VERSION ""

NS_ :

BS_:

BU_: TCM HCM IPMA_ADAS PSCM ABS_ESC TCCM TCM_DSL PCM_HEV PCM ECM_HEVDSL ECM_HEV ECM_Diesel ECM SIMA_DLCS BCMD_IPDB VDM CMR_DSMC SOBDMC_HPCM CHCM GWM _delete AWD_DLCM GENERIC TSTR

BO_ 2610126865 OTAPhysSOBDMCtoGWM_FD1: 64 SOBDMC_HPCM
 SG_ OTAPhysSOBDMCtoGWM_ECG : 7|29@0+ (1,0) [0|536870911] "unitless"  GWM

BO_ 2610971864 PARSEDPhysGWMtoSOBDMC_FD1: 64 GWM
 SG_ PARSEDPhysGWM_ECGtoSOBDMC : 7|29@0+ (1,0) [0|536870911] "unitless"  SOBDMC_HPCM

BO_ 2611175441 PARSEDPhysSOBDMCtoGWM_FD1: 64 SOBDMC_HPCM
 SG_ PARSEDPhysSOBDMCtoGWM_ECG : 7|29@0+ (1,0) [0|536870911] "unitless"  GWM

BO_ 2610126946 OTAPhysSODLtoGWM_ECG: 64 IPMA_ADAS
 SG_ OTAPhysSODLtoGWM_ECG : 7|29@0+ (1,0) [0|536870911] "unitless"  GWM

BO_ 2610006232 OTAPhysGWM_ECGtoSODL: 64 GWM
 SG_ OTAPhysGWM_ECGtoSODL : 7|29@0+ (1,0) [0|536870911] "unitless"  IPMA_ADAS

BO_ 1993 TesterPhysicalResCMR_DSMC: 64 CMR_DSMC
 SG_ TesterPhysicalResCMR_DSMC : 7|64@0+ (1,0) [0|1.84467E+019] "unitless"  TSTR

BO_ 1985 TesterPhysicalReqCMR_DSMC: 64 TSTR
 SG_ TesterPhysicalReqCMR_DSMC : 7|64@0+ (1,0) [0|1.84467E+019] "unitless"  CMR_DSMC

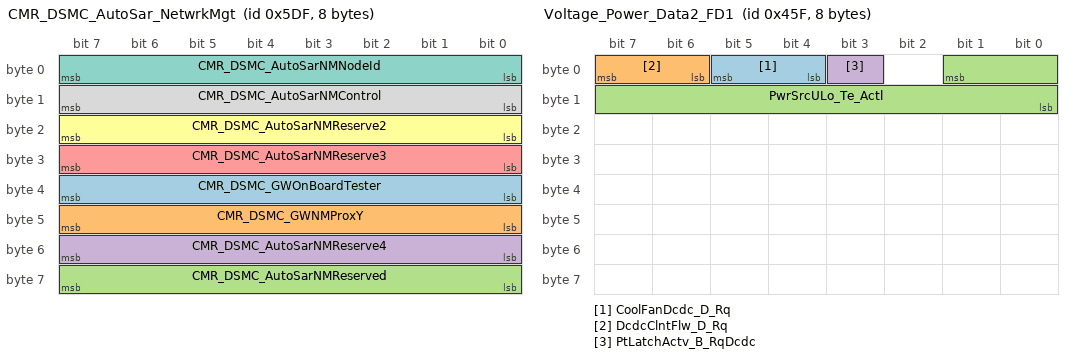
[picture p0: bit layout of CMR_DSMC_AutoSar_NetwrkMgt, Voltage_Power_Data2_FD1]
BO_ 1503 CMR_DSMC_AutoSar_NetwrkMgt: 8 CMR_DSMC
 SG_ CMR_DSMC_GWOnBoardTester : 39|8@0+ (1,0) [0|255] "unitless"  GENERIC
 SG_ CMR_DSMC_GWNMProxY : 47|8@0+ (1,0) [0|255] "unitless"  GENERIC
 SG_ CMR_DSMC_AutoSarNMReserved : 63|8@0+ (1,0) [0|255] "unitless"  GENERIC
 SG_ CMR_DSMC_AutoSarNMReserve4 : 55|8@0+ (1,0) [0|255] "unitless"  GENERIC
 SG_ CMR_DSMC_AutoSarNMReserve3 : 31|8@0+ (1,0) [0|255] "unitless"  GENERIC
 SG_ CMR_DSMC_AutoSarNMReserve2 : 23|8@0+ (1,0) [0|255] "unitless"  GENERIC
 SG_ CMR_DSMC_AutoSarNMNodeId : 7|8@0+ (1,0) [0|255] "unitless"  GENERIC
 SG_ CMR_DSMC_AutoSarNMControl : 15|8@0+ (1,0) [0|255] "unitless"  GENERIC

BO_ 1119 Voltage_Power_Data2_FD1: 8 DCDC_HEV
 SG_ CoolFanDcdc_D_Rq : 5|2@0+ (1,0) [0|3] "SED"  SOBDMC_HPCM
 SG_ DcdcClntFlw_D_Rq : 7|2@0+ (1,0) [0|3] "SED"  SOBDMC_HPCM
 SG_ PwrSrcULo_Te_Actl : 1|10@0+ (0.5,-50) [-50|460.5] "degC"  ECM_Diesel,ECM_HEV,ECM_HEVDSL,PCM_HEV
 SG_ PtLatchActv_B_RqDcdc : 3|1@0+ (1,0) [0|1] "SED"  ECM_Diesel,ECM_HEV,ECM_HEVDSL,PCM_HEV

BO_ 2022 TesterPhysicalReqSOBDMC_FD: 64 TSTR
 SG_ TesterPhysicalReqSOBDMC : 7|64@0+ (1,0) [0|1.84467E+019] "unitless"  ECM,ECM_Diesel,ECM_HEVDSL,SOBDMC_HPCM

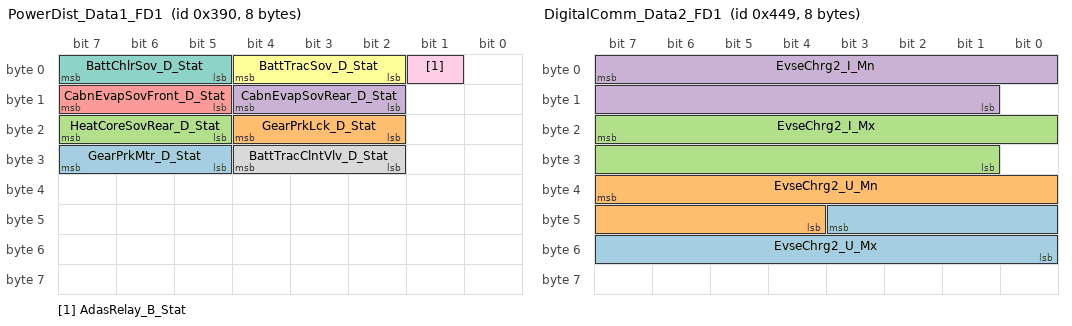
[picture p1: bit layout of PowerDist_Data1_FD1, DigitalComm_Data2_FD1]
BO_ 912 PowerDist_Data1_FD1: 8 GWM
 SG_ GearPrkMtr_D_Stat : 31|3@0+ (1,0) [0|7] "SED"  SOBDMC_HPCM,BCMD_IPDB
 SG_ GearPrkLck_D_Stat : 20|3@0+ (1,0) [0|7] "SED"  SOBDMC_HPCM,BCMD_IPDB
 SG_ HeatCoreSovRear_D_Stat : 23|3@0+ (1,0) [0|7] "SED"  SOBDMC_HPCM
 SG_ CabnEvapSovRear_D_Stat : 12|3@0+ (1,0) [0|7] "SED"  SOBDMC_HPCM
 SG_ CabnEvapSovFront_D_Stat : 15|3@0+ (1,0) [0|7] "SED"  SOBDMC_HPCM,BCMD_IPDB
 SG_ BattTracSov_D_Stat : 4|3@0+ (1,0) [0|7] "SED"  SOBDMC_HPCM
 SG_ BattChlrSov_D_Stat : 7|3@0+ (1,0) [0|7] "SED"  SOBDMC_HPCM,BCMD_IPDB
 SG_ BattTracClntVlv_D_Stat : 28|3@0+ (1,0) [0|7] "SED"  SOBDMC_HPCM,BCMD_IPDB
 SG_ AdasRelay_B_Stat : 1|1@0+ (1,0) [0|1] "SED"  GENERIC

BO_ 66 Global_PATS_Ctrl_Info2_FD1: 8 GWM
 SG_ immoControlData_T2 : 15|40@0+ (1,0) [0|1099511627775] "Encrypted"  GWM,SOBDMC_HPCM
 SG_ immoControlCmd_T2 : 7|3@0+ (1,0) [0|7] "SED"  GWM,SOBDMC_HPCM

BO_ 651 TCU_Send_Signals_FD1: 8 TCU_FB5
 SG_ TelematicsSrvc_D_St : 47|3@0+ (1,0) [0|7] "SED"  SOBDMC_HPCM
 SG_ EmgcyCallMute_D_Stat : 39|3@0+ (1,0) [0|7] "SED"  GENERIC

BO_ 1097 DigitalComm_Data2_FD1: 8 OBCC
 SG_ EvseChrg2_U_Mx : 43|12@0+ (0.5,0) [0|2046.5] "volt"  SOBDMC_HPCM
 SG_ EvseChrg2_U_Mn : 39|12@0+ (0.5,0) [0|2046.5] "volt"  GENERIC
 SG_ EvseChrg2_I_Mx : 23|15@0+ (0.05,0) [0|1638.25] "ampere"  SOBDMC_HPCM
 SG_ EvseChrg2_I_Mn : 7|15@0+ (0.05,0) [0|1638.25] "ampere"  GENERIC

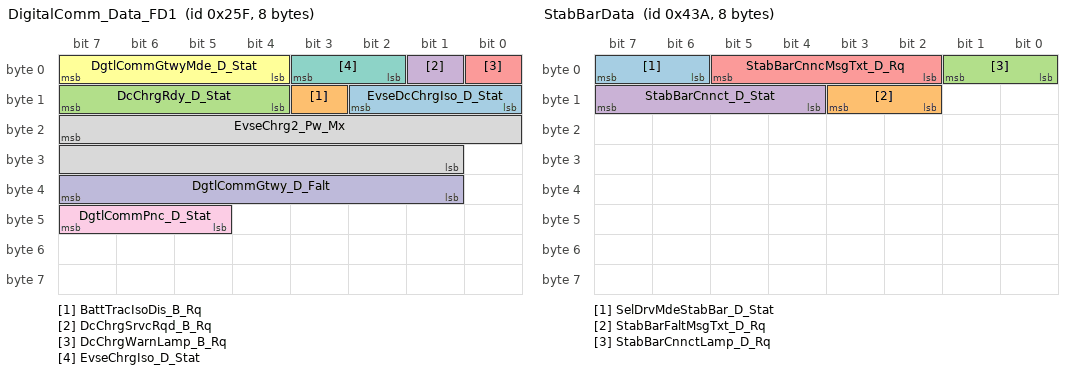
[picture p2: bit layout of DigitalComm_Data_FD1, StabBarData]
BO_ 607 DigitalComm_Data_FD1: 8 OBCC
 SG_ EvseDcChrgIso_D_Stat : 10|3@0+ (1,0) [0|7] "SED"  GENERIC
 SG_ BattTracIsoDis_B_Rq : 11|1@0+ (1,0) [0|1] "SED"  GENERIC
 SG_ DcChrgRdy_D_Stat : 15|4@0+ (1,0) [0|15] "SED"  SOBDMC_HPCM
 SG_ DcChrgSrvcRqd_B_Rq : 1|1@0+ (1,0) [0|1] "SED"  GENERIC
 SG_ DcChrgWarnLamp_B_Rq : 0|1@0+ (1,0) [0|1] "SED"  GENERIC
 SG_ DgtlCommGtwyMde_D_Stat : 7|4@0+ (1,0) [0|15] "SED"  GENERIC
 SG_ EvseChrgIso_D_Stat : 3|2@0+ (1,0) [0|3] "SED"  GENERIC
 SG_ EvseChrg2_Pw_Mx : 23|15@0+ (50,0) [0|1638250] "watts"  SOBDMC_HPCM
 SG_ DgtlCommPnc_D_Stat : 47|3@0+ (1,0) [0|7] "SED"  GENERIC
 SG_ DgtlCommGtwy_D_Falt : 39|7@0+ (1,0) [0|63] "SED"  GENERIC

BO_ 2609955032 OTAPhysGWM_ECGtoPSCM: 64 GWM
 SG_ OTAPhysGWM_ECGtoPSCM : 7|29@0+ (1,0) [0|536870911] "unitless"  PSCM

BO_ 2610126896 OTAPhysPSCMtoGWM_ECG: 64 PSCM
 SG_ OTAPhysPSCMtoGWM_ECG : 7|29@0+ (1,0) [0|536870911] "unitless"  GWM

BO_ 2611003608 PARSEDPhysGWM_ECGtoPSCM: 64 GWM
 SG_ PARSEDPhysGWM_ECGtoPSCM : 7|29@0+ (1,0) [0|536870911] "unitless"  PSCM

BO_ 2612224048 PARSEDPushPSCMtoGWM_ECG: 8 PSCM
 SG_ PARSEDPushPSCMtoGWM_ECG : 7|29@0+ (1,0) [0|536870911] "unitless"  GWM

BO_ 2611175472 PARSEDPhysPSCMtoGWM_ECG: 64 PSCM
 SG_ PARSEDPhysPSCMtoGWM_ECG : 7|29@0+ (1,0) [0|536870911] "unitless"  GWM

BO_ 1150 LocationServices_Data1_FD1: 8 APIM
 SG_ LocationServices_1 : 7|64@0+ (1,0) [0|1.84467440737096E+019] "unitless"  SOBDMC_HPCM,HCM,IPMA_ADAS,ABS_ESC

BO_ 2612224033 PARSEDPushIPMAtoGWM_ECG: 8 IPMA_ADAS
 SG_ PARSEDPushIPMAtoGWM_ECG : 7|29@0+ (1,0) [0|536870911] "unitless"  GWM

BO_ 2609939672 OTAPhysGWM_ECGtoIPMA: 64 GWM
 SG_ OTAPhysGWM_ECGtoIPMA : 7|29@0+ (1,0) [0|536870911] "unitless"  IPMA_ADAS

BO_ 2610126881 OTAPhysIPMAtoGWM_ECG: 64 IPMA_ADAS
 SG_ OTAPhysIPMAtoGWM_ECG : 7|29@0+ (1,0) [0|536870911] "unitless"  GWM

BO_ 2612043992 PARSEDPushFcGWM_ECGtoABS: 8 GWM
 SG_ PARSEDPushFcGWM_ECGtoABS : 7|29@0+ (1,0) [0|536870911] "unitless"  ABS_ESC

BO_ 2610995416 PARSEDPhysGWM_ECGtoABS: 64 GWM
 SG_ PARSEDPhysGWM_ECGtoABS : 7|29@0+ (1,0) [0|536870911] "unitless"  ABS_ESC

BO_ 2612224040 PARSEDPushABStoGWM_ECG: 8 ABS_ESC
 SG_ PARSEDPushABStoGWM_ECG : 7|29@0+ (1,0) [0|536870911] "unitless"  GWM

BO_ 2611175464 PARSEDPhysABStoGWM_ECG: 64 ABS_ESC
 SG_ PARSEDPhysABStoGWM_ECG : 7|29@0+ (1,0) [0|536870911] "Unitless"  GWM

BO_ 1082 StabBarData: 8 CHCM
 SG_ SelDrvMdeStabBar_D_Stat : 7|2@0+ (1,0) [0|3] "SED"  ABS_ESC
 SG_ StabBarFaltMsgTxt_D_Rq : 11|2@0+ (1,0) [0|3] "SED"  GWM
 SG_ StabBarCnnctLamp_D_Rq : 1|2@0+ (1,0) [0|3] "SED"  SIMA_DLCS,GWM
 SG_ StabBarCnnct_D_Stat : 15|4@0+ (1,0) [0|15] "SED"  VDM,GWM,ABS_ESC
 SG_ StabBarCnncMsgTxt_D_Rq : 5|4@0+ (1,0) [0|15] "SED"  GWM

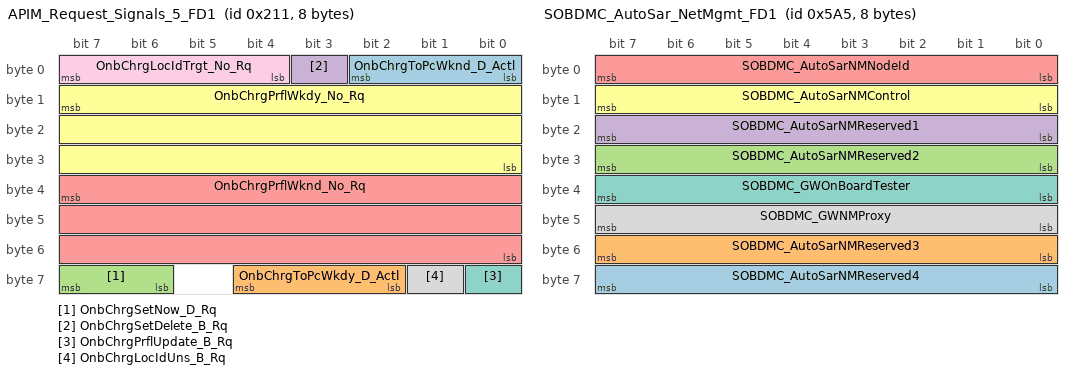
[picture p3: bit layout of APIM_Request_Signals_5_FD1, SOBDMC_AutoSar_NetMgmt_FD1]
BO_ 529 APIM_Request_Signals_5_FD1: 8 APIM
 SG_ OnbChrgToPcWknd_D_Actl : 2|3@0+ (1,0) [0|7] "percent"  SOBDMC_HPCM
 SG_ OnbChrgToPcWkdy_D_Actl : 60|3@0+ (1,0) [0|7] "percent"  SOBDMC_HPCM
 SG_ OnbChrgSetNow_D_Rq : 63|2@0+ (1,0) [0|3] "SED"  SOBDMC_HPCM
 SG_ OnbChrgSetDelete_B_Rq : 3|1@0+ (1,0) [0|1] "SED"  SOBDMC_HPCM
 SG_ OnbChrgPrflWknd_No_Rq : 39|24@0+ (1,0) [0|16777215] "unitless"  SOBDMC_HPCM
 SG_ OnbChrgPrflWkdy_No_Rq : 15|24@0+ (1,0) [0|16777215] "unitless"  SOBDMC_HPCM
 SG_ OnbChrgPrflUpdate_B_Rq : 56|1@0+ (1,0) [0|1] "SED"  SOBDMC_HPCM
 SG_ OnbChrgLocIdUns_B_Rq : 57|1@0+ (1,0) [0|1] "SED"  SOBDMC_HPCM
 SG_ OnbChrgLocIdTrgt_No_Rq : 7|4@0+ (1,0) [0|15] "Unitless"  SOBDMC_HPCM

BO_ 1679 SOBDMC_RapidData_Resp4_FD1: 8 SOBDMC_HPCM
 SG_ UUDTSOBDMCResponse4 : 7|64@0+ (1,0) [0|1.84467440737096E+019] "unitless"  TSTR

BO_ 1678 SOBDMC_RapidData_Resp3_FD1: 8 SOBDMC_HPCM
 SG_ UUDTSOBDMCResponse3 : 7|64@0+ (1,0) [0|1.84467440737096E+019] "unitless"  TSTR

BO_ 1677 SOBDMC_RapidData_Resp2_FD1: 8 SOBDMC_HPCM
 SG_ UUDTSOBDMCResponse2 : 7|64@0+ (1,0) [0|1.84467440737096E+019] "unitless"  TSTR

BO_ 1676 SOBDMC_RapidData_Resp1_FD1: 8 SOBDMC_HPCM
 SG_ UUDTSOBDMCResponse1 : 7|64@0+ (1,0) [0|1.84467440737096E+019] "unitless"  TSTR

BO_ 1445 SOBDMC_AutoSar_NetMgmt_FD1: 8 SOBDMC_HPCM
 SG_ SOBDMC_AutoSarNMReserved4 : 63|8@0+ (1,0) [0|255] "unitless"  ECM_HEV
 SG_ SOBDMC_AutoSarNMReserved3 : 55|8@0+ (1,0) [0|255] "unitless"  ECM_HEV
 SG_ SOBDMC_AutoSarNMReserved2 : 31|8@0+ (1,0) [0|255] "unitless"  ECM_HEV
 SG_ SOBDMC_AutoSarNMReserved1 : 23|8@0+ (1,0) [0|255] "unitless"  ECM_HEV
 SG_ SOBDMC_AutoSarNMNodeId : 7|8@0+ (1,0) [0|255] "unitless"  ECM_HEV
 SG_ SOBDMC_AutoSarNMControl : 15|8@0+ (1,0) [0|255] "unitless"  ECM_HEV
 SG_ SOBDMC_GWOnBoardTester : 39|8@0+ (1,0) [0|255] "unitless"  ECM_HEV
 SG_ SOBDMC_GWNMProxy : 47|8@0+ (1,0) [0|255] "unitless"  ECM_HEV

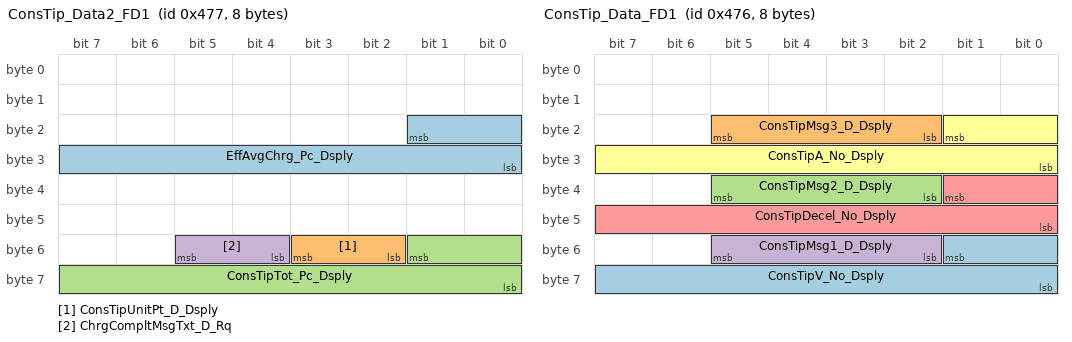
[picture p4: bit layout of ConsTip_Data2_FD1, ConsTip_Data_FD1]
BO_ 1143 ConsTip_Data2_FD1: 8 SOBDMC_HPCM
 SG_ EffAvgChrg_Pc_Dsply : 17|10@0+ (0.1,0) [0|102.3] "percent"  GWM
 SG_ ConsTipUnitPt_D_Dsply : 51|2@0+ (1,0) [0|3] "SED"  GWM
 SG_ ConsTipTot_Pc_Dsply : 49|10@0+ (0.1,0) [0|102.1] "percent"  GWM
 SG_ ChrgCompltMsgTxt_D_Rq : 53|2@0+ (1,0) [0|3] "SED"  GWM

BO_ 1142 ConsTip_Data_FD1: 8 SOBDMC_HPCM
 SG_ ConsTipV_No_Dsply : 49|10@0+ (0.1,0) [0|102.1] "percent"  GWM
 SG_ ConsTipMsg3_D_Dsply : 21|4@0+ (1,0) [0|15] "SED"  GWM
 SG_ ConsTipMsg2_D_Dsply : 37|4@0+ (1,0) [0|15] "SED"  GWM
 SG_ ConsTipMsg1_D_Dsply : 53|4@0+ (1,0) [0|15] "SED"  GWM
 SG_ ConsTipDecel_No_Dsply : 33|10@0+ (0.1,0) [0|102.1] "percent"  GWM
 SG_ ConsTipA_No_Dsply : 17|10@0+ (0.1,0) [0|102.1] "percent"  GWM

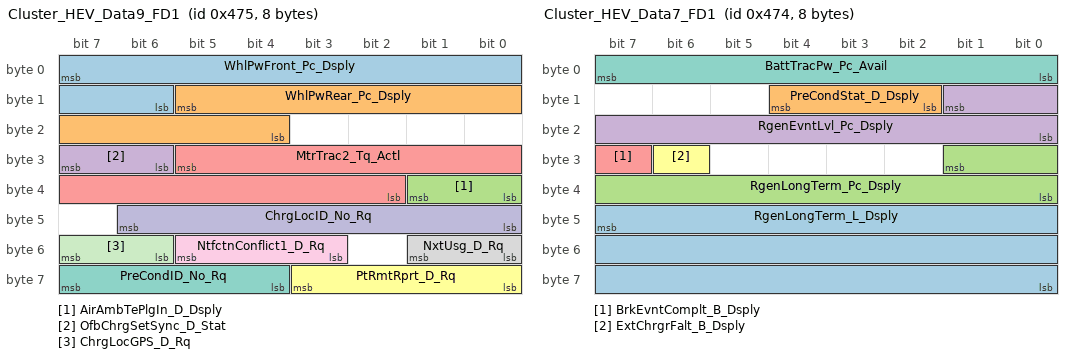
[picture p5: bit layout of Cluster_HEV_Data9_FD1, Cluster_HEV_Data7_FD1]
BO_ 1141 Cluster_HEV_Data9_FD1: 8 SOBDMC_HPCM
 SG_ WhlPwFront_Pc_Dsply : 7|10@0+ (0.2,-102.2) [-102.2|102.4] "percent"  GWM
 SG_ WhlPwRear_Pc_Dsply : 13|10@0+ (0.2,-102.2) [-102.2|102.4] "percent"  GWM
 SG_ AirAmbTePlgIn_D_Dsply : 33|2@0+ (1,0) [0|3] "SED"  GWM
 SG_ OfbChrgSetSync_D_Stat : 31|2@0+ (1,0) [0|3] "SED"  GWM
 SG_ MtrTrac2_Tq_Actl : 29|12@0+ (1,-2047) [-2047|2048] "Nm"  GWM
 SG_ PtRmtRprt_D_Rq : 59|4@0+ (1,0) [0|15] "SED"  GWM
 SG_ PreCondID_No_Rq : 63|4@0+ (1,0) [0|15] "unitless"  GWM
 SG_ NxtUsg_D_Rq : 49|2@0+ (1,0) [0|3] "SED"  GWM
 SG_ NtfctnConflict1_D_Rq : 53|3@0+ (1,0) [0|7] "SED"  GWM
 SG_ ChrgLocID_No_Rq : 46|7@0+ (1,0) [0|127] "unitless"  GWM
 SG_ ChrgLocGPS_D_Rq : 55|2@0+ (1,0) [0|3] "SED"  GWM

BO_ 1140 Cluster_HEV_Data7_FD1: 8 SOBDMC_HPCM
 SG_ RgenLongTerm_L_Dsply : 47|24@0+ (0.1,0) [0|1677721.3] "km"  GWM
 SG_ PreCondStat_D_Dsply : 12|3@0+ (1,0) [0|7] "SED"  GWM
 SG_ RgenLongTerm_Pc_Dsply : 25|10@0+ (0.1,0) [0|102.3] "percent"  GWM
 SG_ RgenEvntLvl_Pc_Dsply : 9|10@0+ (0.1,0) [0|102.1] "percent"  GWM
 SG_ BrkEvntComplt_B_Dsply : 31|1@0+ (1,0) [0|1] "SED"  GWM
 SG_ ExtChrgrFalt_B_Dsply : 30|1@0+ (1,0) [0|1] "SED"  GWM
 SG_ BattTracPw_Pc_Avail : 7|8@0+ (0.5,0) [0|126.5] "percent"  GWM

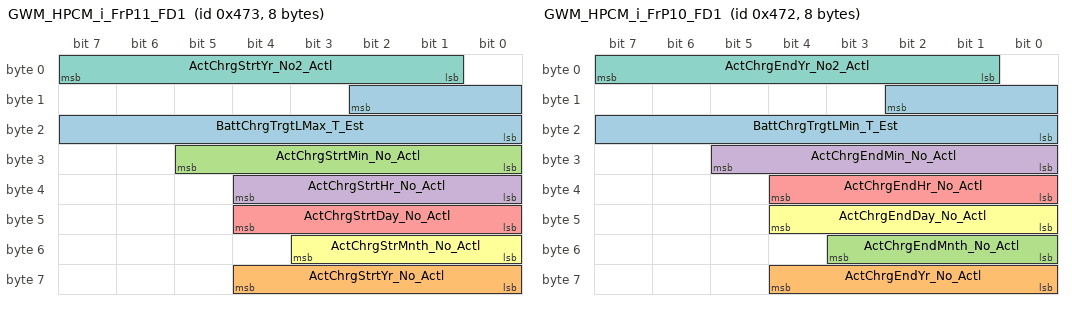
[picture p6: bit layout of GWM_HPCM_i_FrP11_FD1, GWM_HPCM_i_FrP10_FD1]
BO_ 1139 GWM_HPCM_i_FrP11_FD1: 8 SOBDMC_HPCM
 SG_ BattChrgTrgtLMax_T_Est : 10|11@0+ (1,0) [0|2045] "minute"  GWM
 SG_ ActChrgStrtYr_No_Actl : 60|5@0+ (1,2010) [2010|2040] "year"  GWM
 SG_ ActChrgStrtMin_No_Actl : 29|6@0+ (1,0) [0|61] "minute"  GWM
 SG_ ActChrgStrtHr_No_Actl : 36|5@0+ (1,0) [0|29] "hour"  GWM
 SG_ ActChrgStrtDay_No_Actl : 44|5@0+ (1,1) [1|31] "days"  GWM
 SG_ ActChrgStrMnth_No_Actl : 51|4@0+ (1,1) [1|15] "month"  GWM
 SG_ ActChrgStrtYr_No2_Actl : 7|7@0+ (1,2017) [2017|2144] "year"  GWM

BO_ 1138 GWM_HPCM_i_FrP10_FD1: 8 SOBDMC_HPCM
 SG_ BattChrgTrgtLMin_T_Est : 10|11@0+ (1,0) [0|2045] "minute"  GWM
 SG_ ActChrgEndYr_No_Actl : 60|5@0+ (1,2010) [2010|2040] "year"  GWM
 SG_ ActChrgEndMnth_No_Actl : 51|4@0+ (1,1) [1|15] "month"  GWM
 SG_ ActChrgEndMin_No_Actl : 29|6@0+ (1,0) [0|61] "minute"  GWM
 SG_ ActChrgEndHr_No_Actl : 36|5@0+ (1,0) [0|29] "hour"  GWM
 SG_ ActChrgEndDay_No_Actl : 44|5@0+ (1,1) [1|31] "days"  GWM
 SG_ ActChrgEndYr_No2_Actl : 7|7@0+ (1,2017) [2017|2144] "year"  GWM

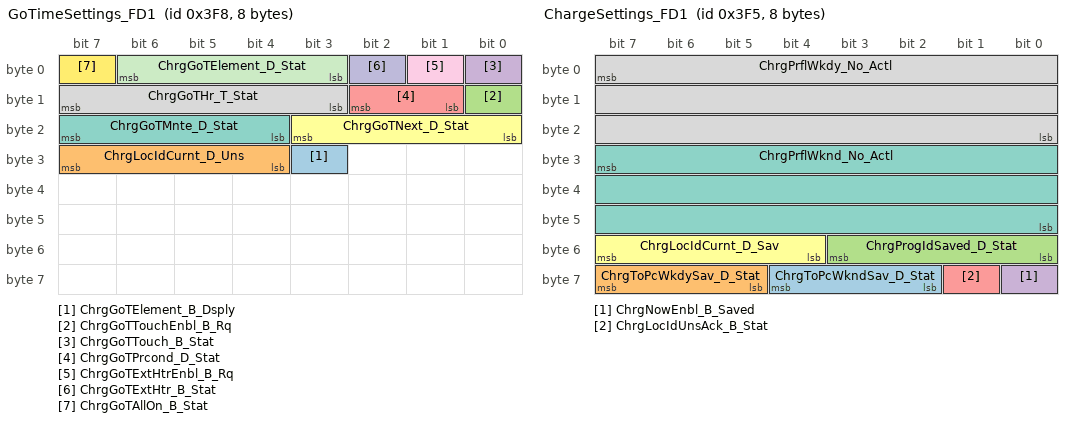
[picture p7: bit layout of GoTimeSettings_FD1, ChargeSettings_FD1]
BO_ 1016 GoTimeSettings_FD1: 8 SOBDMC_HPCM
 SG_ ChrgGoTElement_B_Dsply : 27|1@0+ (1,0) [0|1] "SED"  GWM
 SG_ ChrgLocIdCurnt_D_Uns : 31|4@0+ (1,0) [0|15] "unitless"  GWM
 SG_ ChrgGoTTouchEnbl_B_Rq : 8|1@0+ (1,0) [0|1] "SED"  GWM
 SG_ ChrgGoTTouch_B_Stat : 0|1@0+ (1,0) [0|1] "SED"  GWM
 SG_ ChrgGoTPrcond_D_Stat : 10|2@0+ (1,0) [0|3] "SED"  GWM
 SG_ ChrgGoTNext_D_Stat : 19|4@0+ (1,0) [0|15] "Unitless"  GWM
 SG_ ChrgGoTMnte_D_Stat : 23|4@0+ (1,0) [0|15] "SED"  GWM
 SG_ ChrgGoTHr_T_Stat : 15|5@0+ (1,0) [0|29] "hour"  GWM
 SG_ ChrgGoTExtHtrEnbl_B_Rq : 1|1@0+ (1,0) [0|1] "SED"  GWM
 SG_ ChrgGoTExtHtr_B_Stat : 2|1@0+ (1,0) [0|1] "SED"  GWM
 SG_ ChrgGoTElement_D_Stat : 6|4@0+ (1,0) [0|15] "Unitless"  GWM
 SG_ ChrgGoTAllOn_B_Stat : 7|1@0+ (1,0) [0|1] "SED"  GWM

BO_ 1013 ChargeSettings_FD1: 8 SOBDMC_HPCM
 SG_ ChrgToPcWkndSav_D_Stat : 60|3@0+ (1,0) [0|7] "SED"  GWM
 SG_ ChrgToPcWkdySav_D_Stat : 63|3@0+ (1,0) [0|7] "SED"  GWM
 SG_ ChrgProgIdSaved_D_Stat : 51|4@0+ (1,0) [0|15] "Unitless"  GWM
 SG_ ChrgNowEnbl_B_Saved : 56|1@0+ (1,0) [0|1] "SED"  GWM
 SG_ ChrgLocIdUnsAck_B_Stat : 57|1@0+ (1,0) [0|1] "SED"  GWM
 SG_ ChrgLocIdCurnt_D_Sav : 55|4@0+ (1,0) [0|15] "unitless"  GWM
 SG_ ChrgPrflWknd_No_Actl : 31|24@0+ (1,0) [0|16777215] "unitless"  GWM
 SG_ ChrgPrflWkdy_No_Actl : 7|24@0+ (1,0) [0|16777215] "unitless"  GWM

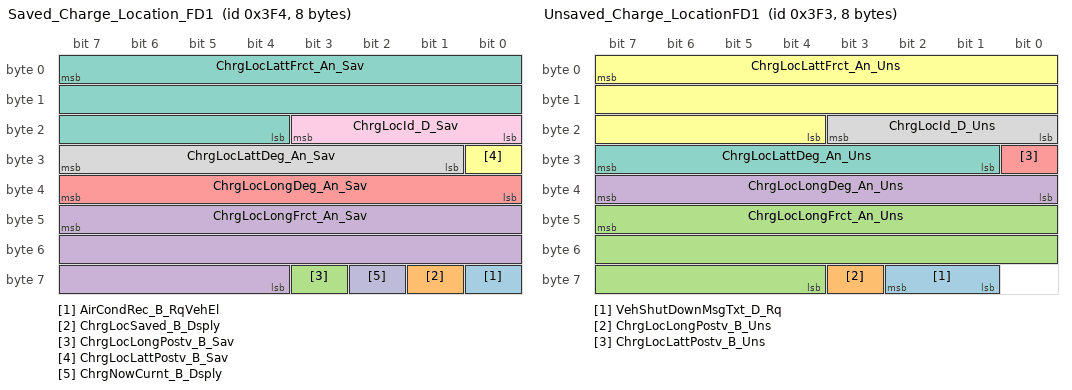
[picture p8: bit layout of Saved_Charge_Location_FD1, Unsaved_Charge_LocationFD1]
BO_ 1012 Saved_Charge_Location_FD1: 8 SOBDMC_HPCM
 SG_ AirCondRec_B_RqVehEl : 56|1@0+ (1,0) [0|1] "SED"  GWM
 SG_ ChrgLocSaved_B_Dsply : 57|1@0+ (1,0) [0|1] "SED"  GWM
 SG_ ChrgLocLongPostv_B_Sav : 59|1@0+ (1,0) [0|1] "SED"  GWM
 SG_ ChrgLocLongFrct_An_Sav : 47|20@0+ (1E-006,0) [0|1.048575] "degrees"  GWM
 SG_ ChrgLocLongDeg_An_Sav : 39|8@0+ (1,0) [0|255] "degrees"  GWM
 SG_ ChrgLocLattPostv_B_Sav : 24|1@0+ (1,0) [0|1] "SED"  GWM
 SG_ ChrgLocLattFrct_An_Sav : 7|20@0+ (1E-006,0) [0|1.048575] "degrees"  GWM
 SG_ ChrgLocLattDeg_An_Sav : 31|7@0+ (1,0) [0|127] "unitless"  GWM
 SG_ ChrgLocId_D_Sav : 19|4@0+ (1,0) [0|15] "unitless"  GWM
 SG_ ChrgNowCurnt_B_Dsply : 58|1@0+ (1,0) [0|1] "SED"  GWM

BO_ 1011 Unsaved_Charge_LocationFD1: 8 SOBDMC_HPCM
 SG_ VehShutDownMsgTxt_D_Rq : 58|2@0+ (1,0) [0|3] "SED"  GWM
 SG_ ChrgLocLongPostv_B_Uns : 59|1@0+ (1,0) [0|1] "SED"  GWM
 SG_ ChrgLocLongFrct_An_Uns : 47|20@0+ (1E-006,0) [0|1.048575] "degrees"  GWM
 SG_ ChrgLocLongDeg_An_Uns : 39|8@0+ (1,0) [0|255] "degrees"  GWM
 SG_ ChrgLocLattPostv_B_Uns : 24|1@0+ (1,0) [0|1] "SED"  GWM
 SG_ ChrgLocLattFrct_An_Uns : 7|20@0+ (1E-006,0) [0|1.048575] "degrees"  GWM
 SG_ ChrgLocLattDeg_An_Uns : 31|7@0+ (1,0) [0|127] "unitless"  GWM
 SG_ ChrgLocId_D_Uns : 19|4@0+ (1,0) [0|15] "unitless"  GWM

BO_ 1049 APIMSDMsignals_FD1: 8 APIM
 SG_ TrlrId_No_ActlMnu : 31|4@0+ (1,0) [0|15] "unitless"  SOBDMC_HPCM
 SG_ TrlrRngId_No_RqReset : 27|4@0+ (1,0) [0|15] "unitless"  SOBDMC_HPCM
 SG_ DcacZone3PwBttn_B_Stat : 34|1@0+ (1,0) [0|1] "SED"  ECM_HEV
 SG_ DcacZone2PwBttn_B_Stat : 35|1@0+ (1,0) [0|1] "SED"  ECM_HEV
 SG_ DcacPwResetBtn2_B_Stat : 36|1@0+ (1,0) [0|1] "SED"  ECM_HEV
 SG_ DcacPwOffButtn2_B_Stat : 37|1@0+ (1,0) [0|1] "SED"  ECM_HEV
 SG_ DcacPwHiButtn2_B_Stat : 38|1@0+ (1,0) [0|1] "SED"  ECM_HEV
 SG_ DcacGfciTestBtn2_B_Stat : 39|1@0+ (1,0) [0|1] "SED"  ECM_HEV
 SG_ DcacAllZoneBttn_B_Stat : 16|1@0+ (1,0) [0|1] "SED"  ECM_HEV
 SG_ DcacChime_D_Rq : 18|2@0+ (1,0) [0|3] "SED"  GENERIC
 SG_ Fba_D_Rq : 57|2@0+ (1,0) [0|3] "SED"  IPMA_ADAS
 SG_ ExtLghtAnmtn_D_Rq : 61|4@0+ (1,0) [0|15] "SED"  HCM
 SG_ Chrgr_Pw_EstMx : 55|9@0+ (2,0) [0|1018] "kilowatt"  SOBDMC_HPCM
 SG_ LnchCtl_N_Rq2 : 47|8@0+ (50,0) [0|12750] "rpm"  ABS_ESC,PCM
 SG_ LnchCtl_D_Rq2 : 33|2@0+ (1,0) [0|3] "SED"  ABS_ESC,PCM
 SG_ PersTurnSglView_D_RqMnu : 20|2@0+ (1,0) [0|3] "SED"  IPMA_ADAS
 SG_ FrontDiffLck_D_RqDrv3 : 11|2@0+ (1,0) [0|3] "SED"  GENERIC
 SG_ RearDiffLck_D_RqDrv3 : 9|2@0+ (1,0) [0|3] "SED"  SOBDMC_HPCM
 SG_ TrailCtlSwtch_B_Stat4 : 21|1@0+ (1,0) [0|1] "SED"  ABS_ESC
 SG_ CamraFrnt_B_RqMnu : 12|1@0+ (1,0) [0|1] "SED"  IPMA_ADAS
 SG_ StabBarCnncButtn_D_Sta3 : 23|2@0+ (1,0) [0|3] "SED"  GENERIC
 SG_ TurnAsstSwtch_D_Stat : 14|2@0+ (1,0) [0|3] "SED"  ABS_ESC
 SG_ SelDrvMdeTxtRst_B_Rq2 : 15|1@0+ (1,0) [0|1] "SED"  ABS_ESC
 SG_ SelDrvMdePage_B_Stat : 0|1@0+ (1,0) [0|1] "SED"  ABS_ESC
 SG_ SelDrvMdeCnfm_D_Stat2 : 2|2@0+ (1,0) [0|3] "SED"  ABS_ESC
 SG_ SelDrvMde_D_RqDrv : 7|5@0+ (1,0) [0|31] "SED"  ABS_ESC

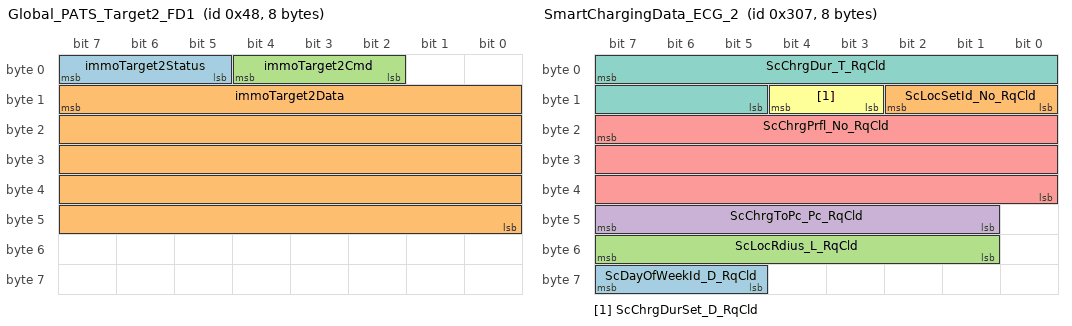
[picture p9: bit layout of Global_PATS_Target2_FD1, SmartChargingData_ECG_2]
BO_ 72 Global_PATS_Target2_FD1: 8 SOBDMC_HPCM
 SG_ immoTarget2Status : 7|3@0+ (1,0) [0|7] "SED"  GWM
 SG_ immoTarget2Data : 15|40@0+ (1,0) [0|1099511627775] "Encrypted"  GWM
 SG_ immoTarget2Cmd : 4|3@0+ (1,0) [0|7] "SED"  GWM

BO_ 2611175457 PARSEDPhysIPMAtoGWM_ECG: 64 IPMA_ADAS
 SG_ PARSEDPhysIPMAtoGWM_ECG : 7|29@0+ (1,0) [0|536870911] "unitless"  GWM

BO_ 2609946840 OTAPhysGWM_ECGtoABS: 64 GWM
 SG_ OTAPhysGWM_ECGtoABS : 7|29@0+ (1,0) [0|536870911] "unitless"  ABS_ESC

BO_ 2610126888 OTAPhysABStoGWM_ECG: 64 ABS_ESC
 SG_ OTAPhysABStoGWM_ECG : 7|29@0+ (1,0) [0|536870911] "unitless"  GWM

BO_ 2611175440 PARSEDPhysPCMtoGWM_ECG: 64 PCM_HEV
 SG_ PARSEDPhysPCMtoGWM_ECG : 7|29@0+ (1,0) [0|536870911] "unitless"  GWM

BO_ 2609922264 OTAPhysGWM_ECGtoPCM: 64 GWM
 SG_ OTAPhysGWM_ECGtoPCM : 7|29@0+ (1,0) [0|536870911] "unitless"  ECM,ECM_Diesel,ECM_HEV,ECM_HEVDSL,PCM,PCM_HEV,SOBDMC_HPCM

BO_ 2610953432 OTAFuncGWM_ECG_FD1: 64 GWM
 SG_ OTAFuncGWM_ECG : 7|29@0+ (1,0) [0|536870911] "unitless"  VDM,ABS_ESC,AWD_DLCM,CHCM,HCM,IPMA_ADAS,PSCM,SOBDMC_HPCM,TCCM,TCM_DSL,ECM,ECM_Diesel,ECM_HEV,ECM_HEVDSL,PCM,PCM_HEV,CMR_DSMC

BO_ 2610126864 OTAPhysPCMtoGWM_ECG: 64 PCM_HEV
 SG_ OTAPhysPCMtoGWM_ECG : 7|29@0+ (1,0) [0|536870911] "unitless"  GWM

BO_ 2612002008 PARSEDFuncGWM_ECG_FD1: 64 GWM
 SG_ PARSEDFuncGWM_ECG : 7|29@0+ (1,0) [0|536870911] "unitless"  VDM,SOBDMC_HPCM,ABS_ESC,AWD_DLCM,CHCM,HCM,IPMA_ADAS,PSCM,TCCM,TCM_DSL,ECM,ECM_Diesel,ECM_HEV,ECM_HEVDSL,PCM,PCM_HEV,CMR_DSMC

BO_ 2610970840 PARSEDPhysGWM_ECGtoPCM: 64 GWM
 SG_ PARSEDPhysGWM_ECGtoPCM : 7|29@0+ (1,0) [0|536870911] "unitless"  ECM,ECM_Diesel,ECM_HEV,ECM_HEVDSL,PCM,PCM_HEV,SOBDMC_HPCM

BO_ 2612224016 PARSEDPushPCMtoGWM_ECG: 8 PCM_HEV
 SG_ PARSEDPushPCMtoGWM_ECG : 7|29@0+ (1,0) [0|536870911] "unitless"  GWM

BO_ 775 SmartChargingData_ECG_2: 8 GWM
 SG_ ScDayOfWeekId_D_RqCld : 63|3@0+ (1,0) [0|7] "SED"  SOBDMC_HPCM
 SG_ ScLocSetId_No_RqCld : 10|3@0+ (1,0) [0|7] "unitless"  SOBDMC_HPCM
 SG_ ScLocRdius_L_RqCld : 55|7@0+ (100,0) [0|12700] "meter"  SOBDMC_HPCM
 SG_ ScChrgToPc_Pc_RqCld : 47|7@0+ (1,0) [0|127] "percent"  SOBDMC_HPCM
 SG_ ScChrgPrfl_No_RqCld : 23|24@0+ (1,0) [0|16777215] "unitless"  SOBDMC_HPCM
 SG_ ScChrgDurSet_D_RqCld : 12|2@0+ (1,0) [0|3] "SED"  SOBDMC_HPCM
 SG_ ScChrgDur_T_RqCld : 7|11@0+ (1,0) [0|2045] "minute"  SOBDMC_HPCM

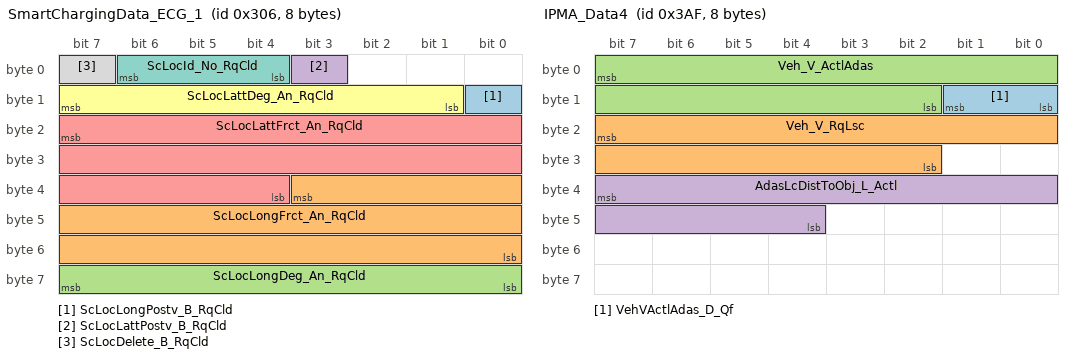
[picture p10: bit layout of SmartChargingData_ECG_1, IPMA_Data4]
BO_ 774 SmartChargingData_ECG_1: 8 GWM
 SG_ ScLocLongPostv_B_RqCld : 8|1@0+ (1,0) [0|1] "SED"  SOBDMC_HPCM
 SG_ ScLocLongFrct_An_RqCld : 35|20@0+ (1E-006,0) [0|1.048575] "degrees"  SOBDMC_HPCM
 SG_ ScLocLongDeg_An_RqCld : 63|8@0+ (1,0) [0|255] "degrees"  SOBDMC_HPCM
 SG_ ScLocLattPostv_B_RqCld : 3|1@0+ (1,0) [0|1] "SED"  SOBDMC_HPCM
 SG_ ScLocLattFrct_An_RqCld : 23|20@0+ (1E-006,0) [0|1.048575] "degrees"  SOBDMC_HPCM
 SG_ ScLocLattDeg_An_RqCld : 15|7@0+ (1,0) [0|127] "percent"  SOBDMC_HPCM
 SG_ ScLocId_No_RqCld : 6|3@0+ (1,0) [0|7] "unitless"  SOBDMC_HPCM
 SG_ ScLocDelete_B_RqCld : 7|1@0+ (1,0) [0|1] "SED"  SOBDMC_HPCM

BO_ 943 IPMA_Data4: 8 IPMA_ADAS
 SG_ VehVActlAdas_D_Qf : 9|2@0+ (1,0) [0|3] "SED"  ECM_HEV,ECM_Diesel,PCM,PCM_HEV
 SG_ Veh_V_RqLsc : 23|14@0+ (0.01,0) [0|163.83] "kph"  ECM_HEV,ECM_Diesel,PCM,PCM_HEV
 SG_ Veh_V_ActlAdas : 7|14@0+ (0.01,0) [0|163.83] "kph"  ECM_HEV,ECM_Diesel,PCM,PCM_HEV
 SG_ AdasLcDistToObj_L_Actl : 39|12@0+ (0.002,0) [0|8.186] "meter"  ECM_HEV,ECM_Diesel,PCM,PCM_HEV

BO_ 1816 TesterPhysicalResCHCM: 64 CHCM
 SG_ TesterPhysicalResCHCM : 7|64@0+ (1,0) [0|1.84467E+019] "unitless"  TSTR

BO_ 1808 TesterPhysicalReqCHCM: 64 TSTR
 SG_ TesterPhysicalReqCHCM : 7|64@0+ (1,0) [0|1.84467E+019] "unitless"  CHCM

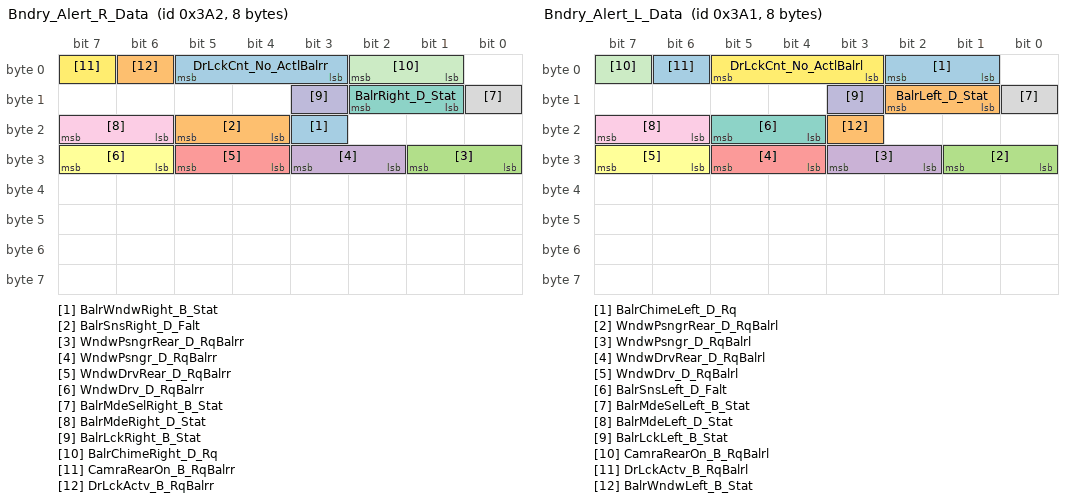
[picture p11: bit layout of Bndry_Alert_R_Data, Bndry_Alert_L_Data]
BO_ 930 Bndry_Alert_R_Data: 8 IPMA_ADAS
 SG_ BalrWndwRight_B_Stat : 19|1@0+ (1,0) [0|1] "SED"  GWM
 SG_ BalrSnsRight_D_Falt : 21|2@0+ (1,0) [0|3] "SED"  GWM
 SG_ WndwPsngrRear_D_RqBalrr : 25|2@0+ (1,0) [0|3] "SED"  GWM
 SG_ WndwPsngr_D_RqBalrr : 27|2@0+ (1,0) [0|3] "SED"  GWM
 SG_ WndwDrvRear_D_RqBalrr : 29|2@0+ (1,0) [0|3] "SED"  GWM
 SG_ WndwDrv_D_RqBalrr : 31|2@0+ (1,0) [0|3] "SED"  GWM
 SG_ BalrRight_D_Stat : 10|2@0+ (1,0) [0|3] "SED"  GWM
 SG_ BalrMdeSelRight_B_Stat : 8|1@0+ (1,0) [0|1] "SED"  GWM
 SG_ BalrMdeRight_D_Stat : 23|2@0+ (1,0) [0|3] "SED"  GWM
 SG_ BalrLckRight_B_Stat : 11|1@0+ (1,0) [0|1] "SED"  GWM
 SG_ BalrChimeRight_D_Rq : 2|2@0+ (1,0) [0|3] "SED"  GWM
 SG_ CamraRearOn_B_RqBalrr : 7|1@0+ (1,0) [0|1] "SED"  GWM
 SG_ DrLckCnt_No_ActlBalrr : 5|3@0+ (1,0) [0|7] "unitless"  GWM
 SG_ DrLckActv_B_RqBalrr : 6|1@0+ (1,0) [0|1] "SED"  GWM

BO_ 929 Bndry_Alert_L_Data: 8 IPMA_ADAS
 SG_ BalrChimeLeft_D_Rq : 2|2@0+ (1,0) [0|3] "SED"  GWM
 SG_ BalrLeft_D_Stat : 10|2@0+ (1,0) [0|3] "SED"  GWM
 SG_ WndwPsngrRear_D_RqBalrl : 25|2@0+ (1,0) [0|3] "SED"  GWM
 SG_ WndwPsngr_D_RqBalrl : 27|2@0+ (1,0) [0|3] "SED"  GWM
 SG_ WndwDrvRear_D_RqBalrl : 29|2@0+ (1,0) [0|3] "SED"  GWM
 SG_ WndwDrv_D_RqBalrl : 31|2@0+ (1,0) [0|3] "SED"  GWM
 SG_ BalrSnsLeft_D_Falt : 21|2@0+ (1,0) [0|3] "SED"  GWM
 SG_ BalrMdeSelLeft_B_Stat : 8|1@0+ (1,0) [0|1] "SED"  GWM
 SG_ BalrMdeLeft_D_Stat : 23|2@0+ (1,0) [0|3] "SED"  GWM
 SG_ BalrLckLeft_B_Stat : 11|1@0+ (1,0) [0|1] "SED"  GWM
 SG_ CamraRearOn_B_RqBalrl : 7|1@0+ (1,0) [0|1] "SED"  GWM
 SG_ DrLckCnt_No_ActlBalrl : 5|3@0+ (1,0) [0|7] "unitless"  GWM
 SG_ DrLckActv_B_RqBalrl : 6|1@0+ (1,0) [0|1] "SED"  GWM
 SG_ BalrWndwLeft_B_Stat : 19|1@0+ (1,0) [0|1] "SED"  GWM

BO_ 1783 TesterPhysicalReqLDCMB: 64 TSTR
 SG_ TesterPhysicalReqLDCMB : 7|64@0+ (1,0) [0|1.84467E+019] "unitless"  HCM

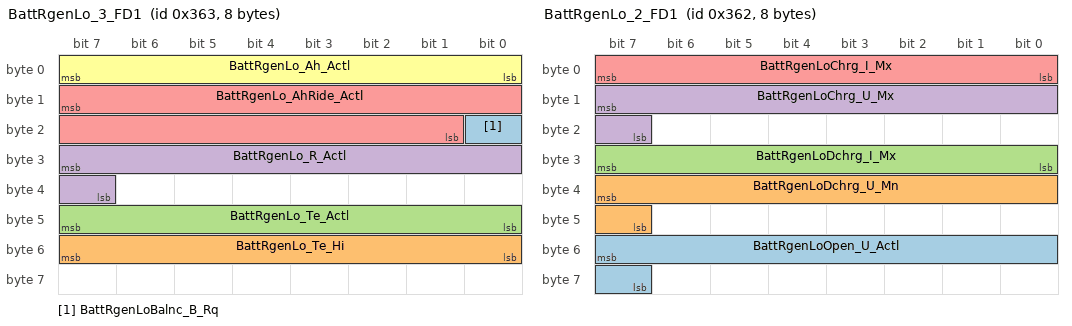
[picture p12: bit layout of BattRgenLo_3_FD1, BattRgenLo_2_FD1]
BO_ 867 BattRgenLo_3_FD1: 8 DCDC_LISB
 SG_ BattRgenLoBalnc_B_Rq : 16|1@0+ (1,0) [0|1] "SED"  PCM_HEV,PCM
 SG_ BattRgenLo_Te_Hi : 55|8@0+ (1,-20) [-20|235] "degC"  PCM_HEV,PCM
 SG_ BattRgenLo_Te_Actl : 47|8@0+ (1,-60) [-60|194] "degC"  PCM_HEV,PCM
 SG_ BattRgenLo_R_Actl : 31|9@0+ (0.0625,0) [0|31.9375] "milliohm"  PCM_HEV,PCM
 SG_ BattRgenLo_AhRide_Actl : 15|15@0+ (0.0078125,-100) [-100|155.9921875] "amperehour"  PCM_HEV,PCM
 SG_ BattRgenLo_Ah_Actl : 7|8@0+ (0.1,0) [0|25.5] "amperehour"  PCM_HEV,PCM

BO_ 866 BattRgenLo_2_FD1: 8 DCDC_LISB
 SG_ BattRgenLoOpen_U_Actl : 55|9@0+ (0.025,8.5) [8.5|21.275] "volt"  PCM_HEV,PCM
 SG_ BattRgenLoDchrg_U_Mn : 39|9@0+ (0.025,4) [4|16.775] "volt"  PCM_HEV,PCM
 SG_ BattRgenLoDchrg_I_Mx : 31|8@0+ (2,0) [0|510] "ampere"  PCM_HEV,PCM
 SG_ BattRgenLoChrg_U_Mx : 15|9@0+ (0.025,10.6) [10.6|23.375] "volt"  PCM_HEV,PCM
 SG_ BattRgenLoChrg_I_Mx : 7|8@0+ (2,0) [0|510] "ampere"  PCM_HEV,PCM

BO_ 865 BattRgenLo_1_FD1: 8 DCDC_LISB
 SG_ BattRgenLo_U_Actl : 23|11@0+ (0.015625,0) [0|31.96875] "volt"  PCM_HEV,PCM
 SG_ BattRgenLo_I_Actl : 7|16@0+ (0.015625,-512) [-512|511.96875] "ampere"  PCM_HEV,PCM

BO_ 2612194520 PARSEDPushFcGWM_ECGtoCMR: 8 GWM
 SG_ PARSEDPushFcGWM_ECGtoCMR : 7|29@0+ (1,0) [0|536870911] "unitless"  CMR_DSMC

BO_ 2610127035 OTAPhysCMRtoGWM_ECG: 64 CMR_DSMC
 SG_ OTAPhysCMRtoGWM_ECG : 7|29@0+ (1,0) [0|536870911] "unitless"  GWM

BO_ 2610097368 OTAPhysGWM_ECGtoCMR: 64 GWM
 SG_ OTAPhysGWM_ECGtoCMR : 7|29@0+ (1,0) [0|536870911] "unitless"  CMR_DSMC

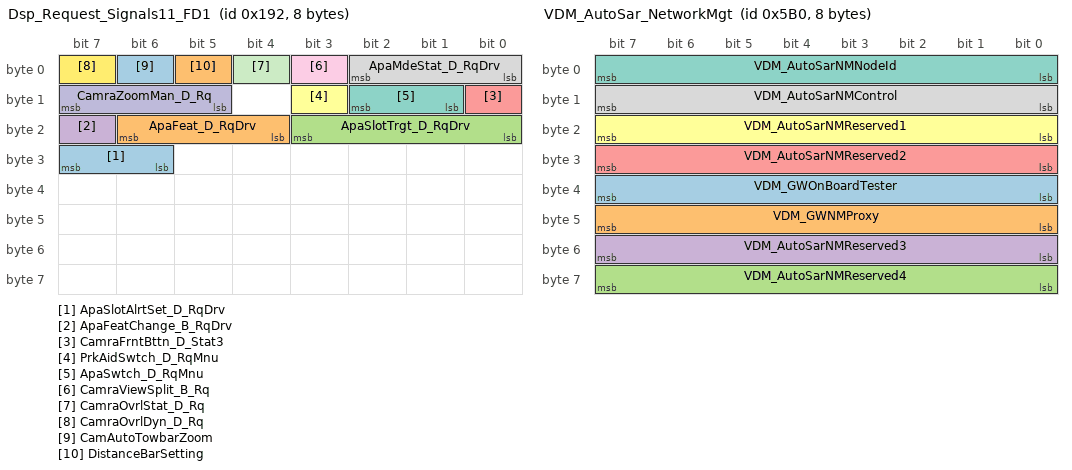
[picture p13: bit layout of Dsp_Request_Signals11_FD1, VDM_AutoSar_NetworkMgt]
BO_ 402 Dsp_Request_Signals11_FD1: 8 APIM_CISM
 SG_ ApaSlotAlrtSet_D_RqDrv : 31|2@0+ (1,0) [0|3] "SED"  IPMA_ADAS
 SG_ ApaFeat_D_RqDrv : 22|3@0+ (1,0) [0|7] "SED"  IPMA_ADAS
 SG_ ApaSlotTrgt_D_RqDrv : 19|4@0+ (1,0) [0|15] "SED"  IPMA_ADAS
 SG_ ApaFeatChange_B_RqDrv : 23|1@0+ (1,0) [0|1] "SED"  IPMA_ADAS
 SG_ CamraFrntBttn_D_Stat3 : 8|1@0+ (1,0) [0|1] "SED"  IPMA_ADAS
 SG_ PrkAidSwtch_D_RqMnu : 11|1@0+ (1,0) [0|1] "SED"  IPMA_ADAS
 SG_ ApaSwtch_D_RqMnu : 10|2@0+ (1,0) [0|3] "SED"  IPMA_ADAS
 SG_ ApaMdeStat_D_RqDrv : 2|3@0+ (1,0) [0|7] "SED"  IPMA_ADAS
 SG_ CamraViewSplit_B_Rq : 3|1@0+ (1,0) [0|1] "SED"  GENERIC
 SG_ CamraZoomMan_D_Rq : 15|3@0+ (1,0) [0|7] "SED"  GENERIC
 SG_ CamraOvrlStat_D_Rq : 4|1@0+ (1,0) [0|1] "SED"  GENERIC
 SG_ CamraOvrlDyn_D_Rq : 7|1@0+ (1,0) [0|1] "SED"  GENERIC
 SG_ CamAutoTowbarZoom : 6|1@0+ (1,0) [0|1] "SED"  GENERIC
 SG_ DistanceBarSetting : 5|1@0+ (1,0) [0|1] "SED"  GENERIC

BO_ 2611145944 PARSEDPhyGWM_ECGtoCMR: 64 GWM
 SG_ PARSEDPhysGWM_ECGtoCMR : 7|29@0+ (1,0) [0|536870911] "unitless"  CMR_DSMC

BO_ 2611175611 PARSEDPhysCMRtoGWM_ECG: 64 CMR_DSMC
 SG_ PARSEDPhysCMRtoGWM_ECG : 7|29@0+ (1,0) [0|536870911] "unitless"  GWM

BO_ 1456 VDM_AutoSar_NetworkMgt: 8 VDM
 SG_ VDM_GWOnBoardTester : 39|8@0+ (1,0) [0|255] "unitless"  HCM,GWM,GENERIC
 SG_ VDM_GWNMProxy : 47|8@0+ (1,0) [0|255] "unitless"  HCM,GWM,GENERIC
 SG_ VDM_AutoSarNMReserved4 : 63|8@0+ (1,0) [0|255] "unitless"  HCM,GWM,GENERIC
 SG_ VDM_AutoSarNMReserved3 : 55|8@0+ (1,0) [0|255] "unitless"  HCM,GWM,GENERIC
 SG_ VDM_AutoSarNMReserved2 : 31|8@0+ (1,0) [0|255] "unitless"  HCM,GWM,GENERIC
 SG_ VDM_AutoSarNMReserved1 : 23|8@0+ (1,0) [0|255] "unitless"  HCM,GWM,GENERIC
 SG_ VDM_AutoSarNMNodeId : 7|8@0+ (1,0) [0|255] "unitless"  HCM,GWM,GENERIC
 SG_ VDM_AutoSarNMControl : 15|8@0+ (1,0) [0|255] "unitless"  HCM,GWM,GENERIC

BO_ 1782 TesterPhysicalReqLDCMA: 64 TSTR
 SG_ TesterPhysicalReqLDCMA : 7|64@0+ (1,0) [0|1.84467E+019] "unitless"  HCM

BO_ 1791 TesterPhysicalResLDCMB: 64 HCM
 SG_ TesterPhysicalResLDCMB : 7|64@0+ (1,0) [0|1.84467E+019] "unitless"  TSTR

BO_ 1790 TesterPhysicalResLDCMA: 64 HCM
 SG_ TesterPhysicalResLDCMA : 7|64@0+ (1,0) [0|1.84467E+019] "unitless"  TSTR

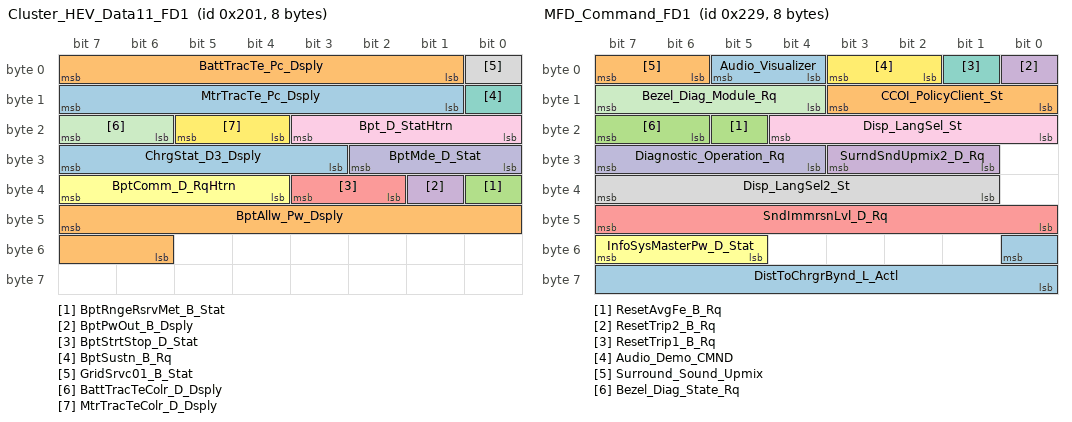
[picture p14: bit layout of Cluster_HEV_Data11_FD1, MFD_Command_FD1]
BO_ 513 Cluster_HEV_Data11_FD1: 8 SOBDMC_HPCM
 SG_ ChrgStat_D3_Dsply : 31|5@0+ (1,0) [0|31] "SED"  GWM
 SG_ BptAllw_Pw_Dsply : 47|10@0+ (0.1,0) [0|102.1] "kilowatt"  GWM
 SG_ BptRngeRsrvMet_B_Stat : 32|1@0+ (1,0) [0|1] "SED"  GWM
 SG_ BptPwOut_B_Dsply : 33|1@0+ (1,0) [0|1] "SED"  GWM
 SG_ BptStrtStop_D_Stat : 35|2@0+ (1,0) [0|3] "SED"  GWM
 SG_ BptComm_D_RqHtrn : 39|4@0+ (1,0) [0|15] "SED"  GWM
 SG_ BptSustn_B_Rq : 8|1@0+ (1,0) [0|1] "SED"  GWM
 SG_ GridSrvc01_B_Stat : 0|1@0+ (1,0) [0|1] "SED"  GWM
 SG_ Bpt_D_StatHtrn : 19|4@0+ (1,0) [0|15] "SED"  ECM_HEV,GWM
 SG_ BptMde_D_Stat : 26|3@0+ (1,0) [0|7] "SED"  GWM
 SG_ BattTracTeColr_D_Dsply : 23|2@0+ (1,0) [0|3] "SED"  GWM
 SG_ MtrTracTeColr_D_Dsply : 21|2@0+ (1,0) [0|3] "SED"  GWM
 SG_ MtrTracTe_Pc_Dsply : 15|7@0+ (1,0) [0|127] "percent"  GWM
 SG_ BattTracTe_Pc_Dsply : 7|7@0+ (1,0) [0|127] "percent"  GWM

BO_ 553 MFD_Command_FD1: 8 APIM
 SG_ DistToChrgrBynd_L_Actl : 48|9@0+ (1,0) [0|509] "kilometer"  SOBDMC_HPCM
 SG_ CCOI_PolicyClient_St : 11|4@0+ (1,0) [0|15] "SED"  GENERIC
 SG_ ResetAvgFe_B_Rq : 21|1@0+ (1,0) [0|1] "SED"  GENERIC
 SG_ ResetTrip2_B_Rq : 0|1@0+ (1,0) [0|1] "SED"  ECM_HEV,PCM,SOBDMC_HPCM,PCM_HEV
 SG_ SndImmrsnLvl_D_Rq : 47|8@0+ (1,0) [0|255] "SED"  GENERIC
 SG_ InfoSysMasterPw_D_Stat : 55|3@0+ (1,0) [0|7] "SED"  GENERIC
 SG_ ResetTrip1_B_Rq : 1|1@0+ (1,0) [0|1] "SED"  ECM_HEV,SOBDMC_HPCM,PCM,PCM_HEV
 SG_ Disp_LangSel2_St : 39|7@0+ (1,0) [0|127] "SED"  GENERIC
 SG_ Disp_LangSel_St : 20|5@0+ (1,0) [0|31] "SED"  GENERIC
 SG_ Diagnostic_Operation_Rq : 31|4@0+ (1,0) [0|15] "SED"  GENERIC
 SG_ Bezel_Diag_Module_Rq : 15|4@0+ (1,0) [0|15] "SED"  GENERIC
 SG_ Audio_Demo_CMND : 3|2@0+ (1,0) [0|3] "SED"  GENERIC
 SG_ Audio_Visualizer : 5|2@0+ (1,0) [0|3] "SED"  GENERIC
 SG_ Surround_Sound_Upmix : 7|2@0+ (1,0) [0|3] "SED"  GENERIC
 SG_ Bezel_Diag_State_Rq : 23|2@0+ (1,0) [0|3] "SED"  GENERIC
 SG_ SurndSndUpmix2_D_Rq : 27|3@0+ (1,0) [0|7] "SED"  GENERIC

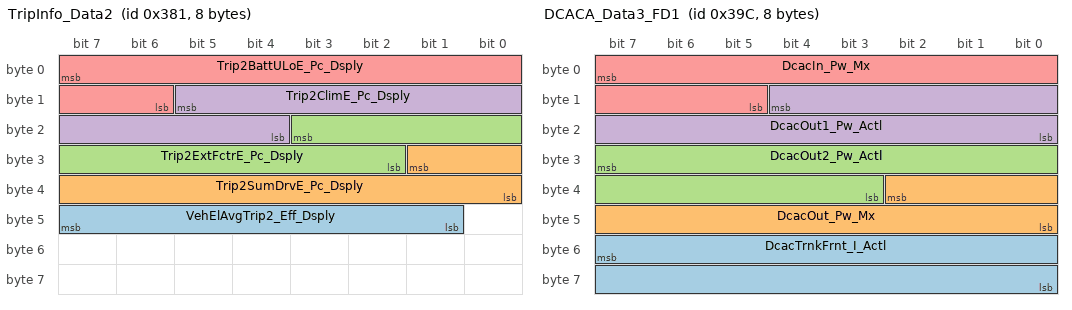
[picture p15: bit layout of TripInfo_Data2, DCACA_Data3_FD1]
BO_ 897 TripInfo_Data2: 8 SOBDMC_HPCM
 SG_ VehElAvgTrip2_Eff_Dsply : 47|7@0+ (10,-100) [-100|1150] "wattHr/km"  GWM
 SG_ Trip2SumDrvE_Pc_Dsply : 25|10@0+ (0.1,0) [0|102.1] "percent"  GWM
 SG_ Trip2ExtFctrE_Pc_Dsply : 19|10@0+ (0.1,0) [0|102.1] "percent"  GWM
 SG_ Trip2ClimE_Pc_Dsply : 13|10@0+ (0.1,0) [0|102.1] "percent"  GWM
 SG_ Trip2BattULoE_Pc_Dsply : 7|10@0+ (0.1,0) [0|102.1] "percent"  GWM

BO_ 1688 AWD_Rapid_Data_Response_1: 8 AWD_DLCM
 SG_ UUDTAWDResponse1 : 7|64@0+ (1,0) [0|1.84467440737096E+019] "unitless"  TSTR

BO_ 878 DCACA_Data4: 8 PCM_HEV
 SG_ LowFuelDsplyType_B_Rq : 56|1@0+ (1,0) [0|1] "SED"  GWM
 SG_ PwBedPnlEnblScnd_B_Rq : 48|1@0+ (1,0) [0|1] "SED"  GWM
 SG_ DcacSysScnd_B_Falt : 40|1@0+ (1,0) [0|1] "SED"  GWM
 SG_ DcacOnScnd_B_Rq : 32|1@0+ (1,0) [0|1] "SED"  GWM
 SG_ DcacGfciTestScnd_B_Rq : 24|1@0+ (1,0) [0|1] "SED"  GWM
 SG_ EngExhMdeHrStrt_D_Stat : 53|5@0+ (1,0) [0|31] "SED"  GWM
 SG_ EngExhMdeHrEnd_D_Stat : 63|5@0+ (1,0) [0|31] "SED"  GWM
 SG_ EngExhMdeHrEnbl_D_Stat : 58|2@0+ (1,0) [0|3] "SED"  GWM
 SG_ DcacGfciTest_B_Rq : 0|1@0+ (1,0) [0|1] "SED"  GWM
 SG_ DcacOut_Pw_DsplyMx : 23|10@0+ (10,0) [0|10220] "watts"  GWM
 SG_ DcacOut1_Pw_Dsply : 39|7@0+ (100,0) [0|12600] "watts"  GWM
 SG_ DcacOut2_Pw_Dsply : 47|7@0+ (100,0) [0|12600] "watts"  GWM
 SG_ DcacHw_D_Confg : 11|4@0+ (1,0) [0|15] "SED"  GWM
 SG_ DcacFaltMsgTxt_D_Rq : 15|4@0+ (1,0) [0|15] "SED"  GWM
 SG_ DcacLoFuelMsgTxt_D_Rq : 29|5@0+ (1,0) [0|31] "SED"  GWM
 SG_ DcacEngOnMsgTxt_D_Rq : 55|2@0+ (1,0) [0|3] "SED"  GWM
 SG_ DcacElPw_D_Stat : 2|2@0+ (1,0) [0|3] "SED"  GWM
 SG_ PwBedPnlEnbl_B_Rq : 3|1@0+ (1,0) [0|1] "SED"  GWM
 SG_ DcacOn_B_Rq : 4|1@0+ (1,0) [0|1] "SED"  SOBDMC_HPCM,GWM
 SG_ DcacSys_B_Falt : 5|1@0+ (1,0) [0|1] "SED"  GWM
 SG_ DcacLedCtl_D_Rq : 7|2@0+ (1,0) [0|3] "SED"  GWM

BO_ 924 DCACA_Data3_FD1: 8 DCACA_HEV
 SG_ DcacTrnkFrnt_I_Actl : 55|16@0+ (0.001,0) [0|65.533] "ampere"  ECM_HEV,PCM
 SG_ DcacOut_Pw_Mx : 34|11@0+ (5,0) [0|10225] "watts"  ECM_HEV,ECM_Diesel,ECM_HEVDSL,PCM,PCM_HEV
 SG_ DcacOut2_Pw_Actl : 31|13@0+ (1,0) [0|8189] "watts"  ECM_HEV,ECM_Diesel,ECM_HEVDSL,PCM,PCM_HEV
 SG_ DcacOut1_Pw_Actl : 12|13@0+ (1,0) [0|8189] "watts"  ECM_HEV,ECM_Diesel,ECM_HEVDSL,PCM,PCM_HEV
 SG_ DcacIn_Pw_Mx : 7|11@0+ (5,0) [0|10225] "watts"  ECM_HEV,ECM_Diesel,ECM_HEVDSL,PCM,PCM_HEV

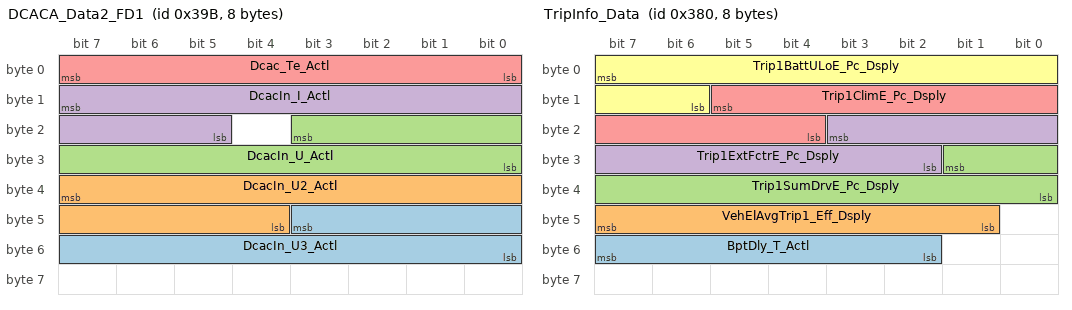
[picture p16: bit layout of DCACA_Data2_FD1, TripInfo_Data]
BO_ 923 DCACA_Data2_FD1: 8 DCACA_HEV
 SG_ DcacIn_U3_Actl : 43|12@0+ (0.5,0) [0|2046.5] "volt"  SOBDMC_HPCM,PCM_HEV,ECM_HEV
 SG_ DcacIn_U2_Actl : 39|12@0+ (0.01,0) [0|40.93] "volt"  PCM,ECM_Diesel,ECM_HEVDSL
 SG_ DcacIn_U_Actl : 19|12@0+ (0.1,0) [0|409.3] "volt"  SOBDMC_HPCM,ECM_HEV,ECM_Diesel,ECM_HEVDSL,PCM,PCM_HEV
 SG_ DcacIn_I_Actl : 15|11@0+ (0.1,0) [0|204.5] "Amps"  SOBDMC_HPCM,ECM_HEV,ECM_Diesel,ECM_HEVDSL,PCM,PCM_HEV
 SG_ Dcac_Te_Actl : 7|8@0+ (1,-60) [-60|193] "degC"  ECM_HEV,ECM_Diesel,ECM_HEVDSL,PCM,PCM_HEV

BO_ 1998 TesterPhysicalResSODR: 64 IPMA_ADAS
 SG_ TesterPhysicalResSODR : 7|64@0+ (1,0) [0|1.84467E+019] "unitless"  TSTR

BO_ 1990 TesterPhysicalReqSODR: 64 TSTR
 SG_ TesterPhysicalReqSODR : 7|64@0+ (1,0) [0|1.84467E+019] "unitless"  IPMA_ADAS

BO_ 1996 TesterPhysicalResSODL: 64 IPMA_ADAS
 SG_ TesterPhysicalResSODL : 7|64@0+ (1,0) [0|1.84467E+019] "unitless"  TSTR

BO_ 1988 TesterPhysicalReqSODL: 64 TSTR
 SG_ TesterPhysicalReqSODL : 7|64@0+ (1,0) [0|1.84467E+019] "unitless"  IPMA_ADAS

BO_ 896 TripInfo_Data: 8 SOBDMC_HPCM
 SG_ BptDly_T_Actl : 55|6@0+ (0.5,0) [0|30.5] "minute"  GWM
 SG_ VehElAvgTrip1_Eff_Dsply : 47|7@0+ (10,-100) [-100|1150] "wattHr/km"  GWM
 SG_ Trip1SumDrvE_Pc_Dsply : 25|10@0+ (0.1,0) [0|102.1] "percent"  GWM
 SG_ Trip1ExtFctrE_Pc_Dsply : 19|10@0+ (0.1,0) [0|102.1] "percent"  GWM
 SG_ Trip1ClimE_Pc_Dsply : 13|10@0+ (0.1,0) [0|102.1] "percent"  GWM
 SG_ Trip1BattULoE_Pc_Dsply : 7|10@0+ (0.1,0) [0|102.1] "percent"  GWM

BO_ 922 DCACA_Data1_FD1: 8 DCACA_HEV
 SG_ PlgOutlet8Prsnt_B_Stat : 17|1@0+ (1,0) [0|1] "SED"  ECM_HEV
 SG_ PlgOutlet7Prsnt_B_Stat : 18|1@0+ (1,0) [0|1] "SED"  ECM_HEV
 SG_ PlgOutlet6Prsnt_B_Stat : 19|1@0+ (1,0) [0|1] "SED"  ECM_HEV
 SG_ TrnkPlgFrontPrsnt_B_St : 20|1@0+ (1,0) [0|1] "SED"  ECM_HEV
 SG_ CabnPlgPrsnt_B_Stat : 21|1@0+ (1,0) [0|1] "SED"  ECM_HEV
 SG_ DcacOverTe_B_Falt : 9|1@0+ (1,0) [0|1] "SED"  ECM_HEV,PCM_HEV,PCM,ECM_HEVDSL,ECM_Diesel
 SG_ DcacRdy_D2_Stat : 23|2@0+ (1,0) [0|3] "SED"  ECM_HEV,PCM_HEV,PCM,ECM_HEVDSL,ECM_Diesel
 SG_ DcacOvrld_B_Falt : 8|1@0+ (1,0) [0|1] "SED"  ECM_HEV,PCM_HEV,PCM,ECM_HEVDSL,ECM_Diesel
 SG_ DcacIpRcBrkrOpn_B_Falt : 10|1@0+ (1,0) [0|1] "SED"  ECM_HEV,PCM_HEV,PCM,ECM_HEVDSL,ECM_Diesel
 SG_ DcacGfci_B_Falt : 11|1@0+ (1,0) [0|1] "SED"  ECM_HEV,PCM_HEV,PCM,ECM_HEVDSL,ECM_Diesel
 SG_ DcacErr_B_Stat : 12|1@0+ (1,0) [0|1] "SED"  ECM_HEV,PCM_HEV,PCM,ECM_HEVDSL,ECM_Diesel
 SG_ DcacBp2BrkrOpn_B_Falt : 13|1@0+ (1,0) [0|1] "SED"  ECM_HEV,PCM_HEV,PCM,ECM_HEVDSL,ECM_Diesel
 SG_ DcacBp1BrkrOpn_B_Falt : 14|1@0+ (1,0) [0|1] "SED"  ECM_HEV,PCM_HEV,PCM,ECM_HEVDSL,ECM_Diesel
 SG_ DcacAcUDetct_B_Falt : 15|1@0+ (1,0) [0|1] "SED"  ECM_HEV,PCM_HEV,PCM,ECM_HEVDSL,ECM_Diesel
 SG_ DcacRdy_D_Stat : 2|3@0+ (1,0) [0|7] "SED"  ECM_HEV,PCM,PCM_HEV
 SG_ DcacPlugPrsnt_B_Stat : 3|1@0+ (1,0) [0|1] "SED"  ECM_HEV,ECM_HEVDSL,ECM_Diesel,PCM,PCM_HEV
 SG_ DcacClntFlw_D_Rq : 5|2@0+ (1,0) [0|3] "SED"  SOBDMC_HPCM,GENERIC
 SG_ CoolFanDcac_D_Rq : 7|2@0+ (1,0) [0|3] "SED"  ECM_HEVDSL,ECM_Diesel,GENERIC

BO_ 1573 IPMA_ADAS_ULS_REC_1: 64 IPMA_ADAS
 SG_ Rec_Buffer_1_ULS_1 : 0|64@1+ (1,0) [0|1.84467440737096E+019] "SED" Vector__XXX
 SG_ Rec_Buffer_2_ULS_1 : 64|64@1+ (1,0) [0|1.84467440737096E+019] "SED" Vector__XXX
 SG_ Rec_Buffer_3_ULS_1 : 128|64@1+ (1,0) [0|1.84467440737096E+019] "SED" Vector__XXX
 SG_ Rec_Buffer_4_ULS_1 : 192|64@1+ (1,0) [0|1.84467440737096E+019] "SED" Vector__XXX
 SG_ Rec_Buffer_5_ULS_1 : 256|64@1+ (1,0) [0|1.84467440737096E+019] "SED" Vector__XXX
 SG_ Rec_Buffer_6_ULS_1 : 320|64@1+ (1,0) [0|1.84467440737096E+019] "SED" Vector__XXX
 SG_ Rec_Buffer_7_ULS_1 : 384|64@1+ (1,0) [0|1.84467440737096E+019] "SED" Vector__XXX
 SG_ Rec_Buffer_8_ULS_1 : 448|64@1+ (1,0) [0|1.84467440737096E+019] "SED" Vector__XXX

BO_ 1574 IPMA_ADAS_ULS_REC_2: 64 IPMA_ADAS
 SG_ Rec_Buffer_1_ULS_2 : 0|64@1+ (1,0) [0|1.84467440737096E+019] "SED" Vector__XXX
 SG_ Rec_Buffer_2_ULS_2 : 64|64@1+ (1,0) [0|1.84467440737096E+019] "SED" Vector__XXX
 SG_ Rec_Buffer_3_ULS_2 : 128|64@1+ (1,0) [0|1.84467440737096E+019] "SED" Vector__XXX
 SG_ Rec_Buffer_4_ULS_2 : 192|64@1+ (1,0) [0|1.84467440737096E+019] "SED" Vector__XXX
 SG_ Rec_Buffer_5_ULS_2 : 256|64@1+ (1,0) [0|1.84467440737096E+019] "SED" Vector__XXX
 SG_ Rec_Buffer_6_ULS_2 : 320|64@1+ (1,0) [0|1.84467440737096E+019] "SED" Vector__XXX
 SG_ Rec_Buffer_7_ULS_2 : 384|64@1+ (1,0) [0|1.84467440737096E+019] "SED" Vector__XXX
 SG_ Rec_Buffer_8_ULS_2 : 448|64@1+ (1,0) [0|1.84467440737096E+019] "SED" Vector__XXX

BO_ 1575 IPMA_ADAS_ULS_REC_3: 64 IPMA_ADAS
 SG_ Rec_Buffer_1_ULS_3 : 0|64@1+ (1,0) [0|1.84467440737096E+019] "SED" Vector__XXX
 SG_ Rec_Buffer_2_ULS_3 : 64|64@1+ (1,0) [0|1.84467440737096E+019] "SED" Vector__XXX
 SG_ Rec_Buffer_3_ULS_3 : 128|64@1+ (1,0) [0|1.84467440737096E+019] "SED" Vector__XXX
 SG_ Rec_Buffer_4_ULS_3 : 192|64@1+ (1,0) [0|1.84467440737096E+019] "SED" Vector__XXX
 SG_ Rec_Buffer_5_ULS_3 : 256|64@1+ (1,0) [0|1.84467440737096E+019] "SED" Vector__XXX
 SG_ Rec_Buffer_6_ULS_3 : 320|64@1+ (1,0) [0|1.84467440737096E+019] "SED" Vector__XXX
 SG_ Rec_Buffer_7_ULS_3 : 384|64@1+ (1,0) [0|1.84467440737096E+019] "SED" Vector__XXX
 SG_ Rec_Buffer_8_ULS_3 : 448|64@1+ (1,0) [0|1.84467440737096E+019] "SED" Vector__XXX

BO_ 1578 IPMA_ADAS_ULS_REPLAY_1: 64 TSTR
 SG_ Replay_Buffer_1_ULS_1 : 0|64@1+ (1,0) [0|1.84467440737096E+019] "SED"  IPMA_ADAS
 SG_ Replay_Buffer_2_ULS_1 : 64|64@1+ (1,0) [0|1.84467440737096E+019] "SED"  IPMA_ADAS
 SG_ Replay_Buffer_3_ULS_1 : 128|64@1+ (1,0) [0|1.84467440737096E+019] "SED"  IPMA_ADAS
 SG_ Replay_Buffer_4_ULS_1 : 192|64@1+ (1,0) [0|1.84467440737096E+019] "SED"  IPMA_ADAS
 SG_ Replay_Buffer_5_ULS_1 : 256|64@1+ (1,0) [0|1.84467440737096E+019] "SED"  IPMA_ADAS
 SG_ Replay_Buffer_6_ULS_1 : 320|64@1+ (1,0) [0|1.84467440737096E+019] "SED"  IPMA_ADAS
 SG_ Replay_Buffer_7_ULS_1 : 384|64@1+ (1,0) [0|1.84467440737096E+019] "SED"  IPMA_ADAS
 SG_ Replay_Buffer_8_ULS_1 : 448|64@1+ (1,0) [0|1.84467440737096E+019] "SED"  IPMA_ADAS

BO_ 1579 IPMA_ADAS_ULS_REPLAY_2: 64 TSTR
 SG_ Replay_Buffer_1_ULS_2 : 0|64@1+ (1,0) [0|1.84467440737096E+019] "SED"  IPMA_ADAS
 SG_ Replay_Buffer_2_ULS_2 : 64|64@1+ (1,0) [0|1.84467440737096E+019] "SED"  IPMA_ADAS
 SG_ Replay_Buffer_3_ULS_2 : 128|64@1+ (1,0) [0|1.84467440737096E+019] "SED"  IPMA_ADAS
 SG_ Replay_Buffer_4_ULS_2 : 192|64@1+ (1,0) [0|1.84467440737096E+019] "SED"  IPMA_ADAS
 SG_ Replay_Buffer_5_ULS_2 : 256|64@1+ (1,0) [0|1.84467440737096E+019] "SED"  IPMA_ADAS
 SG_ Replay_Buffer_6_ULS_2 : 320|64@1+ (1,0) [0|1.84467440737096E+019] "SED"  IPMA_ADAS
 SG_ Replay_Buffer_7_ULS_2 : 384|64@1+ (1,0) [0|1.84467440737096E+019] "SED"  IPMA_ADAS
 SG_ Replay_Buffer_8_ULS_2 : 448|64@1+ (1,0) [0|1.84467440737096E+019] "SED"  IPMA_ADAS

BO_ 1580 IPMA_ADAS_ULS_REPLAY_3: 64 TSTR
 SG_ Replay_Buffer_1_ULS_3 : 0|64@1+ (1,0) [0|1.84467440737096E+019] "SED"  IPMA_ADAS
 SG_ Replay_Buffer_2_ULS_3 : 64|64@1+ (1,0) [0|1.84467440737096E+019] "SED"  IPMA_ADAS
 SG_ Replay_Buffer_3_ULS_3 : 128|64@1+ (1,0) [0|1.84467440737096E+019] "SED"  IPMA_ADAS
 SG_ Replay_Buffer_4_ULS_3 : 192|64@1+ (1,0) [0|1.84467440737096E+019] "SED"  IPMA_ADAS
 SG_ Replay_Buffer_5_ULS_3 : 256|64@1+ (1,0) [0|1.84467440737096E+019] "SED"  IPMA_ADAS
 SG_ Replay_Buffer_6_ULS_3 : 320|64@1+ (1,0) [0|1.84467440737096E+019] "SED"  IPMA_ADAS
 SG_ Replay_Buffer_7_ULS_3 : 384|64@1+ (1,0) [0|1.84467440737096E+019] "SED"  IPMA_ADAS
 SG_ Replay_Buffer_8_ULS_3 : 448|64@1+ (1,0) [0|1.84467440737096E+019] "SED"  IPMA_ADAS

BO_TX_BU_ 1140 : PCM_HEV,SOBDMC_HPCM;
BO_TX_BU_ 2611175440 : ECM,ECM_Diesel,ECM_HEV,ECM_HEVDSL,PCM,SOBDMC_HPCM,PCM_HEV;
BO_TX_BU_ 2610126864 : ECM,ECM_Diesel,ECM_HEV,ECM_HEVDSL,PCM,SOBDMC_HPCM,PCM_HEV;
BO_TX_BU_ 2612224016 : ECM,ECM_Diesel,ECM_HEV,ECM_HEVDSL,PCM,SOBDMC_HPCM,PCM_HEV;
BO_TX_BU_ 878 : PCM,ECM_HEVDSL,ECM_HEV,ECM_Diesel,ECM,PCM_HEV;
CM_ BO_ 66 "Provide control function information to the target function of the Passive Anti-Theft Subsystem";
CM_ SG_ 66 immoControlData_T2 "Not transmitted on all vehicle variants";
CM_ SG_ 66 immoControlCmd_T2 "Not transmitted on all vehicle variants";
CM_ BO_ 651 "TCU CPPM Tx";
CM_ SG_ 1150 LocationServices_1 "Tx by HS3 APIM";
CM_ SG_ 1445 SOBDMC_AutoSarNMReserved4 "Signal not transmitted on gas and diesel variants.";
CM_ SG_ 1445 SOBDMC_AutoSarNMReserved3 "Signal not transmitted on gas and diesel variants.";
CM_ SG_ 1445 SOBDMC_AutoSarNMReserved2 "Signal not transmitted on gas and diesel variants.";
CM_ SG_ 1445 SOBDMC_AutoSarNMReserved1 "Signal not transmitted on gas and diesel variants.";
CM_ SG_ 1445 SOBDMC_AutoSarNMNodeId "Signal not transmitted on gas and diesel variants.";
CM_ SG_ 1445 SOBDMC_AutoSarNMControl "Signal not transmitted on gas and diesel variants.";
CM_ BO_ 402 "FCDIM,APIM Tx";
CM_ BO_ 553 "FCDIM, APIM Tx";
CM_ SG_ 553 SndImmrsnLvl_D_Rq "ImmersionLevel_D_Rq";
CM_ SG_ 553 Disp_LangSel2_St "Reference GSDB for encoding: 009522/B;2-ZZ_LangSel";
CM_ SG_ 553 Disp_LangSel_St "Object.VehicleSettings.Disp_LangSel.St.Language";
CM_ SG_ 553 Diagnostic_Operation_Rq "Object:BezelDiagnostics.MFD_Bezel_Diagnostic.St";
CM_ SG_ 553 Bezel_Diag_Module_Rq "Object:BezelDiagnostics.MFD_Bezel_Diagnostic.St";
CM_ SG_ 553 Audio_Demo_CMND "Object. AudioSettings.Audio Demo_CMND";
CM_ SG_ 553 Audio_Visualizer "Object.AudioSettings.Audio_Visualizer
";
CM_ SG_ 553 Surround_Sound_Upmix "Object.AudioSettings.Surround_Sound_Upmix

";
CM_ SG_ 553 Bezel_Diag_State_Rq "Object:BezelDiagnostics.MFD_Bezel_Diagnostic.Rq";
CM_ SG_ 553 SurndSndUpmix2_D_Rq "Object:Surround_Sound_Upmix2_Rq";
BA_DEF_ BO_  "VFrameFormat" ENUM  "StandardCAN","ExtendedCAN","reserved","reserved","reserved","reserved","reserved","reserved","reserved","reserved","reserved","reserved","reserved","reserved","StandardCAN_FD","ExtendedCAN_FD";
BA_DEF_ SG_  "GenSigSendType" ENUM  "Cyclic","OnWrite","vector_leerstring","OnChange","vector_leerstring","IfActive","vector_leerstring","NoSigSendType";
BA_DEF_ SG_  "GenSigInactiveValue" INT 0 100000;
BA_DEF_ SG_  "WakeupSignal" ENUM  "No","Yes";
BA_DEF_ SG_  "UsedOnPgmDBC" ENUM  "No","Yes";
BA_DEF_ SG_  "GenSigStartValueInteger" INT 0 1000000000;
BA_DEF_ SG_  "ContentDependant" ENUM  "No","Yes";
BA_DEF_ SG_  "MetaData" ENUM  "No","Yes";
BA_DEF_ SG_  "GenSigStartValue" HEX 0 268435455;
BA_DEF_ SG_  "U_CX727_MY2021_Rx" ENUM  "No","Yes";
BA_DEF_ SG_  "U_P702_MY2021_Rx" ENUM  "No","Yes";
BA_DEF_ SG_  "U_T6_MCA_MY2020_Rx" ENUM  "No","Yes";
BA_DEF_ SG_  "ECGUsedRxSignal" ENUM  "No","Yes";
BA_DEF_ SG_  "U_CD542_MY2021_Rx" ENUM  "No","Yes";
BA_DEF_ SG_  "U_U55X_MY2022_Rx" ENUM  "No","Yes";
BA_DEF_ SG_  "U_CD764_MY2022_Rx" ENUM  "No","Yes";
BA_DEF_ SG_  "U_CDX706_MY2023_Rx" ENUM  "No","Yes";
BA_DEF_ SG_  "U_CX727_MY2021_Tx" ENUM  "No","Yes";
BA_DEF_ SG_  "U_P702_MY2021_Tx" ENUM  "No","Yes";
BA_DEF_ SG_  "U_T6_MCA_MY2020_Tx" ENUM  "No","Yes";
BA_DEF_ SG_  "ECGUsedTxSignal" ENUM  "No","Yes";
BA_DEF_ SG_  "U_CD542_MY2021_Tx" ENUM  "No","Yes";
BA_DEF_ SG_  "U_U55X_MY2022_Tx" ENUM  "No","Yes";
BA_DEF_ SG_  "U_CD764_MY2022_Tx" ENUM  "No","Yes";
BA_DEF_ SG_  "U_CDX706_MY2023_Tx" ENUM  "No","Yes";
BA_DEF_ BO_  "GenMsgILSupport" ENUM  "No","Yes";
BA_DEF_ BO_  "DiagResponse" ENUM  "No","Yes";
BA_DEF_ BO_  "DiagRequest" ENUM  "No","Yes";
BA_DEF_ BO_  "TpTxIndex" INT 0 536870911;
BA_DEF_ BO_  "DiagState" ENUM  "No","Yes";
BA_DEF_ BO_  "TpApplType" STRING ;
BA_DEF_ BO_  "NmAsrMessage" ENUM  "No","Yes";
BA_DEF_ BO_  "ProgBWConditional" STRING ;
BA_DEF_ BO_  "SCP_AuthInfoTxLength" INT 0 512;
BA_DEF_ BO_  "SCP_FreshnessValueTxLength" INT 0 512;
BA_DEF_ BO_  "SCP_FreshnessValueLength" INT 0 512;
BA_DEF_ BO_  "OvtpPushApplication" ENUM  "FALSE","TRUE";
BA_DEF_ BO_  "GenMsgSendType" ENUM  "FixedPeriodic","Event","EnabledPeriodic","NotUsed","NotUsed","EventPeriodic","NotUsed","NotUsed","NoMsgSendType";
BA_DEF_ BO_  "GenMsgCycleTime" INT 0 100000;
BA_DEF_ BO_  "GenMsgDelayTime" INT 0 1000;
BA_DEF_ BO_  "GenMsgNrOfRepetition" INT 0 100;
BA_DEF_ BO_  "GenMsgStartDelayTime" INT 0 10000;
BA_DEF_ BO_  "EventRateOfChange" INT 10 10000;
BA_DEF_ BO_  "FrameGatewayId" HEX 0 1407;
BA_DEF_ BO_  "NetworkInitialization" ENUM  "No","Yes";
BA_DEF_ BO_  "FrameGatewayNetwork" STRING ;
BA_DEF_ BO_  "FrameRouting" STRING ;
BA_DEF_DEF_  "VFrameFormat" "ExtendedCAN_FD";
BA_DEF_DEF_  "GenSigSendType" "NoSigSendType";
BA_DEF_DEF_  "GenSigInactiveValue" 0;
BA_DEF_DEF_  "WakeupSignal" "No";
BA_DEF_DEF_  "UsedOnPgmDBC" "Yes";
BA_DEF_DEF_  "GenSigStartValueInteger" 0;
BA_DEF_DEF_  "ContentDependant" "No";
BA_DEF_DEF_  "MetaData" "No";
BA_DEF_DEF_  "GenSigStartValue" 0;
BA_DEF_DEF_  "U_CX727_MY2021_Rx" "No";
BA_DEF_DEF_  "U_P702_MY2021_Rx" "No";
BA_DEF_DEF_  "U_T6_MCA_MY2020_Rx" "No";
BA_DEF_DEF_  "ECGUsedRxSignal" "No";
BA_DEF_DEF_  "U_CD542_MY2021_Rx" "No";
BA_DEF_DEF_  "U_U55X_MY2022_Rx" "No";
BA_DEF_DEF_  "U_CD764_MY2022_Rx" "No";
BA_DEF_DEF_  "U_CDX706_MY2023_Rx" "No";
BA_DEF_DEF_  "U_CX727_MY2021_Tx" "No";
BA_DEF_DEF_  "U_P702_MY2021_Tx" "No";
BA_DEF_DEF_  "U_T6_MCA_MY2020_Tx" "No";
BA_DEF_DEF_  "ECGUsedTxSignal" "No";
BA_DEF_DEF_  "U_CD542_MY2021_Tx" "No";
BA_DEF_DEF_  "U_U55X_MY2022_Tx" "No";
BA_DEF_DEF_  "U_CD764_MY2022_Tx" "No";
BA_DEF_DEF_  "U_CDX706_MY2023_Tx" "No";
BA_DEF_DEF_  "GenMsgILSupport" "Yes";
BA_DEF_DEF_  "DiagResponse" "No";
BA_DEF_DEF_  "DiagRequest" "No";
BA_DEF_DEF_  "TpTxIndex" 0;
BA_DEF_DEF_  "DiagState" "No";
BA_DEF_DEF_  "TpApplType" "";
BA_DEF_DEF_  "NmAsrMessage" "No";
BA_DEF_DEF_  "ProgBWConditional" "NONE";
BA_DEF_DEF_  "SCP_AuthInfoTxLength" 53;
BA_DEF_DEF_  "SCP_FreshnessValueTxLength" 11;
BA_DEF_DEF_  "SCP_FreshnessValueLength" 64;
BA_DEF_DEF_  "OvtpPushApplication" "FALSE";
BA_DEF_DEF_  "GenMsgSendType" "NoMsgSendType";
BA_DEF_DEF_  "GenMsgCycleTime" 0;
BA_DEF_DEF_  "GenMsgDelayTime" 20;
BA_DEF_DEF_  "GenMsgNrOfRepetition" 1;
BA_DEF_DEF_  "GenMsgStartDelayTime" 0;
BA_DEF_DEF_  "EventRateOfChange" 10000;
BA_DEF_DEF_  "FrameGatewayId" 0;
BA_DEF_DEF_  "NetworkInitialization" "Yes";
BA_DEF_DEF_  "FrameGatewayNetwork" "NONE";
BA_DEF_DEF_  "FrameRouting" "";
BA_ "GenMsgSendType" BO_ 1119 5;
BA_ "GenMsgCycleTime" BO_ 1119 1000;
BA_ "GenMsgSendType" BO_ 651 5;
BA_ "GenMsgCycleTime" BO_ 651 1000;
BA_ "GenMsgSendType" BO_ 1097 0;
BA_ "GenMsgCycleTime" BO_ 1097 1000;
BA_ "GenMsgSendType" BO_ 607 5;
BA_ "GenMsgCycleTime" BO_ 607 1000;
BA_ "GenMsgSendType" BO_ 1150 1;
BA_ "GenMsgSendType" BO_ 529 5;
BA_ "GenMsgCycleTime" BO_ 529 1000;
BA_ "GenMsgSendType" BO_ 1049 5;
BA_ "GenMsgCycleTime" BO_ 1049 1000;
BA_ "GenMsgSendType" BO_ 867 0;
BA_ "GenMsgCycleTime" BO_ 867 1000;
BA_ "GenMsgSendType" BO_ 866 0;
BA_ "GenMsgCycleTime" BO_ 866 100;
BA_ "GenMsgSendType" BO_ 865 0;
BA_ "GenMsgCycleTime" BO_ 865 40;
BA_ "GenMsgSendType" BO_ 402 5;
BA_ "GenMsgCycleTime" BO_ 402 1000;
BA_ "GenMsgSendType" BO_ 553 5;
BA_ "GenMsgCycleTime" BO_ 553 1000;
BA_ "GenMsgSendType" BO_ 924 0;
BA_ "GenMsgCycleTime" BO_ 924 1000;
BA_ "GenMsgSendType" BO_ 923 0;
BA_ "GenMsgCycleTime" BO_ 923 100;
BA_ "GenMsgSendType" BO_ 922 5;
BA_ "GenMsgCycleTime" BO_ 922 1000;
BA_ "TpTxIndex" BO_ 2610126865 462439640;
BA_ "GenMsgSendType" BO_ 2610126865 1;
BA_ "GenMsgDelayTime" BO_ 2610126865 0;
BA_ "NetworkInitialization" BO_ 2610126865 0;
BA_ "TpTxIndex" BO_ 2610971864 463488216;
BA_ "GenMsgSendType" BO_ 2610971864 1;
BA_ "GenMsgDelayTime" BO_ 2610971864 0;
BA_ "NetworkInitialization" BO_ 2610971864 0;
BA_ "TpTxIndex" BO_ 2611175441 463488216;
BA_ "GenMsgSendType" BO_ 2611175441 1;
BA_ "GenMsgDelayTime" BO_ 2611175441 0;
BA_ "NetworkInitialization" BO_ 2611175441 0;
BA_ "TpTxIndex" BO_ 2610126946 462522584;
BA_ "GenMsgSendType" BO_ 2610126946 1;
BA_ "GenMsgDelayTime" BO_ 2610126946 0;
BA_ "NetworkInitialization" BO_ 2610126946 0;
BA_ "TpTxIndex" BO_ 2610006232 462522584;
BA_ "GenMsgSendType" BO_ 2610006232 1;
BA_ "GenMsgDelayTime" BO_ 2610006232 0;
BA_ "NetworkInitialization" BO_ 2610006232 0;
BA_ "GenMsgILSupport" BO_ 1993 0;
BA_ "DiagResponse" BO_ 1993 1;
BA_ "GenMsgSendType" BO_ 1993 1;
BA_ "GenMsgDelayTime" BO_ 1993 0;
BA_ "NetworkInitialization" BO_ 1993 0;
BA_ "VFrameFormat" BO_ 1993 14;
BA_ "GenMsgILSupport" BO_ 1985 0;
BA_ "DiagRequest" BO_ 1985 1;
BA_ "GenMsgSendType" BO_ 1985 1;
BA_ "GenMsgDelayTime" BO_ 1985 0;
BA_ "NetworkInitialization" BO_ 1985 0;
BA_ "VFrameFormat" BO_ 1985 14;
BA_ "GenMsgILSupport" BO_ 1503 0;
BA_ "NmAsrMessage" BO_ 1503 1;
BA_ "GenMsgSendType" BO_ 1503 0;
BA_ "GenMsgCycleTime" BO_ 1503 1000;
BA_ "NetworkInitialization" BO_ 1503 0;
BA_ "VFrameFormat" BO_ 1503 14;
BA_ "FrameGatewayId" BO_ 1119 1119;
BA_ "FrameGatewayNetwork" BO_ 1119 "HS1_CAN";
BA_ "FrameRouting" BO_ 1119 "HS1_CAN,0x45F;";
BA_ "VFrameFormat" BO_ 1119 14;
BA_ "GenMsgILSupport" BO_ 2022 0;
BA_ "DiagRequest" BO_ 2022 1;
BA_ "GenMsgSendType" BO_ 2022 1;
BA_ "GenMsgDelayTime" BO_ 2022 0;
BA_ "NetworkInitialization" BO_ 2022 0;
BA_ "VFrameFormat" BO_ 2022 14;
BA_ "FrameGatewayId" BO_ 912 912;
BA_ "FrameGatewayNetwork" BO_ 912 "HS1_CAN";
BA_ "FrameRouting" BO_ 912 "HS1_CAN,0x390;";
BA_ "VFrameFormat" BO_ 912 14;
BA_ "FrameGatewayId" BO_ 66 66;
BA_ "FrameGatewayNetwork" BO_ 66 "HS1_CAN";
BA_ "FrameRouting" BO_ 66 "HS1_CAN,0x42;";
BA_ "VFrameFormat" BO_ 66 14;
BA_ "FrameGatewayId" BO_ 651 651;
BA_ "FrameGatewayNetwork" BO_ 651 "HS4_CAN";
BA_ "FrameRouting" BO_ 651 "HS4_CAN,0x28B;";
BA_ "VFrameFormat" BO_ 651 14;
BA_ "FrameGatewayId" BO_ 1097 1097;
BA_ "FrameGatewayNetwork" BO_ 1097 "HS1_CAN";
BA_ "FrameRouting" BO_ 1097 "HS1_CAN,0x449;";
BA_ "VFrameFormat" BO_ 1097 14;
BA_ "FrameGatewayId" BO_ 607 607;
BA_ "FrameGatewayNetwork" BO_ 607 "HS1_CAN";
BA_ "FrameRouting" BO_ 607 "HS1_CAN,0x25F;";
BA_ "VFrameFormat" BO_ 607 14;
BA_ "TpTxIndex" BO_ 2609955032 462471384;
BA_ "GenMsgSendType" BO_ 2609955032 1;
BA_ "GenMsgDelayTime" BO_ 2609955032 0;
BA_ "NetworkInitialization" BO_ 2609955032 0;
BA_ "TpTxIndex" BO_ 2610126896 462471384;
BA_ "GenMsgSendType" BO_ 2610126896 1;
BA_ "GenMsgDelayTime" BO_ 2610126896 0;
BA_ "NetworkInitialization" BO_ 2610126896 0;
BA_ "TpTxIndex" BO_ 2611003608 463519960;
BA_ "GenMsgSendType" BO_ 2611003608 1;
BA_ "GenMsgDelayTime" BO_ 2611003608 0;
BA_ "NetworkInitialization" BO_ 2611003608 0;
BA_ "TpTxIndex" BO_ 2612224048 464568536;
BA_ "OvtpPushApplication" BO_ 2612224048 1;
BA_ "GenMsgSendType" BO_ 2612224048 1;
BA_ "GenMsgDelayTime" BO_ 2612224048 0;
BA_ "NetworkInitialization" BO_ 2612224048 0;
BA_ "TpTxIndex" BO_ 2611175472 463519960;
BA_ "GenMsgSendType" BO_ 2611175472 1;
BA_ "GenMsgDelayTime" BO_ 2611175472 0;
BA_ "NetworkInitialization" BO_ 2611175472 0;
BA_ "FrameGatewayId" BO_ 1150 1118;
BA_ "FrameGatewayNetwork" BO_ 1150 "HS3_CAN";
BA_ "FrameRouting" BO_ 1150 "HS3_CAN,0x45E;";
BA_ "VFrameFormat" BO_ 1150 14;
BA_ "TpTxIndex" BO_ 2612224033 464553176;
BA_ "OvtpPushApplication" BO_ 2612224033 1;
BA_ "GenMsgSendType" BO_ 2612224033 1;
BA_ "GenMsgDelayTime" BO_ 2612224033 0;
BA_ "NetworkInitialization" BO_ 2612224033 0;
BA_ "TpTxIndex" BO_ 2609939672 462456024;
BA_ "GenMsgSendType" BO_ 2609939672 1;
BA_ "GenMsgDelayTime" BO_ 2609939672 0;
BA_ "NetworkInitialization" BO_ 2609939672 0;
BA_ "TpTxIndex" BO_ 2610126881 462456024;
BA_ "GenMsgSendType" BO_ 2610126881 1;
BA_ "GenMsgDelayTime" BO_ 2610126881 0;
BA_ "NetworkInitialization" BO_ 2610126881 0;
BA_ "TpTxIndex" BO_ 2612043992 464560344;
BA_ "OvtpPushApplication" BO_ 2612043992 1;
BA_ "GenMsgSendType" BO_ 2612043992 1;
BA_ "GenMsgDelayTime" BO_ 2612043992 0;
BA_ "NetworkInitialization" BO_ 2612043992 0;
BA_ "TpTxIndex" BO_ 2610995416 463511768;
BA_ "GenMsgSendType" BO_ 2610995416 1;
BA_ "GenMsgDelayTime" BO_ 2610995416 0;
BA_ "NetworkInitialization" BO_ 2610995416 0;
BA_ "TpTxIndex" BO_ 2612224040 464560344;
BA_ "OvtpPushApplication" BO_ 2612224040 1;
BA_ "GenMsgSendType" BO_ 2612224040 1;
BA_ "GenMsgDelayTime" BO_ 2612224040 0;
BA_ "NetworkInitialization" BO_ 2612224040 0;
BA_ "TpTxIndex" BO_ 2611175464 463511768;
BA_ "GenMsgSendType" BO_ 2611175464 1;
BA_ "GenMsgDelayTime" BO_ 2611175464 0;
BA_ "NetworkInitialization" BO_ 2611175464 0;
BA_ "GenMsgSendType" BO_ 1082 5;
BA_ "GenMsgCycleTime" BO_ 1082 1000;
BA_ "VFrameFormat" BO_ 1082 14;
BA_ "FrameGatewayId" BO_ 529 529;
BA_ "FrameGatewayNetwork" BO_ 529 "HS3_CAN";
BA_ "FrameRouting" BO_ 529 "HS3_CAN,0x211;";
BA_ "VFrameFormat" BO_ 529 14;
BA_ "GenMsgILSupport" BO_ 1679 0;
BA_ "TpApplType" BO_ 1679 "DiagUUDTResponse";
BA_ "GenMsgSendType" BO_ 1679 1;
BA_ "NetworkInitialization" BO_ 1679 0;
BA_ "VFrameFormat" BO_ 1679 14;
BA_ "GenMsgILSupport" BO_ 1678 0;
BA_ "TpApplType" BO_ 1678 "DiagUUDTResponse";
BA_ "GenMsgSendType" BO_ 1678 1;
BA_ "NetworkInitialization" BO_ 1678 0;
BA_ "VFrameFormat" BO_ 1678 14;
BA_ "GenMsgILSupport" BO_ 1677 0;
BA_ "TpApplType" BO_ 1677 "DiagUUDTResponse";
BA_ "GenMsgSendType" BO_ 1677 1;
BA_ "NetworkInitialization" BO_ 1677 0;
BA_ "VFrameFormat" BO_ 1677 14;
BA_ "GenMsgILSupport" BO_ 1676 0;
BA_ "TpApplType" BO_ 1676 "DiagUUDTResponse";
BA_ "GenMsgSendType" BO_ 1676 1;
BA_ "NetworkInitialization" BO_ 1676 0;
BA_ "VFrameFormat" BO_ 1676 14;
BA_ "GenMsgILSupport" BO_ 1445 0;
BA_ "NmAsrMessage" BO_ 1445 1;
BA_ "GenMsgSendType" BO_ 1445 0;
BA_ "GenMsgCycleTime" BO_ 1445 1000;
BA_ "NetworkInitialization" BO_ 1445 0;
BA_ "VFrameFormat" BO_ 1445 14;
BA_ "GenMsgSendType" BO_ 1143 0;
BA_ "GenMsgCycleTime" BO_ 1143 500;
BA_ "VFrameFormat" BO_ 1143 14;
BA_ "GenMsgSendType" BO_ 1142 0;
BA_ "GenMsgCycleTime" BO_ 1142 500;
BA_ "VFrameFormat" BO_ 1142 14;
BA_ "GenMsgSendType" BO_ 1141 0;
BA_ "GenMsgCycleTime" BO_ 1141 100;
BA_ "VFrameFormat" BO_ 1141 14;
BA_ "GenMsgSendType" BO_ 1140 0;
BA_ "GenMsgCycleTime" BO_ 1140 1000;
BA_ "VFrameFormat" BO_ 1140 14;
BA_ "GenMsgSendType" BO_ 1139 0;
BA_ "GenMsgCycleTime" BO_ 1139 1500;
BA_ "VFrameFormat" BO_ 1139 14;
BA_ "GenMsgSendType" BO_ 1138 0;
BA_ "GenMsgCycleTime" BO_ 1138 1500;
BA_ "VFrameFormat" BO_ 1138 14;
BA_ "GenMsgSendType" BO_ 1016 5;
BA_ "GenMsgCycleTime" BO_ 1016 1000;
BA_ "VFrameFormat" BO_ 1016 14;
BA_ "GenMsgSendType" BO_ 1013 5;
BA_ "GenMsgCycleTime" BO_ 1013 1000;
BA_ "VFrameFormat" BO_ 1013 14;
BA_ "GenMsgSendType" BO_ 1012 5;
BA_ "GenMsgCycleTime" BO_ 1012 1000;
BA_ "VFrameFormat" BO_ 1012 14;
BA_ "GenMsgSendType" BO_ 1011 5;
BA_ "GenMsgCycleTime" BO_ 1011 1000;
BA_ "VFrameFormat" BO_ 1011 14;
BA_ "FrameGatewayId" BO_ 1049 1049;
BA_ "FrameGatewayNetwork" BO_ 1049 "HS3_CAN";
BA_ "FrameRouting" BO_ 1049 "HS3_CAN,0x419;";
BA_ "VFrameFormat" BO_ 1049 14;
BA_ "GenMsgSendType" BO_ 72 0;
BA_ "GenMsgCycleTime" BO_ 72 20;
BA_ "GenMsgDelayTime" BO_ 72 10;
BA_ "VFrameFormat" BO_ 72 14;
BA_ "TpTxIndex" BO_ 2611175457 463504600;
BA_ "GenMsgSendType" BO_ 2611175457 1;
BA_ "GenMsgDelayTime" BO_ 2611175457 0;
BA_ "NetworkInitialization" BO_ 2611175457 0;
BA_ "TpTxIndex" BO_ 2609946840 462463192;
BA_ "GenMsgSendType" BO_ 2609946840 1;
BA_ "GenMsgDelayTime" BO_ 2609946840 0;
BA_ "NetworkInitialization" BO_ 2609946840 0;
BA_ "TpTxIndex" BO_ 2610126888 462463192;
BA_ "GenMsgSendType" BO_ 2610126888 1;
BA_ "GenMsgDelayTime" BO_ 2610126888 0;
BA_ "NetworkInitialization" BO_ 2610126888 0;
BA_ "TpTxIndex" BO_ 2611175440 463487192;
BA_ "GenMsgSendType" BO_ 2611175440 1;
BA_ "GenMsgDelayTime" BO_ 2611175440 0;
BA_ "NetworkInitialization" BO_ 2611175440 0;
BA_ "TpTxIndex" BO_ 2609922264 462438616;
BA_ "GenMsgSendType" BO_ 2609922264 1;
BA_ "GenMsgDelayTime" BO_ 2609922264 0;
BA_ "NetworkInitialization" BO_ 2609922264 0;
BA_ "TpTxIndex" BO_ 2610953432 463469784;
BA_ "GenMsgSendType" BO_ 2610953432 1;
BA_ "GenMsgDelayTime" BO_ 2610953432 0;
BA_ "NetworkInitialization" BO_ 2610953432 0;
BA_ "TpTxIndex" BO_ 2610126864 462438616;
BA_ "GenMsgSendType" BO_ 2610126864 1;
BA_ "GenMsgDelayTime" BO_ 2610126864 0;
BA_ "NetworkInitialization" BO_ 2610126864 0;
BA_ "TpTxIndex" BO_ 2612002008 464518360;
BA_ "GenMsgSendType" BO_ 2612002008 1;
BA_ "GenMsgDelayTime" BO_ 2612002008 0;
BA_ "NetworkInitialization" BO_ 2612002008 0;
BA_ "TpTxIndex" BO_ 2610970840 463487192;
BA_ "GenMsgSendType" BO_ 2610970840 1;
BA_ "GenMsgDelayTime" BO_ 2610970840 0;
BA_ "NetworkInitialization" BO_ 2610970840 0;
BA_ "TpTxIndex" BO_ 2612224016 464535768;
BA_ "OvtpPushApplication" BO_ 2612224016 1;
BA_ "GenMsgSendType" BO_ 2612224016 1;
BA_ "GenMsgDelayTime" BO_ 2612224016 0;
BA_ "NetworkInitialization" BO_ 2612224016 0;
BA_ "GenMsgSendType" BO_ 775 5;
BA_ "GenMsgCycleTime" BO_ 775 1000;
BA_ "VFrameFormat" BO_ 775 14;
BA_ "GenMsgSendType" BO_ 774 5;
BA_ "GenMsgCycleTime" BO_ 774 1000;
BA_ "VFrameFormat" BO_ 774 14;
BA_ "GenMsgSendType" BO_ 943 0;
BA_ "GenMsgCycleTime" BO_ 943 20;
BA_ "GenMsgDelayTime" BO_ 943 10;
BA_ "VFrameFormat" BO_ 943 14;
BA_ "GenMsgILSupport" BO_ 1816 0;
BA_ "DiagResponse" BO_ 1816 1;
BA_ "GenMsgSendType" BO_ 1816 1;
BA_ "GenMsgDelayTime" BO_ 1816 0;
BA_ "NetworkInitialization" BO_ 1816 0;
BA_ "VFrameFormat" BO_ 1816 14;
BA_ "GenMsgILSupport" BO_ 1808 0;
BA_ "DiagRequest" BO_ 1808 1;
BA_ "GenMsgSendType" BO_ 1808 1;
BA_ "GenMsgDelayTime" BO_ 1808 0;
BA_ "NetworkInitialization" BO_ 1808 0;
BA_ "VFrameFormat" BO_ 1808 14;
BA_ "GenMsgSendType" BO_ 930 5;
BA_ "GenMsgCycleTime" BO_ 930 1000;
BA_ "VFrameFormat" BO_ 930 14;
BA_ "GenMsgSendType" BO_ 929 5;
BA_ "GenMsgCycleTime" BO_ 929 1000;
BA_ "VFrameFormat" BO_ 929 14;
BA_ "GenMsgILSupport" BO_ 1783 0;
BA_ "DiagRequest" BO_ 1783 1;
BA_ "GenMsgSendType" BO_ 1783 1;
BA_ "GenMsgDelayTime" BO_ 1783 0;
BA_ "VFrameFormat" BO_ 1783 14;
BA_ "FrameGatewayId" BO_ 867 867;
BA_ "FrameGatewayNetwork" BO_ 867 "HS1_CAN";
BA_ "FrameRouting" BO_ 867 "HS1_CAN,0x363;";
BA_ "VFrameFormat" BO_ 867 14;
BA_ "FrameGatewayId" BO_ 866 866;
BA_ "FrameGatewayNetwork" BO_ 866 "HS1_CAN";
BA_ "FrameRouting" BO_ 866 "HS1_CAN,0x362;";
BA_ "VFrameFormat" BO_ 866 14;
BA_ "FrameGatewayId" BO_ 865 865;
BA_ "FrameGatewayNetwork" BO_ 865 "HS1_CAN";
BA_ "FrameRouting" BO_ 865 "HS1_CAN,0x361;";
BA_ "VFrameFormat" BO_ 865 14;
BA_ "TpTxIndex" BO_ 2612194520 464710872;
BA_ "OvtpPushApplication" BO_ 2612194520 1;
BA_ "GenMsgSendType" BO_ 2612194520 1;
BA_ "GenMsgDelayTime" BO_ 2612194520 0;
BA_ "NetworkInitialization" BO_ 2612194520 0;
BA_ "TpTxIndex" BO_ 2610127035 462613720;
BA_ "GenMsgSendType" BO_ 2610127035 1;
BA_ "GenMsgDelayTime" BO_ 2610127035 0;
BA_ "NetworkInitialization" BO_ 2610127035 0;
BA_ "TpTxIndex" BO_ 2610097368 462613720;
BA_ "GenMsgSendType" BO_ 2610097368 1;
BA_ "GenMsgDelayTime" BO_ 2610097368 0;
BA_ "NetworkInitialization" BO_ 2610097368 0;
BA_ "FrameGatewayId" BO_ 402 402;
BA_ "FrameGatewayNetwork" BO_ 402 "HS3_CAN";
BA_ "FrameRouting" BO_ 402 "HS3_CAN,0x192;";
BA_ "VFrameFormat" BO_ 402 14;
BA_ "TpTxIndex" BO_ 2611145944 463662296;
BA_ "GenMsgSendType" BO_ 2611145944 1;
BA_ "GenMsgDelayTime" BO_ 2611145944 0;
BA_ "NetworkInitialization" BO_ 2611145944 0;
BA_ "TpTxIndex" BO_ 2611175611 463662296;
BA_ "GenMsgSendType" BO_ 2611175611 1;
BA_ "GenMsgDelayTime" BO_ 2611175611 0;
BA_ "NetworkInitialization" BO_ 2611175611 0;
BA_ "GenMsgILSupport" BO_ 1456 0;
BA_ "NmAsrMessage" BO_ 1456 1;
BA_ "GenMsgSendType" BO_ 1456 0;
BA_ "GenMsgCycleTime" BO_ 1456 1000;
BA_ "NetworkInitialization" BO_ 1456 0;
BA_ "VFrameFormat" BO_ 1456 14;
BA_ "GenMsgILSupport" BO_ 1782 0;
BA_ "DiagRequest" BO_ 1782 1;
BA_ "GenMsgSendType" BO_ 1782 1;
BA_ "GenMsgDelayTime" BO_ 1782 0;
BA_ "VFrameFormat" BO_ 1782 14;
BA_ "GenMsgILSupport" BO_ 1791 0;
BA_ "DiagResponse" BO_ 1791 1;
BA_ "GenMsgSendType" BO_ 1791 1;
BA_ "GenMsgDelayTime" BO_ 1791 0;
BA_ "VFrameFormat" BO_ 1791 14;
BA_ "GenMsgILSupport" BO_ 1790 0;
BA_ "DiagResponse" BO_ 1790 1;
BA_ "GenMsgSendType" BO_ 1790 1;
BA_ "GenMsgDelayTime" BO_ 1790 0;
BA_ "VFrameFormat" BO_ 1790 14;
BA_ "GenMsgSendType" BO_ 513 5;
BA_ "GenMsgCycleTime" BO_ 513 1000;
BA_ "VFrameFormat" BO_ 513 14;
BA_ "FrameGatewayId" BO_ 553 553;
BA_ "FrameGatewayNetwork" BO_ 553 "HS3_CAN";
BA_ "FrameRouting" BO_ 553 "HS3_CAN,0x229;";
BA_ "VFrameFormat" BO_ 553 14;
BA_ "GenMsgSendType" BO_ 897 0;
BA_ "GenMsgCycleTime" BO_ 897 1000;
BA_ "VFrameFormat" BO_ 897 14;
BA_ "GenMsgILSupport" BO_ 1688 0;
BA_ "TpApplType" BO_ 1688 "DiagUUDTResponse";
BA_ "GenMsgSendType" BO_ 1688 1;
BA_ "NetworkInitialization" BO_ 1688 0;
BA_ "VFrameFormat" BO_ 1688 14;
BA_ "GenMsgSendType" BO_ 878 5;
BA_ "GenMsgCycleTime" BO_ 878 1000;
BA_ "VFrameFormat" BO_ 878 14;
BA_ "FrameGatewayId" BO_ 924 924;
BA_ "FrameGatewayNetwork" BO_ 924 "HS1_CAN";
BA_ "FrameRouting" BO_ 924 "HS1_CAN,0x39C;";
BA_ "VFrameFormat" BO_ 924 14;
BA_ "FrameGatewayId" BO_ 923 923;
BA_ "FrameGatewayNetwork" BO_ 923 "HS1_CAN";
BA_ "FrameRouting" BO_ 923 "HS1_CAN,0x39B;";
BA_ "VFrameFormat" BO_ 923 14;
BA_ "GenMsgILSupport" BO_ 1998 0;
BA_ "DiagResponse" BO_ 1998 1;
BA_ "GenMsgSendType" BO_ 1998 1;
BA_ "GenMsgDelayTime" BO_ 1998 0;
BA_ "NetworkInitialization" BO_ 1998 0;
BA_ "VFrameFormat" BO_ 1998 14;
BA_ "GenMsgILSupport" BO_ 1990 0;
BA_ "DiagRequest" BO_ 1990 1;
BA_ "GenMsgSendType" BO_ 1990 1;
BA_ "GenMsgDelayTime" BO_ 1990 0;
BA_ "NetworkInitialization" BO_ 1990 0;
BA_ "VFrameFormat" BO_ 1990 14;
BA_ "GenMsgILSupport" BO_ 1996 0;
BA_ "DiagResponse" BO_ 1996 1;
BA_ "GenMsgSendType" BO_ 1996 1;
BA_ "GenMsgDelayTime" BO_ 1996 0;
BA_ "NetworkInitialization" BO_ 1996 0;
BA_ "VFrameFormat" BO_ 1996 14;
BA_ "GenMsgILSupport" BO_ 1988 0;
BA_ "DiagRequest" BO_ 1988 1;
BA_ "GenMsgSendType" BO_ 1988 1;
BA_ "GenMsgDelayTime" BO_ 1988 0;
BA_ "NetworkInitialization" BO_ 1988 0;
BA_ "VFrameFormat" BO_ 1988 14;
BA_ "GenMsgSendType" BO_ 896 0;
BA_ "GenMsgCycleTime" BO_ 896 1000;
BA_ "VFrameFormat" BO_ 896 14;
BA_ "FrameGatewayId" BO_ 922 922;
BA_ "FrameGatewayNetwork" BO_ 922 "HS1_CAN";
BA_ "FrameRouting" BO_ 922 "HS1_CAN,0x39A;";
BA_ "VFrameFormat" BO_ 922 14;
BA_ "GenMsgCycleTime" BO_ 1573 20;
BA_ "GenMsgSendType" BO_ 1573 0;
BA_ "VFrameFormat" BO_ 1573 14;
BA_ "GenMsgCycleTime" BO_ 1574 20;
BA_ "GenMsgSendType" BO_ 1574 0;
BA_ "VFrameFormat" BO_ 1574 14;
BA_ "GenMsgCycleTime" BO_ 1575 20;
BA_ "GenMsgSendType" BO_ 1575 0;
BA_ "VFrameFormat" BO_ 1575 14;
BA_ "GenMsgCycleTime" BO_ 1578 20;
BA_ "GenMsgSendType" BO_ 1578 5;
BA_ "VFrameFormat" BO_ 1578 14;
BA_ "GenMsgCycleTime" BO_ 1579 20;
BA_ "GenMsgSendType" BO_ 1579 5;
BA_ "VFrameFormat" BO_ 1579 14;
BA_ "GenMsgCycleTime" BO_ 1580 20;
BA_ "GenMsgSendType" BO_ 1580 5;
BA_ "VFrameFormat" BO_ 1580 14;
BA_ "GenSigSendType" SG_ 2610126865 OTAPhysSOBDMCtoGWM_ECG 3;
BA_ "ECGUsedRxSignal" SG_ 2610126865 OTAPhysSOBDMCtoGWM_ECG 1;
BA_ "U_CD542_MY2021_Rx" SG_ 2610126865 OTAPhysSOBDMCtoGWM_ECG 1;
BA_ "U_U55X_MY2022_Rx" SG_ 2610126865 OTAPhysSOBDMCtoGWM_ECG 1;
BA_ "U_P702_MY2021_Tx" SG_ 2610126865 OTAPhysSOBDMCtoGWM_ECG 1;
BA_ "U_CD542_MY2021_Tx" SG_ 2610126865 OTAPhysSOBDMCtoGWM_ECG 1;
BA_ "U_CDX706_MY2023_Tx" SG_ 2610126865 OTAPhysSOBDMCtoGWM_ECG 1;
BA_ "GenSigSendType" SG_ 2610971864 PARSEDPhysGWM_ECGtoSOBDMC 3;
BA_ "U_P702_MY2021_Rx" SG_ 2610971864 PARSEDPhysGWM_ECGtoSOBDMC 1;
BA_ "U_CD542_MY2021_Rx" SG_ 2610971864 PARSEDPhysGWM_ECGtoSOBDMC 1;
BA_ "U_CDX706_MY2023_Rx" SG_ 2610971864 PARSEDPhysGWM_ECGtoSOBDMC 1;
BA_ "ECGUsedTxSignal" SG_ 2610971864 PARSEDPhysGWM_ECGtoSOBDMC 1;
BA_ "U_CD542_MY2021_Tx" SG_ 2610971864 PARSEDPhysGWM_ECGtoSOBDMC 1;
BA_ "U_U55X_MY2022_Tx" SG_ 2610971864 PARSEDPhysGWM_ECGtoSOBDMC 1;
BA_ "U_CDX706_MY2023_Tx" SG_ 2610971864 PARSEDPhysGWM_ECGtoSOBDMC 1;
BA_ "GenSigSendType" SG_ 2611175441 PARSEDPhysSOBDMCtoGWM_ECG 3;
BA_ "ECGUsedRxSignal" SG_ 2611175441 PARSEDPhysSOBDMCtoGWM_ECG 1;
BA_ "U_CD542_MY2021_Rx" SG_ 2611175441 PARSEDPhysSOBDMCtoGWM_ECG 1;
BA_ "U_U55X_MY2022_Rx" SG_ 2611175441 PARSEDPhysSOBDMCtoGWM_ECG 1;
BA_ "U_CD542_MY2021_Tx" SG_ 2611175441 PARSEDPhysSOBDMCtoGWM_ECG 1;
BA_ "U_CDX706_MY2023_Tx" SG_ 2611175441 PARSEDPhysSOBDMCtoGWM_ECG 1;
BA_ "GenSigSendType" SG_ 2610126946 OTAPhysSODLtoGWM_ECG 3;
BA_ "U_T6_MCA_MY2020_Rx" SG_ 2610126946 OTAPhysSODLtoGWM_ECG 1;
BA_ "ECGUsedRxSignal" SG_ 2610126946 OTAPhysSODLtoGWM_ECG 1;
BA_ "U_CD542_MY2021_Rx" SG_ 2610126946 OTAPhysSODLtoGWM_ECG 1;
BA_ "U_U55X_MY2022_Rx" SG_ 2610126946 OTAPhysSODLtoGWM_ECG 1;
BA_ "U_CDX706_MY2023_Rx" SG_ 2610126946 OTAPhysSODLtoGWM_ECG 1;
BA_ "U_T6_MCA_MY2020_Tx" SG_ 2610126946 OTAPhysSODLtoGWM_ECG 1;
BA_ "U_CD542_MY2021_Tx" SG_ 2610126946 OTAPhysSODLtoGWM_ECG 1;
BA_ "U_U55X_MY2022_Tx" SG_ 2610126946 OTAPhysSODLtoGWM_ECG 1;
BA_ "U_CD764_MY2022_Tx" SG_ 2610126946 OTAPhysSODLtoGWM_ECG 1;
BA_ "U_CDX706_MY2023_Tx" SG_ 2610126946 OTAPhysSODLtoGWM_ECG 1;
BA_ "GenSigSendType" SG_ 2610006232 OTAPhysGWM_ECGtoSODL 3;
BA_ "U_T6_MCA_MY2020_Rx" SG_ 2610006232 OTAPhysGWM_ECGtoSODL 1;
BA_ "U_CD542_MY2021_Rx" SG_ 2610006232 OTAPhysGWM_ECGtoSODL 1;
BA_ "U_U55X_MY2022_Rx" SG_ 2610006232 OTAPhysGWM_ECGtoSODL 1;
BA_ "U_CD764_MY2022_Rx" SG_ 2610006232 OTAPhysGWM_ECGtoSODL 1;
BA_ "U_CDX706_MY2023_Rx" SG_ 2610006232 OTAPhysGWM_ECGtoSODL 1;
BA_ "U_T6_MCA_MY2020_Tx" SG_ 2610006232 OTAPhysGWM_ECGtoSODL 1;
BA_ "ECGUsedTxSignal" SG_ 2610006232 OTAPhysGWM_ECGtoSODL 1;
BA_ "U_CD542_MY2021_Tx" SG_ 2610006232 OTAPhysGWM_ECGtoSODL 1;
BA_ "U_U55X_MY2022_Tx" SG_ 2610006232 OTAPhysGWM_ECGtoSODL 1;
BA_ "U_CDX706_MY2023_Tx" SG_ 2610006232 OTAPhysGWM_ECGtoSODL 1;
BA_ "GenSigSendType" SG_ 1993 TesterPhysicalResCMR_DSMC 3;
BA_ "U_T6_MCA_MY2020_Tx" SG_ 1993 TesterPhysicalResCMR_DSMC 1;
BA_ "U_CD542_MY2021_Tx" SG_ 1993 TesterPhysicalResCMR_DSMC 1;
BA_ "U_U55X_MY2022_Tx" SG_ 1993 TesterPhysicalResCMR_DSMC 1;
BA_ "U_CD764_MY2022_Tx" SG_ 1993 TesterPhysicalResCMR_DSMC 1;
BA_ "U_CDX706_MY2023_Tx" SG_ 1993 TesterPhysicalResCMR_DSMC 1;
BA_ "GenSigSendType" SG_ 1985 TesterPhysicalReqCMR_DSMC 3;
BA_ "U_T6_MCA_MY2020_Rx" SG_ 1985 TesterPhysicalReqCMR_DSMC 1;
BA_ "U_CD542_MY2021_Rx" SG_ 1985 TesterPhysicalReqCMR_DSMC 1;
BA_ "U_U55X_MY2022_Rx" SG_ 1985 TesterPhysicalReqCMR_DSMC 1;
BA_ "U_CD764_MY2022_Rx" SG_ 1985 TesterPhysicalReqCMR_DSMC 1;
BA_ "U_CDX706_MY2023_Rx" SG_ 1985 TesterPhysicalReqCMR_DSMC 1;
BA_ "GenSigStartValueInteger" SG_ 1503 CMR_DSMC_GWOnBoardTester 255;
BA_ "ContentDependant" SG_ 1503 CMR_DSMC_GWOnBoardTester 1;
BA_ "GenSigStartValue" SG_ 1503 CMR_DSMC_GWOnBoardTester 255;
BA_ "U_T6_MCA_MY2020_Tx" SG_ 1503 CMR_DSMC_GWOnBoardTester 1;
BA_ "U_CD542_MY2021_Tx" SG_ 1503 CMR_DSMC_GWOnBoardTester 1;
BA_ "U_U55X_MY2022_Tx" SG_ 1503 CMR_DSMC_GWOnBoardTester 1;
BA_ "U_CD764_MY2022_Tx" SG_ 1503 CMR_DSMC_GWOnBoardTester 1;
BA_ "U_CDX706_MY2023_Tx" SG_ 1503 CMR_DSMC_GWOnBoardTester 1;
BA_ "GenSigStartValueInteger" SG_ 1503 CMR_DSMC_GWNMProxY 255;
BA_ "ContentDependant" SG_ 1503 CMR_DSMC_GWNMProxY 1;
BA_ "GenSigStartValue" SG_ 1503 CMR_DSMC_GWNMProxY 255;
BA_ "U_T6_MCA_MY2020_Tx" SG_ 1503 CMR_DSMC_GWNMProxY 1;
BA_ "U_CD542_MY2021_Tx" SG_ 1503 CMR_DSMC_GWNMProxY 1;
BA_ "U_U55X_MY2022_Tx" SG_ 1503 CMR_DSMC_GWNMProxY 1;
BA_ "U_CD764_MY2022_Tx" SG_ 1503 CMR_DSMC_GWNMProxY 1;
BA_ "U_CDX706_MY2023_Tx" SG_ 1503 CMR_DSMC_GWNMProxY 1;
BA_ "GenSigStartValueInteger" SG_ 1503 CMR_DSMC_AutoSarNMReserved 255;
BA_ "ContentDependant" SG_ 1503 CMR_DSMC_AutoSarNMReserved 1;
BA_ "GenSigStartValue" SG_ 1503 CMR_DSMC_AutoSarNMReserved 255;
BA_ "U_T6_MCA_MY2020_Tx" SG_ 1503 CMR_DSMC_AutoSarNMReserved 1;
BA_ "U_CD542_MY2021_Tx" SG_ 1503 CMR_DSMC_AutoSarNMReserved 1;
BA_ "U_U55X_MY2022_Tx" SG_ 1503 CMR_DSMC_AutoSarNMReserved 1;
BA_ "U_CD764_MY2022_Tx" SG_ 1503 CMR_DSMC_AutoSarNMReserved 1;
BA_ "U_CDX706_MY2023_Tx" SG_ 1503 CMR_DSMC_AutoSarNMReserved 1;
BA_ "GenSigStartValueInteger" SG_ 1503 CMR_DSMC_AutoSarNMReserve4 255;
BA_ "ContentDependant" SG_ 1503 CMR_DSMC_AutoSarNMReserve4 1;
BA_ "GenSigStartValue" SG_ 1503 CMR_DSMC_AutoSarNMReserve4 255;
BA_ "U_T6_MCA_MY2020_Tx" SG_ 1503 CMR_DSMC_AutoSarNMReserve4 1;
BA_ "U_CD542_MY2021_Tx" SG_ 1503 CMR_DSMC_AutoSarNMReserve4 1;
BA_ "U_U55X_MY2022_Tx" SG_ 1503 CMR_DSMC_AutoSarNMReserve4 1;
BA_ "U_CD764_MY2022_Tx" SG_ 1503 CMR_DSMC_AutoSarNMReserve4 1;
BA_ "U_CDX706_MY2023_Tx" SG_ 1503 CMR_DSMC_AutoSarNMReserve4 1;
BA_ "GenSigStartValueInteger" SG_ 1503 CMR_DSMC_AutoSarNMReserve3 255;
BA_ "ContentDependant" SG_ 1503 CMR_DSMC_AutoSarNMReserve3 1;
BA_ "GenSigStartValue" SG_ 1503 CMR_DSMC_AutoSarNMReserve3 255;
BA_ "U_T6_MCA_MY2020_Tx" SG_ 1503 CMR_DSMC_AutoSarNMReserve3 1;
BA_ "U_CD542_MY2021_Tx" SG_ 1503 CMR_DSMC_AutoSarNMReserve3 1;
BA_ "U_U55X_MY2022_Tx" SG_ 1503 CMR_DSMC_AutoSarNMReserve3 1;
BA_ "U_CD764_MY2022_Tx" SG_ 1503 CMR_DSMC_AutoSarNMReserve3 1;
BA_ "U_CDX706_MY2023_Tx" SG_ 1503 CMR_DSMC_AutoSarNMReserve3 1;
BA_ "GenSigStartValueInteger" SG_ 1503 CMR_DSMC_AutoSarNMReserve2 255;
BA_ "ContentDependant" SG_ 1503 CMR_DSMC_AutoSarNMReserve2 1;
BA_ "GenSigStartValue" SG_ 1503 CMR_DSMC_AutoSarNMReserve2 255;
BA_ "U_T6_MCA_MY2020_Tx" SG_ 1503 CMR_DSMC_AutoSarNMReserve2 1;
BA_ "U_CD542_MY2021_Tx" SG_ 1503 CMR_DSMC_AutoSarNMReserve2 1;
BA_ "U_U55X_MY2022_Tx" SG_ 1503 CMR_DSMC_AutoSarNMReserve2 1;
BA_ "U_CD764_MY2022_Tx" SG_ 1503 CMR_DSMC_AutoSarNMReserve2 1;
BA_ "U_CDX706_MY2023_Tx" SG_ 1503 CMR_DSMC_AutoSarNMReserve2 1;
BA_ "GenSigStartValueInteger" SG_ 1503 CMR_DSMC_AutoSarNMNodeId 222;
BA_ "ContentDependant" SG_ 1503 CMR_DSMC_AutoSarNMNodeId 1;
BA_ "GenSigStartValue" SG_ 1503 CMR_DSMC_AutoSarNMNodeId 223;
BA_ "U_T6_MCA_MY2020_Tx" SG_ 1503 CMR_DSMC_AutoSarNMNodeId 1;
BA_ "U_CD542_MY2021_Tx" SG_ 1503 CMR_DSMC_AutoSarNMNodeId 1;
BA_ "U_U55X_MY2022_Tx" SG_ 1503 CMR_DSMC_AutoSarNMNodeId 1;
BA_ "U_CD764_MY2022_Tx" SG_ 1503 CMR_DSMC_AutoSarNMNodeId 1;
BA_ "U_CDX706_MY2023_Tx" SG_ 1503 CMR_DSMC_AutoSarNMNodeId 1;
BA_ "ContentDependant" SG_ 1503 CMR_DSMC_AutoSarNMControl 1;
BA_ "U_T6_MCA_MY2020_Tx" SG_ 1503 CMR_DSMC_AutoSarNMControl 1;
BA_ "U_CD542_MY2021_Tx" SG_ 1503 CMR_DSMC_AutoSarNMControl 1;
BA_ "U_U55X_MY2022_Tx" SG_ 1503 CMR_DSMC_AutoSarNMControl 1;
BA_ "U_CD764_MY2022_Tx" SG_ 1503 CMR_DSMC_AutoSarNMControl 1;
BA_ "U_CDX706_MY2023_Tx" SG_ 1503 CMR_DSMC_AutoSarNMControl 1;
BA_ "U_CX727_MY2021_Rx" SG_ 1119 CoolFanDcdc_D_Rq 1;
BA_ "U_P702_MY2021_Rx" SG_ 1119 CoolFanDcdc_D_Rq 1;
BA_ "U_CD542_MY2021_Rx" SG_ 1119 CoolFanDcdc_D_Rq 1;
BA_ "U_CDX706_MY2023_Rx" SG_ 1119 CoolFanDcdc_D_Rq 1;
BA_ "U_CX727_MY2021_Rx" SG_ 1119 DcdcClntFlw_D_Rq 1;
BA_ "U_P702_MY2021_Rx" SG_ 1119 DcdcClntFlw_D_Rq 1;
BA_ "U_CD542_MY2021_Rx" SG_ 1119 DcdcClntFlw_D_Rq 1;
BA_ "U_CDX706_MY2023_Rx" SG_ 1119 DcdcClntFlw_D_Rq 1;
BA_ "GenSigStartValue" SG_ 1119 PwrSrcULo_Te_Actl 1022;
BA_ "GenSigSendType" SG_ 2022 TesterPhysicalReqSOBDMC 3;
BA_ "U_CX727_MY2021_Rx" SG_ 2022 TesterPhysicalReqSOBDMC 1;
BA_ "U_P702_MY2021_Rx" SG_ 2022 TesterPhysicalReqSOBDMC 1;
BA_ "U_CD542_MY2021_Rx" SG_ 2022 TesterPhysicalReqSOBDMC 1;
BA_ "U_CDX706_MY2023_Rx" SG_ 2022 TesterPhysicalReqSOBDMC 1;
BA_ "U_CX727_MY2021_Rx" SG_ 912 GearPrkMtr_D_Stat 1;
BA_ "U_CD542_MY2021_Rx" SG_ 912 GearPrkMtr_D_Stat 1;
BA_ "U_CX727_MY2021_Rx" SG_ 912 GearPrkLck_D_Stat 1;
BA_ "U_CD542_MY2021_Rx" SG_ 912 GearPrkLck_D_Stat 1;
BA_ "U_CX727_MY2021_Rx" SG_ 912 CabnEvapSovFront_D_Stat 1;
BA_ "U_P702_MY2021_Rx" SG_ 912 CabnEvapSovFront_D_Stat 1;
BA_ "U_CD542_MY2021_Rx" SG_ 912 CabnEvapSovFront_D_Stat 1;
BA_ "U_P702_MY2021_Rx" SG_ 912 BattChlrSov_D_Stat 1;
BA_ "U_CD542_MY2021_Rx" SG_ 912 BattChlrSov_D_Stat 1;
BA_ "U_P702_MY2021_Rx" SG_ 912 BattTracClntVlv_D_Stat 1;
BA_ "U_CD542_MY2021_Rx" SG_ 912 BattTracClntVlv_D_Stat 1;
BA_ "ContentDependant" SG_ 66 immoControlData_T2 1;
BA_ "U_P702_MY2021_Rx" SG_ 66 immoControlData_T2 1;
BA_ "ContentDependant" SG_ 66 immoControlCmd_T2 1;
BA_ "U_P702_MY2021_Rx" SG_ 66 immoControlCmd_T2 1;
BA_ "U_CX727_MY2021_Rx" SG_ 651 TelematicsSrvc_D_St 1;
BA_ "U_P702_MY2021_Rx" SG_ 651 TelematicsSrvc_D_St 1;
BA_ "U_CDX706_MY2023_Rx" SG_ 651 TelematicsSrvc_D_St 1;
BA_ "GenSigStartValue" SG_ 1097 EvseChrg2_U_Mx 4094;
BA_ "U_CX727_MY2021_Rx" SG_ 1097 EvseChrg2_U_Mx 1;
BA_ "GenSigStartValue" SG_ 1097 EvseChrg2_U_Mn 4094;
BA_ "GenSigStartValue" SG_ 1097 EvseChrg2_I_Mx 32766;
BA_ "U_CX727_MY2021_Rx" SG_ 1097 EvseChrg2_I_Mx 1;
BA_ "GenSigStartValue" SG_ 1097 EvseChrg2_I_Mn 32766;
BA_ "GenSigStartValueInteger" SG_ 607 EvseDcChrgIso_D_Stat 6;
BA_ "GenSigStartValue" SG_ 607 EvseDcChrgIso_D_Stat 6;
BA_ "WakeupSignal" SG_ 607 DcChrgWarnLamp_B_Rq 1;
BA_ "GenSigStartValue" SG_ 607 EvseChrg2_Pw_Mx 32766;
BA_ "GenSigSendType" SG_ 2609955032 OTAPhysGWM_ECGtoPSCM 3;
BA_ "U_CD542_MY2021_Rx" SG_ 2609955032 OTAPhysGWM_ECGtoPSCM 1;
BA_ "U_U55X_MY2022_Rx" SG_ 2609955032 OTAPhysGWM_ECGtoPSCM 1;
BA_ "U_CD764_MY2022_Rx" SG_ 2609955032 OTAPhysGWM_ECGtoPSCM 1;
BA_ "U_CDX706_MY2023_Rx" SG_ 2609955032 OTAPhysGWM_ECGtoPSCM 1;
BA_ "ECGUsedTxSignal" SG_ 2609955032 OTAPhysGWM_ECGtoPSCM 1;
BA_ "U_CD542_MY2021_Tx" SG_ 2609955032 OTAPhysGWM_ECGtoPSCM 1;
BA_ "U_U55X_MY2022_Tx" SG_ 2609955032 OTAPhysGWM_ECGtoPSCM 1;
BA_ "U_CD764_MY2022_Tx" SG_ 2609955032 OTAPhysGWM_ECGtoPSCM 1;
BA_ "U_CDX706_MY2023_Tx" SG_ 2609955032 OTAPhysGWM_ECGtoPSCM 1;
BA_ "GenSigSendType" SG_ 2610126896 OTAPhysPSCMtoGWM_ECG 3;
BA_ "ECGUsedRxSignal" SG_ 2610126896 OTAPhysPSCMtoGWM_ECG 1;
BA_ "U_CD542_MY2021_Rx" SG_ 2610126896 OTAPhysPSCMtoGWM_ECG 1;
BA_ "U_U55X_MY2022_Rx" SG_ 2610126896 OTAPhysPSCMtoGWM_ECG 1;
BA_ "U_CD764_MY2022_Rx" SG_ 2610126896 OTAPhysPSCMtoGWM_ECG 1;
BA_ "U_CDX706_MY2023_Rx" SG_ 2610126896 OTAPhysPSCMtoGWM_ECG 1;
BA_ "U_CD542_MY2021_Tx" SG_ 2610126896 OTAPhysPSCMtoGWM_ECG 1;
BA_ "U_U55X_MY2022_Tx" SG_ 2610126896 OTAPhysPSCMtoGWM_ECG 1;
BA_ "U_CD764_MY2022_Tx" SG_ 2610126896 OTAPhysPSCMtoGWM_ECG 1;
BA_ "U_CDX706_MY2023_Tx" SG_ 2610126896 OTAPhysPSCMtoGWM_ECG 1;
BA_ "GenSigSendType" SG_ 2611003608 PARSEDPhysGWM_ECGtoPSCM 3;
BA_ "U_CD542_MY2021_Rx" SG_ 2611003608 PARSEDPhysGWM_ECGtoPSCM 1;
BA_ "U_U55X_MY2022_Rx" SG_ 2611003608 PARSEDPhysGWM_ECGtoPSCM 1;
BA_ "U_CD764_MY2022_Rx" SG_ 2611003608 PARSEDPhysGWM_ECGtoPSCM 1;
BA_ "U_CDX706_MY2023_Rx" SG_ 2611003608 PARSEDPhysGWM_ECGtoPSCM 1;
BA_ "ECGUsedTxSignal" SG_ 2611003608 PARSEDPhysGWM_ECGtoPSCM 1;
BA_ "U_CD542_MY2021_Tx" SG_ 2611003608 PARSEDPhysGWM_ECGtoPSCM 1;
BA_ "U_U55X_MY2022_Tx" SG_ 2611003608 PARSEDPhysGWM_ECGtoPSCM 1;
BA_ "U_CD764_MY2022_Tx" SG_ 2611003608 PARSEDPhysGWM_ECGtoPSCM 1;
BA_ "U_CDX706_MY2023_Tx" SG_ 2611003608 PARSEDPhysGWM_ECGtoPSCM 1;
BA_ "GenSigSendType" SG_ 2612224048 PARSEDPushPSCMtoGWM_ECG 3;
BA_ "ECGUsedRxSignal" SG_ 2612224048 PARSEDPushPSCMtoGWM_ECG 1;
BA_ "U_CD542_MY2021_Rx" SG_ 2612224048 PARSEDPushPSCMtoGWM_ECG 1;
BA_ "U_U55X_MY2022_Rx" SG_ 2612224048 PARSEDPushPSCMtoGWM_ECG 1;
BA_ "U_CD764_MY2022_Rx" SG_ 2612224048 PARSEDPushPSCMtoGWM_ECG 1;
BA_ "U_CDX706_MY2023_Rx" SG_ 2612224048 PARSEDPushPSCMtoGWM_ECG 1;
BA_ "U_CD542_MY2021_Tx" SG_ 2612224048 PARSEDPushPSCMtoGWM_ECG 1;
BA_ "U_U55X_MY2022_Tx" SG_ 2612224048 PARSEDPushPSCMtoGWM_ECG 1;
BA_ "U_CD764_MY2022_Tx" SG_ 2612224048 PARSEDPushPSCMtoGWM_ECG 1;
BA_ "U_CDX706_MY2023_Tx" SG_ 2612224048 PARSEDPushPSCMtoGWM_ECG 1;
BA_ "GenSigSendType" SG_ 2611175472 PARSEDPhysPSCMtoGWM_ECG 3;
BA_ "ECGUsedRxSignal" SG_ 2611175472 PARSEDPhysPSCMtoGWM_ECG 1;
BA_ "U_CD542_MY2021_Rx" SG_ 2611175472 PARSEDPhysPSCMtoGWM_ECG 1;
BA_ "U_U55X_MY2022_Rx" SG_ 2611175472 PARSEDPhysPSCMtoGWM_ECG 1;
BA_ "U_CD764_MY2022_Rx" SG_ 2611175472 PARSEDPhysPSCMtoGWM_ECG 1;
BA_ "U_CDX706_MY2023_Rx" SG_ 2611175472 PARSEDPhysPSCMtoGWM_ECG 1;
BA_ "U_CD542_MY2021_Tx" SG_ 2611175472 PARSEDPhysPSCMtoGWM_ECG 1;
BA_ "U_U55X_MY2022_Tx" SG_ 2611175472 PARSEDPhysPSCMtoGWM_ECG 1;
BA_ "U_CD764_MY2022_Tx" SG_ 2611175472 PARSEDPhysPSCMtoGWM_ECG 1;
BA_ "U_CDX706_MY2023_Tx" SG_ 2611175472 PARSEDPhysPSCMtoGWM_ECG 1;
BA_ "U_CX727_MY2021_Rx" SG_ 1150 LocationServices_1 1;
BA_ "U_T6_MCA_MY2020_Rx" SG_ 1150 LocationServices_1 1;
BA_ "U_CD542_MY2021_Rx" SG_ 1150 LocationServices_1 1;
BA_ "U_U55X_MY2022_Rx" SG_ 1150 LocationServices_1 1;
BA_ "U_CDX706_MY2023_Rx" SG_ 1150 LocationServices_1 1;
BA_ "GenSigSendType" SG_ 2612224033 PARSEDPushIPMAtoGWM_ECG 3;
BA_ "U_T6_MCA_MY2020_Rx" SG_ 2612224033 PARSEDPushIPMAtoGWM_ECG 1;
BA_ "ECGUsedRxSignal" SG_ 2612224033 PARSEDPushIPMAtoGWM_ECG 1;
BA_ "U_CD542_MY2021_Rx" SG_ 2612224033 PARSEDPushIPMAtoGWM_ECG 1;
BA_ "U_U55X_MY2022_Rx" SG_ 2612224033 PARSEDPushIPMAtoGWM_ECG 1;
BA_ "U_CD764_MY2022_Rx" SG_ 2612224033 PARSEDPushIPMAtoGWM_ECG 1;
BA_ "U_CDX706_MY2023_Rx" SG_ 2612224033 PARSEDPushIPMAtoGWM_ECG 1;
BA_ "U_T6_MCA_MY2020_Tx" SG_ 2612224033 PARSEDPushIPMAtoGWM_ECG 1;
BA_ "U_CD542_MY2021_Tx" SG_ 2612224033 PARSEDPushIPMAtoGWM_ECG 1;
BA_ "U_U55X_MY2022_Tx" SG_ 2612224033 PARSEDPushIPMAtoGWM_ECG 1;
BA_ "U_CD764_MY2022_Tx" SG_ 2612224033 PARSEDPushIPMAtoGWM_ECG 1;
BA_ "U_CDX706_MY2023_Tx" SG_ 2612224033 PARSEDPushIPMAtoGWM_ECG 1;
BA_ "GenSigSendType" SG_ 2609939672 OTAPhysGWM_ECGtoIPMA 3;
BA_ "U_T6_MCA_MY2020_Rx" SG_ 2609939672 OTAPhysGWM_ECGtoIPMA 1;
BA_ "U_CD542_MY2021_Rx" SG_ 2609939672 OTAPhysGWM_ECGtoIPMA 1;
BA_ "U_U55X_MY2022_Rx" SG_ 2609939672 OTAPhysGWM_ECGtoIPMA 1;
BA_ "U_CD764_MY2022_Rx" SG_ 2609939672 OTAPhysGWM_ECGtoIPMA 1;
BA_ "U_CDX706_MY2023_Rx" SG_ 2609939672 OTAPhysGWM_ECGtoIPMA 1;
BA_ "U_T6_MCA_MY2020_Tx" SG_ 2609939672 OTAPhysGWM_ECGtoIPMA 1;
BA_ "ECGUsedTxSignal" SG_ 2609939672 OTAPhysGWM_ECGtoIPMA 1;
BA_ "U_CD542_MY2021_Tx" SG_ 2609939672 OTAPhysGWM_ECGtoIPMA 1;
BA_ "U_U55X_MY2022_Tx" SG_ 2609939672 OTAPhysGWM_ECGtoIPMA 1;
BA_ "U_CD764_MY2022_Tx" SG_ 2609939672 OTAPhysGWM_ECGtoIPMA 1;
BA_ "U_CDX706_MY2023_Tx" SG_ 2609939672 OTAPhysGWM_ECGtoIPMA 1;
BA_ "GenSigSendType" SG_ 2610126881 OTAPhysIPMAtoGWM_ECG 3;
BA_ "U_T6_MCA_MY2020_Rx" SG_ 2610126881 OTAPhysIPMAtoGWM_ECG 1;
BA_ "ECGUsedRxSignal" SG_ 2610126881 OTAPhysIPMAtoGWM_ECG 1;
BA_ "U_CD542_MY2021_Rx" SG_ 2610126881 OTAPhysIPMAtoGWM_ECG 1;
BA_ "U_U55X_MY2022_Rx" SG_ 2610126881 OTAPhysIPMAtoGWM_ECG 1;
BA_ "U_CD764_MY2022_Rx" SG_ 2610126881 OTAPhysIPMAtoGWM_ECG 1;
BA_ "U_CDX706_MY2023_Rx" SG_ 2610126881 OTAPhysIPMAtoGWM_ECG 1;
BA_ "U_T6_MCA_MY2020_Tx" SG_ 2610126881 OTAPhysIPMAtoGWM_ECG 1;
BA_ "U_CD542_MY2021_Tx" SG_ 2610126881 OTAPhysIPMAtoGWM_ECG 1;
BA_ "U_U55X_MY2022_Tx" SG_ 2610126881 OTAPhysIPMAtoGWM_ECG 1;
BA_ "U_CD764_MY2022_Tx" SG_ 2610126881 OTAPhysIPMAtoGWM_ECG 1;
BA_ "U_CDX706_MY2023_Tx" SG_ 2610126881 OTAPhysIPMAtoGWM_ECG 1;
BA_ "GenSigSendType" SG_ 2612043992 PARSEDPushFcGWM_ECGtoABS 3;
BA_ "U_T6_MCA_MY2020_Rx" SG_ 2612043992 PARSEDPushFcGWM_ECGtoABS 1;
BA_ "U_CD542_MY2021_Rx" SG_ 2612043992 PARSEDPushFcGWM_ECGtoABS 1;
BA_ "U_U55X_MY2022_Rx" SG_ 2612043992 PARSEDPushFcGWM_ECGtoABS 1;
BA_ "U_CD764_MY2022_Rx" SG_ 2612043992 PARSEDPushFcGWM_ECGtoABS 1;
BA_ "U_CDX706_MY2023_Rx" SG_ 2612043992 PARSEDPushFcGWM_ECGtoABS 1;
BA_ "U_T6_MCA_MY2020_Tx" SG_ 2612043992 PARSEDPushFcGWM_ECGtoABS 1;
BA_ "ECGUsedTxSignal" SG_ 2612043992 PARSEDPushFcGWM_ECGtoABS 1;
BA_ "U_CD542_MY2021_Tx" SG_ 2612043992 PARSEDPushFcGWM_ECGtoABS 1;
BA_ "U_U55X_MY2022_Tx" SG_ 2612043992 PARSEDPushFcGWM_ECGtoABS 1;
BA_ "U_CD764_MY2022_Tx" SG_ 2612043992 PARSEDPushFcGWM_ECGtoABS 1;
BA_ "U_CDX706_MY2023_Tx" SG_ 2612043992 PARSEDPushFcGWM_ECGtoABS 1;
BA_ "GenSigSendType" SG_ 2610995416 PARSEDPhysGWM_ECGtoABS 3;
BA_ "U_T6_MCA_MY2020_Rx" SG_ 2610995416 PARSEDPhysGWM_ECGtoABS 1;
BA_ "U_CD542_MY2021_Rx" SG_ 2610995416 PARSEDPhysGWM_ECGtoABS 1;
BA_ "U_U55X_MY2022_Rx" SG_ 2610995416 PARSEDPhysGWM_ECGtoABS 1;
BA_ "U_CD764_MY2022_Rx" SG_ 2610995416 PARSEDPhysGWM_ECGtoABS 1;
BA_ "U_CDX706_MY2023_Rx" SG_ 2610995416 PARSEDPhysGWM_ECGtoABS 1;
BA_ "U_T6_MCA_MY2020_Tx" SG_ 2610995416 PARSEDPhysGWM_ECGtoABS 1;
BA_ "ECGUsedTxSignal" SG_ 2610995416 PARSEDPhysGWM_ECGtoABS 1;
BA_ "U_CD542_MY2021_Tx" SG_ 2610995416 PARSEDPhysGWM_ECGtoABS 1;
BA_ "U_U55X_MY2022_Tx" SG_ 2610995416 PARSEDPhysGWM_ECGtoABS 1;
BA_ "U_CD764_MY2022_Tx" SG_ 2610995416 PARSEDPhysGWM_ECGtoABS 1;
BA_ "U_CDX706_MY2023_Tx" SG_ 2610995416 PARSEDPhysGWM_ECGtoABS 1;
BA_ "GenSigSendType" SG_ 2612224040 PARSEDPushABStoGWM_ECG 3;
BA_ "U_T6_MCA_MY2020_Rx" SG_ 2612224040 PARSEDPushABStoGWM_ECG 1;
BA_ "ECGUsedRxSignal" SG_ 2612224040 PARSEDPushABStoGWM_ECG 1;
BA_ "U_CD542_MY2021_Rx" SG_ 2612224040 PARSEDPushABStoGWM_ECG 1;
BA_ "U_U55X_MY2022_Rx" SG_ 2612224040 PARSEDPushABStoGWM_ECG 1;
BA_ "U_CD764_MY2022_Rx" SG_ 2612224040 PARSEDPushABStoGWM_ECG 1;
BA_ "U_CDX706_MY2023_Rx" SG_ 2612224040 PARSEDPushABStoGWM_ECG 1;
BA_ "U_T6_MCA_MY2020_Tx" SG_ 2612224040 PARSEDPushABStoGWM_ECG 1;
BA_ "U_CD542_MY2021_Tx" SG_ 2612224040 PARSEDPushABStoGWM_ECG 1;
BA_ "U_U55X_MY2022_Tx" SG_ 2612224040 PARSEDPushABStoGWM_ECG 1;
BA_ "U_CD764_MY2022_Tx" SG_ 2612224040 PARSEDPushABStoGWM_ECG 1;
BA_ "U_CDX706_MY2023_Tx" SG_ 2612224040 PARSEDPushABStoGWM_ECG 1;
BA_ "GenSigSendType" SG_ 2611175464 PARSEDPhysABStoGWM_ECG 3;
BA_ "U_T6_MCA_MY2020_Rx" SG_ 2611175464 PARSEDPhysABStoGWM_ECG 1;
BA_ "ECGUsedRxSignal" SG_ 2611175464 PARSEDPhysABStoGWM_ECG 1;
BA_ "U_CD542_MY2021_Rx" SG_ 2611175464 PARSEDPhysABStoGWM_ECG 1;
BA_ "U_U55X_MY2022_Rx" SG_ 2611175464 PARSEDPhysABStoGWM_ECG 1;
BA_ "U_CD764_MY2022_Rx" SG_ 2611175464 PARSEDPhysABStoGWM_ECG 1;
BA_ "U_CDX706_MY2023_Rx" SG_ 2611175464 PARSEDPhysABStoGWM_ECG 1;
BA_ "U_T6_MCA_MY2020_Tx" SG_ 2611175464 PARSEDPhysABStoGWM_ECG 1;
BA_ "U_CD542_MY2021_Tx" SG_ 2611175464 PARSEDPhysABStoGWM_ECG 1;
BA_ "U_U55X_MY2022_Tx" SG_ 2611175464 PARSEDPhysABStoGWM_ECG 1;
BA_ "U_CD764_MY2022_Tx" SG_ 2611175464 PARSEDPhysABStoGWM_ECG 1;
BA_ "U_CDX706_MY2023_Tx" SG_ 2611175464 PARSEDPhysABStoGWM_ECG 1;
BA_ "GenSigSendType" SG_ 1082 SelDrvMdeStabBar_D_Stat 3;
BA_ "U_T6_MCA_MY2020_Rx" SG_ 1082 SelDrvMdeStabBar_D_Stat 1;
BA_ "U_T6_MCA_MY2020_Tx" SG_ 1082 SelDrvMdeStabBar_D_Stat 1;
BA_ "GenSigSendType" SG_ 1082 StabBarFaltMsgTxt_D_Rq 3;
BA_ "U_T6_MCA_MY2020_Tx" SG_ 1082 StabBarFaltMsgTxt_D_Rq 1;
BA_ "GenSigSendType" SG_ 1082 StabBarCnnctLamp_D_Rq 3;
BA_ "U_T6_MCA_MY2020_Rx" SG_ 1082 StabBarCnnctLamp_D_Rq 1;
BA_ "ECGUsedRxSignal" SG_ 1082 StabBarCnnctLamp_D_Rq 1;
BA_ "U_CD542_MY2021_Rx" SG_ 1082 StabBarCnnctLamp_D_Rq 1;
BA_ "U_CD764_MY2022_Rx" SG_ 1082 StabBarCnnctLamp_D_Rq 1;
BA_ "U_CDX706_MY2023_Rx" SG_ 1082 StabBarCnnctLamp_D_Rq 1;
BA_ "U_T6_MCA_MY2020_Tx" SG_ 1082 StabBarCnnctLamp_D_Rq 1;
BA_ "GenSigSendType" SG_ 1082 StabBarCnnct_D_Stat 3;
BA_ "U_T6_MCA_MY2020_Rx" SG_ 1082 StabBarCnnct_D_Stat 1;
BA_ "U_T6_MCA_MY2020_Tx" SG_ 1082 StabBarCnnct_D_Stat 1;
BA_ "GenSigSendType" SG_ 1082 StabBarCnncMsgTxt_D_Rq 3;
BA_ "U_T6_MCA_MY2020_Tx" SG_ 1082 StabBarCnncMsgTxt_D_Rq 1;
BA_ "U_CX727_MY2021_Rx" SG_ 529 OnbChrgToPcWknd_D_Actl 1;
BA_ "U_P702_MY2021_Rx" SG_ 529 OnbChrgToPcWknd_D_Actl 1;
BA_ "U_CD542_MY2021_Rx" SG_ 529 OnbChrgToPcWknd_D_Actl 1;
BA_ "U_CX727_MY2021_Rx" SG_ 529 OnbChrgToPcWkdy_D_Actl 1;
BA_ "U_P702_MY2021_Rx" SG_ 529 OnbChrgToPcWkdy_D_Actl 1;
BA_ "U_CD542_MY2021_Rx" SG_ 529 OnbChrgToPcWkdy_D_Actl 1;
BA_ "U_CX727_MY2021_Rx" SG_ 529 OnbChrgSetNow_D_Rq 1;
BA_ "U_P702_MY2021_Rx" SG_ 529 OnbChrgSetNow_D_Rq 1;
BA_ "U_CD542_MY2021_Rx" SG_ 529 OnbChrgSetNow_D_Rq 1;
BA_ "U_CX727_MY2021_Rx" SG_ 529 OnbChrgSetDelete_B_Rq 1;
BA_ "U_P702_MY2021_Rx" SG_ 529 OnbChrgSetDelete_B_Rq 1;
BA_ "U_CD542_MY2021_Rx" SG_ 529 OnbChrgSetDelete_B_Rq 1;
BA_ "U_CX727_MY2021_Rx" SG_ 529 OnbChrgPrflWknd_No_Rq 1;
BA_ "U_P702_MY2021_Rx" SG_ 529 OnbChrgPrflWknd_No_Rq 1;
BA_ "U_CD542_MY2021_Rx" SG_ 529 OnbChrgPrflWknd_No_Rq 1;
BA_ "U_CX727_MY2021_Rx" SG_ 529 OnbChrgPrflWkdy_No_Rq 1;
BA_ "U_P702_MY2021_Rx" SG_ 529 OnbChrgPrflWkdy_No_Rq 1;
BA_ "U_CD542_MY2021_Rx" SG_ 529 OnbChrgPrflWkdy_No_Rq 1;
BA_ "U_CX727_MY2021_Rx" SG_ 529 OnbChrgPrflUpdate_B_Rq 1;
BA_ "U_P702_MY2021_Rx" SG_ 529 OnbChrgPrflUpdate_B_Rq 1;
BA_ "U_CD542_MY2021_Rx" SG_ 529 OnbChrgPrflUpdate_B_Rq 1;
BA_ "U_CX727_MY2021_Rx" SG_ 529 OnbChrgLocIdUns_B_Rq 1;
BA_ "U_P702_MY2021_Rx" SG_ 529 OnbChrgLocIdUns_B_Rq 1;
BA_ "U_CD542_MY2021_Rx" SG_ 529 OnbChrgLocIdUns_B_Rq 1;
BA_ "U_CX727_MY2021_Rx" SG_ 529 OnbChrgLocIdTrgt_No_Rq 1;
BA_ "U_P702_MY2021_Rx" SG_ 529 OnbChrgLocIdTrgt_No_Rq 1;
BA_ "U_CD542_MY2021_Rx" SG_ 529 OnbChrgLocIdTrgt_No_Rq 1;
BA_ "GenSigSendType" SG_ 1679 UUDTSOBDMCResponse4 3;
BA_ "U_CX727_MY2021_Tx" SG_ 1679 UUDTSOBDMCResponse4 1;
BA_ "U_P702_MY2021_Tx" SG_ 1679 UUDTSOBDMCResponse4 1;
BA_ "U_CD542_MY2021_Tx" SG_ 1679 UUDTSOBDMCResponse4 1;
BA_ "U_CDX706_MY2023_Tx" SG_ 1679 UUDTSOBDMCResponse4 1;
BA_ "GenSigSendType" SG_ 1678 UUDTSOBDMCResponse3 3;
BA_ "U_CX727_MY2021_Tx" SG_ 1678 UUDTSOBDMCResponse3 1;
BA_ "U_P702_MY2021_Tx" SG_ 1678 UUDTSOBDMCResponse3 1;
BA_ "U_CD542_MY2021_Tx" SG_ 1678 UUDTSOBDMCResponse3 1;
BA_ "U_CDX706_MY2023_Tx" SG_ 1678 UUDTSOBDMCResponse3 1;
BA_ "GenSigSendType" SG_ 1677 UUDTSOBDMCResponse2 3;
BA_ "U_CX727_MY2021_Tx" SG_ 1677 UUDTSOBDMCResponse2 1;
BA_ "U_P702_MY2021_Tx" SG_ 1677 UUDTSOBDMCResponse2 1;
BA_ "U_CD542_MY2021_Tx" SG_ 1677 UUDTSOBDMCResponse2 1;
BA_ "U_CDX706_MY2023_Tx" SG_ 1677 UUDTSOBDMCResponse2 1;
BA_ "GenSigSendType" SG_ 1676 UUDTSOBDMCResponse1 3;
BA_ "U_CX727_MY2021_Tx" SG_ 1676 UUDTSOBDMCResponse1 1;
BA_ "U_P702_MY2021_Tx" SG_ 1676 UUDTSOBDMCResponse1 1;
BA_ "U_CD542_MY2021_Tx" SG_ 1676 UUDTSOBDMCResponse1 1;
BA_ "U_CDX706_MY2023_Tx" SG_ 1676 UUDTSOBDMCResponse1 1;
BA_ "GenSigStartValueInteger" SG_ 1445 SOBDMC_AutoSarNMReserved4 255;
BA_ "ContentDependant" SG_ 1445 SOBDMC_AutoSarNMReserved4 1;
BA_ "GenSigStartValue" SG_ 1445 SOBDMC_AutoSarNMReserved4 255;
BA_ "U_CX727_MY2021_Rx" SG_ 1445 SOBDMC_AutoSarNMReserved4 1;
BA_ "U_CD542_MY2021_Rx" SG_ 1445 SOBDMC_AutoSarNMReserved4 1;
BA_ "U_CDX706_MY2023_Rx" SG_ 1445 SOBDMC_AutoSarNMReserved4 1;
BA_ "U_CX727_MY2021_Tx" SG_ 1445 SOBDMC_AutoSarNMReserved4 1;
BA_ "U_P702_MY2021_Tx" SG_ 1445 SOBDMC_AutoSarNMReserved4 1;
BA_ "U_CD542_MY2021_Tx" SG_ 1445 SOBDMC_AutoSarNMReserved4 1;
BA_ "U_CDX706_MY2023_Tx" SG_ 1445 SOBDMC_AutoSarNMReserved4 1;
BA_ "GenSigStartValueInteger" SG_ 1445 SOBDMC_AutoSarNMReserved3 255;
BA_ "ContentDependant" SG_ 1445 SOBDMC_AutoSarNMReserved3 1;
BA_ "GenSigStartValue" SG_ 1445 SOBDMC_AutoSarNMReserved3 255;
BA_ "U_CX727_MY2021_Rx" SG_ 1445 SOBDMC_AutoSarNMReserved3 1;
BA_ "U_CD542_MY2021_Rx" SG_ 1445 SOBDMC_AutoSarNMReserved3 1;
BA_ "U_CDX706_MY2023_Rx" SG_ 1445 SOBDMC_AutoSarNMReserved3 1;
BA_ "U_CX727_MY2021_Tx" SG_ 1445 SOBDMC_AutoSarNMReserved3 1;
BA_ "U_P702_MY2021_Tx" SG_ 1445 SOBDMC_AutoSarNMReserved3 1;
BA_ "U_CD542_MY2021_Tx" SG_ 1445 SOBDMC_AutoSarNMReserved3 1;
BA_ "U_CDX706_MY2023_Tx" SG_ 1445 SOBDMC_AutoSarNMReserved3 1;
BA_ "GenSigStartValueInteger" SG_ 1445 SOBDMC_AutoSarNMReserved2 255;
BA_ "ContentDependant" SG_ 1445 SOBDMC_AutoSarNMReserved2 1;
BA_ "GenSigStartValue" SG_ 1445 SOBDMC_AutoSarNMReserved2 255;
BA_ "U_CX727_MY2021_Rx" SG_ 1445 SOBDMC_AutoSarNMReserved2 1;
BA_ "U_CD542_MY2021_Rx" SG_ 1445 SOBDMC_AutoSarNMReserved2 1;
BA_ "U_CDX706_MY2023_Rx" SG_ 1445 SOBDMC_AutoSarNMReserved2 1;
BA_ "U_CX727_MY2021_Tx" SG_ 1445 SOBDMC_AutoSarNMReserved2 1;
BA_ "U_P702_MY2021_Tx" SG_ 1445 SOBDMC_AutoSarNMReserved2 1;
BA_ "U_CD542_MY2021_Tx" SG_ 1445 SOBDMC_AutoSarNMReserved2 1;
BA_ "U_CDX706_MY2023_Tx" SG_ 1445 SOBDMC_AutoSarNMReserved2 1;
BA_ "GenSigStartValueInteger" SG_ 1445 SOBDMC_AutoSarNMReserved1 255;
BA_ "ContentDependant" SG_ 1445 SOBDMC_AutoSarNMReserved1 1;
BA_ "GenSigStartValue" SG_ 1445 SOBDMC_AutoSarNMReserved1 255;
BA_ "U_CX727_MY2021_Rx" SG_ 1445 SOBDMC_AutoSarNMReserved1 1;
BA_ "U_CD542_MY2021_Rx" SG_ 1445 SOBDMC_AutoSarNMReserved1 1;
BA_ "U_CDX706_MY2023_Rx" SG_ 1445 SOBDMC_AutoSarNMReserved1 1;
BA_ "U_CX727_MY2021_Tx" SG_ 1445 SOBDMC_AutoSarNMReserved1 1;
BA_ "U_P702_MY2021_Tx" SG_ 1445 SOBDMC_AutoSarNMReserved1 1;
BA_ "U_CD542_MY2021_Tx" SG_ 1445 SOBDMC_AutoSarNMReserved1 1;
BA_ "U_CDX706_MY2023_Tx" SG_ 1445 SOBDMC_AutoSarNMReserved1 1;
BA_ "GenSigStartValueInteger" SG_ 1445 SOBDMC_AutoSarNMNodeId 165;
BA_ "ContentDependant" SG_ 1445 SOBDMC_AutoSarNMNodeId 1;
BA_ "GenSigStartValue" SG_ 1445 SOBDMC_AutoSarNMNodeId 165;
BA_ "U_CX727_MY2021_Rx" SG_ 1445 SOBDMC_AutoSarNMNodeId 1;
BA_ "U_CD542_MY2021_Rx" SG_ 1445 SOBDMC_AutoSarNMNodeId 1;
BA_ "U_CDX706_MY2023_Rx" SG_ 1445 SOBDMC_AutoSarNMNodeId 1;
BA_ "U_CX727_MY2021_Tx" SG_ 1445 SOBDMC_AutoSarNMNodeId 1;
BA_ "U_P702_MY2021_Tx" SG_ 1445 SOBDMC_AutoSarNMNodeId 1;
BA_ "U_CD542_MY2021_Tx" SG_ 1445 SOBDMC_AutoSarNMNodeId 1;
BA_ "U_CDX706_MY2023_Tx" SG_ 1445 SOBDMC_AutoSarNMNodeId 1;
BA_ "ContentDependant" SG_ 1445 SOBDMC_AutoSarNMControl 1;
BA_ "U_CX727_MY2021_Rx" SG_ 1445 SOBDMC_AutoSarNMControl 1;
BA_ "U_CD542_MY2021_Rx" SG_ 1445 SOBDMC_AutoSarNMControl 1;
BA_ "U_CDX706_MY2023_Rx" SG_ 1445 SOBDMC_AutoSarNMControl 1;
BA_ "U_CX727_MY2021_Tx" SG_ 1445 SOBDMC_AutoSarNMControl 1;
BA_ "U_P702_MY2021_Tx" SG_ 1445 SOBDMC_AutoSarNMControl 1;
BA_ "U_CD542_MY2021_Tx" SG_ 1445 SOBDMC_AutoSarNMControl 1;
BA_ "U_CDX706_MY2023_Tx" SG_ 1445 SOBDMC_AutoSarNMControl 1;
BA_ "GenSigStartValueInteger" SG_ 1445 SOBDMC_GWOnBoardTester 255;
BA_ "ContentDependant" SG_ 1445 SOBDMC_GWOnBoardTester 1;
BA_ "GenSigStartValue" SG_ 1445 SOBDMC_GWOnBoardTester 255;
BA_ "U_CX727_MY2021_Rx" SG_ 1445 SOBDMC_GWOnBoardTester 1;
BA_ "U_CD542_MY2021_Rx" SG_ 1445 SOBDMC_GWOnBoardTester 1;
BA_ "U_CDX706_MY2023_Rx" SG_ 1445 SOBDMC_GWOnBoardTester 1;
BA_ "U_CX727_MY2021_Tx" SG_ 1445 SOBDMC_GWOnBoardTester 1;
BA_ "U_P702_MY2021_Tx" SG_ 1445 SOBDMC_GWOnBoardTester 1;
BA_ "U_CD542_MY2021_Tx" SG_ 1445 SOBDMC_GWOnBoardTester 1;
BA_ "U_CDX706_MY2023_Tx" SG_ 1445 SOBDMC_GWOnBoardTester 1;
BA_ "GenSigStartValueInteger" SG_ 1445 SOBDMC_GWNMProxy 255;
BA_ "ContentDependant" SG_ 1445 SOBDMC_GWNMProxy 1;
BA_ "GenSigStartValue" SG_ 1445 SOBDMC_GWNMProxy 255;
BA_ "U_CX727_MY2021_Rx" SG_ 1445 SOBDMC_GWNMProxy 1;
BA_ "U_CD542_MY2021_Rx" SG_ 1445 SOBDMC_GWNMProxy 1;
BA_ "U_CDX706_MY2023_Rx" SG_ 1445 SOBDMC_GWNMProxy 1;
BA_ "U_CX727_MY2021_Tx" SG_ 1445 SOBDMC_GWNMProxy 1;
BA_ "U_P702_MY2021_Tx" SG_ 1445 SOBDMC_GWNMProxy 1;
BA_ "U_CD542_MY2021_Tx" SG_ 1445 SOBDMC_GWNMProxy 1;
BA_ "U_CDX706_MY2023_Tx" SG_ 1445 SOBDMC_GWNMProxy 1;
BA_ "U_CX727_MY2021_Tx" SG_ 1143 EffAvgChrg_Pc_Dsply 1;
BA_ "U_CD542_MY2021_Tx" SG_ 1143 EffAvgChrg_Pc_Dsply 1;
BA_ "ECGUsedRxSignal" SG_ 1143 ConsTipUnitPt_D_Dsply 1;
BA_ "U_CD542_MY2021_Rx" SG_ 1143 ConsTipUnitPt_D_Dsply 1;
BA_ "U_U55X_MY2022_Rx" SG_ 1143 ConsTipUnitPt_D_Dsply 1;
BA_ "U_CX727_MY2021_Tx" SG_ 1143 ConsTipUnitPt_D_Dsply 1;
BA_ "U_CD542_MY2021_Tx" SG_ 1143 ConsTipUnitPt_D_Dsply 1;
BA_ "U_CDX706_MY2023_Tx" SG_ 1143 ConsTipUnitPt_D_Dsply 1;
BA_ "GenSigStartValueInteger" SG_ 1143 ConsTipTot_Pc_Dsply 1022;
BA_ "GenSigStartValue" SG_ 1143 ConsTipTot_Pc_Dsply 1022;
BA_ "ECGUsedRxSignal" SG_ 1143 ConsTipTot_Pc_Dsply 1;
BA_ "U_CD542_MY2021_Rx" SG_ 1143 ConsTipTot_Pc_Dsply 1;
BA_ "U_U55X_MY2022_Rx" SG_ 1143 ConsTipTot_Pc_Dsply 1;
BA_ "U_CX727_MY2021_Tx" SG_ 1143 ConsTipTot_Pc_Dsply 1;
BA_ "U_CD542_MY2021_Tx" SG_ 1143 ConsTipTot_Pc_Dsply 1;
BA_ "U_CDX706_MY2023_Tx" SG_ 1143 ConsTipTot_Pc_Dsply 1;
BA_ "U_CX727_MY2021_Tx" SG_ 1143 ChrgCompltMsgTxt_D_Rq 1;
BA_ "U_CD542_MY2021_Tx" SG_ 1143 ChrgCompltMsgTxt_D_Rq 1;
BA_ "ECGUsedRxSignal" SG_ 1142 ConsTipV_No_Dsply 1;
BA_ "U_CD542_MY2021_Rx" SG_ 1142 ConsTipV_No_Dsply 1;
BA_ "U_U55X_MY2022_Rx" SG_ 1142 ConsTipV_No_Dsply 1;
BA_ "U_CX727_MY2021_Tx" SG_ 1142 ConsTipV_No_Dsply 1;
BA_ "U_CD542_MY2021_Tx" SG_ 1142 ConsTipV_No_Dsply 1;
BA_ "U_CDX706_MY2023_Tx" SG_ 1142 ConsTipV_No_Dsply 1;
BA_ "U_CX727_MY2021_Tx" SG_ 1142 ConsTipMsg3_D_Dsply 1;
BA_ "U_CD542_MY2021_Tx" SG_ 1142 ConsTipMsg3_D_Dsply 1;
BA_ "U_CDX706_MY2023_Tx" SG_ 1142 ConsTipMsg3_D_Dsply 1;
BA_ "U_CX727_MY2021_Tx" SG_ 1142 ConsTipMsg2_D_Dsply 1;
BA_ "U_CD542_MY2021_Tx" SG_ 1142 ConsTipMsg2_D_Dsply 1;
BA_ "U_CDX706_MY2023_Tx" SG_ 1142 ConsTipMsg2_D_Dsply 1;
BA_ "U_CX727_MY2021_Tx" SG_ 1142 ConsTipMsg1_D_Dsply 1;
BA_ "U_CD542_MY2021_Tx" SG_ 1142 ConsTipMsg1_D_Dsply 1;
BA_ "U_CDX706_MY2023_Tx" SG_ 1142 ConsTipMsg1_D_Dsply 1;
BA_ "ECGUsedRxSignal" SG_ 1142 ConsTipDecel_No_Dsply 1;
BA_ "U_CD542_MY2021_Rx" SG_ 1142 ConsTipDecel_No_Dsply 1;
BA_ "U_U55X_MY2022_Rx" SG_ 1142 ConsTipDecel_No_Dsply 1;
BA_ "U_CX727_MY2021_Tx" SG_ 1142 ConsTipDecel_No_Dsply 1;
BA_ "U_CD542_MY2021_Tx" SG_ 1142 ConsTipDecel_No_Dsply 1;
BA_ "U_CDX706_MY2023_Tx" SG_ 1142 ConsTipDecel_No_Dsply 1;
BA_ "ECGUsedRxSignal" SG_ 1142 ConsTipA_No_Dsply 1;
BA_ "U_CD542_MY2021_Rx" SG_ 1142 ConsTipA_No_Dsply 1;
BA_ "U_U55X_MY2022_Rx" SG_ 1142 ConsTipA_No_Dsply 1;
BA_ "U_CX727_MY2021_Tx" SG_ 1142 ConsTipA_No_Dsply 1;
BA_ "U_CD542_MY2021_Tx" SG_ 1142 ConsTipA_No_Dsply 1;
BA_ "U_CDX706_MY2023_Tx" SG_ 1142 ConsTipA_No_Dsply 1;
BA_ "GenSigStartValue" SG_ 1141 WhlPwFront_Pc_Dsply 511;
BA_ "GenSigStartValue" SG_ 1141 WhlPwRear_Pc_Dsply 511;
BA_ "U_CX727_MY2021_Tx" SG_ 1141 AirAmbTePlgIn_D_Dsply 1;
BA_ "U_CD542_MY2021_Tx" SG_ 1141 AirAmbTePlgIn_D_Dsply 1;
BA_ "ECGUsedRxSignal" SG_ 1141 OfbChrgSetSync_D_Stat 1;
BA_ "U_CD542_MY2021_Rx" SG_ 1141 OfbChrgSetSync_D_Stat 1;
BA_ "U_U55X_MY2022_Rx" SG_ 1141 OfbChrgSetSync_D_Stat 1;
BA_ "U_CX727_MY2021_Tx" SG_ 1141 OfbChrgSetSync_D_Stat 1;
BA_ "U_CD542_MY2021_Tx" SG_ 1141 OfbChrgSetSync_D_Stat 1;
BA_ "GenSigStartValueInteger" SG_ 1141 MtrTrac2_Tq_Actl 4095;
BA_ "GenSigStartValue" SG_ 1141 MtrTrac2_Tq_Actl 4095;
BA_ "ECGUsedRxSignal" SG_ 1141 MtrTrac2_Tq_Actl 1;
BA_ "U_CD542_MY2021_Rx" SG_ 1141 MtrTrac2_Tq_Actl 1;
BA_ "U_U55X_MY2022_Rx" SG_ 1141 MtrTrac2_Tq_Actl 1;
BA_ "U_CX727_MY2021_Tx" SG_ 1141 MtrTrac2_Tq_Actl 1;
BA_ "U_P702_MY2021_Tx" SG_ 1141 MtrTrac2_Tq_Actl 1;
BA_ "U_CD542_MY2021_Tx" SG_ 1141 MtrTrac2_Tq_Actl 1;
BA_ "U_CDX706_MY2023_Tx" SG_ 1141 MtrTrac2_Tq_Actl 1;
BA_ "WakeupSignal" SG_ 1141 PtRmtRprt_D_Rq 1;
BA_ "ECGUsedRxSignal" SG_ 1141 PtRmtRprt_D_Rq 1;
BA_ "U_CD542_MY2021_Rx" SG_ 1141 PtRmtRprt_D_Rq 1;
BA_ "U_U55X_MY2022_Rx" SG_ 1141 PtRmtRprt_D_Rq 1;
BA_ "U_CX727_MY2021_Tx" SG_ 1141 PtRmtRprt_D_Rq 1;
BA_ "U_CD542_MY2021_Tx" SG_ 1141 PtRmtRprt_D_Rq 1;
BA_ "U_CX727_MY2021_Tx" SG_ 1141 PreCondID_No_Rq 1;
BA_ "U_CD542_MY2021_Tx" SG_ 1141 PreCondID_No_Rq 1;
BA_ "U_CX727_MY2021_Tx" SG_ 1141 NxtUsg_D_Rq 1;
BA_ "U_CD542_MY2021_Tx" SG_ 1141 NxtUsg_D_Rq 1;
BA_ "ECGUsedRxSignal" SG_ 1141 NtfctnConflict1_D_Rq 1;
BA_ "U_CD542_MY2021_Rx" SG_ 1141 NtfctnConflict1_D_Rq 1;
BA_ "U_U55X_MY2022_Rx" SG_ 1141 NtfctnConflict1_D_Rq 1;
BA_ "U_CX727_MY2021_Tx" SG_ 1141 NtfctnConflict1_D_Rq 1;
BA_ "U_P702_MY2021_Tx" SG_ 1141 NtfctnConflict1_D_Rq 1;
BA_ "U_CD542_MY2021_Tx" SG_ 1141 NtfctnConflict1_D_Rq 1;
BA_ "ECGUsedRxSignal" SG_ 1141 ChrgLocID_No_Rq 1;
BA_ "U_CD542_MY2021_Rx" SG_ 1141 ChrgLocID_No_Rq 1;
BA_ "U_U55X_MY2022_Rx" SG_ 1141 ChrgLocID_No_Rq 1;
BA_ "U_CX727_MY2021_Tx" SG_ 1141 ChrgLocID_No_Rq 1;
BA_ "U_CD542_MY2021_Tx" SG_ 1141 ChrgLocID_No_Rq 1;
BA_ "U_CX727_MY2021_Tx" SG_ 1141 ChrgLocGPS_D_Rq 1;
BA_ "U_CD542_MY2021_Tx" SG_ 1141 ChrgLocGPS_D_Rq 1;
BA_ "ECGUsedRxSignal" SG_ 1140 RgenLongTerm_L_Dsply 1;
BA_ "U_CD542_MY2021_Rx" SG_ 1140 RgenLongTerm_L_Dsply 1;
BA_ "U_U55X_MY2022_Rx" SG_ 1140 RgenLongTerm_L_Dsply 1;
BA_ "U_CX727_MY2021_Tx" SG_ 1140 RgenLongTerm_L_Dsply 1;
BA_ "U_CD542_MY2021_Tx" SG_ 1140 RgenLongTerm_L_Dsply 1;
BA_ "U_CDX706_MY2023_Tx" SG_ 1140 RgenLongTerm_L_Dsply 1;
BA_ "ECGUsedRxSignal" SG_ 1140 PreCondStat_D_Dsply 1;
BA_ "U_CD542_MY2021_Rx" SG_ 1140 PreCondStat_D_Dsply 1;
BA_ "U_U55X_MY2022_Rx" SG_ 1140 PreCondStat_D_Dsply 1;
BA_ "U_CX727_MY2021_Tx" SG_ 1140 PreCondStat_D_Dsply 1;
BA_ "U_P702_MY2021_Tx" SG_ 1140 PreCondStat_D_Dsply 1;
BA_ "U_CD542_MY2021_Tx" SG_ 1140 PreCondStat_D_Dsply 1;
BA_ "ECGUsedRxSignal" SG_ 1140 RgenLongTerm_Pc_Dsply 1;
BA_ "U_CD542_MY2021_Rx" SG_ 1140 RgenLongTerm_Pc_Dsply 1;
BA_ "U_U55X_MY2022_Rx" SG_ 1140 RgenLongTerm_Pc_Dsply 1;
BA_ "U_CX727_MY2021_Tx" SG_ 1140 RgenLongTerm_Pc_Dsply 1;
BA_ "U_CD542_MY2021_Tx" SG_ 1140 RgenLongTerm_Pc_Dsply 1;
BA_ "U_CDX706_MY2023_Tx" SG_ 1140 RgenLongTerm_Pc_Dsply 1;
BA_ "GenSigStartValueInteger" SG_ 1140 RgenEvntLvl_Pc_Dsply 1023;
BA_ "GenSigStartValue" SG_ 1140 RgenEvntLvl_Pc_Dsply 1022;
BA_ "U_CX727_MY2021_Tx" SG_ 1140 RgenEvntLvl_Pc_Dsply 1;
BA_ "U_CD542_MY2021_Tx" SG_ 1140 RgenEvntLvl_Pc_Dsply 1;
BA_ "U_CDX706_MY2023_Tx" SG_ 1140 RgenEvntLvl_Pc_Dsply 1;
BA_ "U_CX727_MY2021_Tx" SG_ 1140 BrkEvntComplt_B_Dsply 1;
BA_ "U_CD542_MY2021_Tx" SG_ 1140 BrkEvntComplt_B_Dsply 1;
BA_ "U_CDX706_MY2023_Tx" SG_ 1140 BrkEvntComplt_B_Dsply 1;
BA_ "U_CX727_MY2021_Tx" SG_ 1140 ExtChrgrFalt_B_Dsply 1;
BA_ "U_CD542_MY2021_Tx" SG_ 1140 ExtChrgrFalt_B_Dsply 1;
BA_ "U_CDX706_MY2023_Tx" SG_ 1140 BattTracPw_Pc_Avail 1;
BA_ "U_CX727_MY2021_Tx" SG_ 1139 BattChrgTrgtLMax_T_Est 1;
BA_ "U_P702_MY2021_Tx" SG_ 1139 BattChrgTrgtLMax_T_Est 1;
BA_ "U_CD542_MY2021_Tx" SG_ 1139 BattChrgTrgtLMax_T_Est 1;
BA_ "ECGUsedRxSignal" SG_ 1139 ActChrgStrtYr_No_Actl 1;
BA_ "U_CD542_MY2021_Rx" SG_ 1139 ActChrgStrtYr_No_Actl 1;
BA_ "U_U55X_MY2022_Rx" SG_ 1139 ActChrgStrtYr_No_Actl 1;
BA_ "U_CX727_MY2021_Tx" SG_ 1139 ActChrgStrtYr_No_Actl 1;
BA_ "U_P702_MY2021_Tx" SG_ 1139 ActChrgStrtYr_No_Actl 1;
BA_ "U_CD542_MY2021_Tx" SG_ 1139 ActChrgStrtYr_No_Actl 1;
BA_ "ECGUsedRxSignal" SG_ 1139 ActChrgStrtMin_No_Actl 1;
BA_ "U_CD542_MY2021_Rx" SG_ 1139 ActChrgStrtMin_No_Actl 1;
BA_ "U_U55X_MY2022_Rx" SG_ 1139 ActChrgStrtMin_No_Actl 1;
BA_ "U_CX727_MY2021_Tx" SG_ 1139 ActChrgStrtMin_No_Actl 1;
BA_ "U_P702_MY2021_Tx" SG_ 1139 ActChrgStrtMin_No_Actl 1;
BA_ "U_CD542_MY2021_Tx" SG_ 1139 ActChrgStrtMin_No_Actl 1;
BA_ "ECGUsedRxSignal" SG_ 1139 ActChrgStrtHr_No_Actl 1;
BA_ "U_CD542_MY2021_Rx" SG_ 1139 ActChrgStrtHr_No_Actl 1;
BA_ "U_U55X_MY2022_Rx" SG_ 1139 ActChrgStrtHr_No_Actl 1;
BA_ "U_CX727_MY2021_Tx" SG_ 1139 ActChrgStrtHr_No_Actl 1;
BA_ "U_P702_MY2021_Tx" SG_ 1139 ActChrgStrtHr_No_Actl 1;
BA_ "U_CD542_MY2021_Tx" SG_ 1139 ActChrgStrtHr_No_Actl 1;
BA_ "GenSigStartValueInteger" SG_ 1139 ActChrgStrtDay_No_Actl 1;
BA_ "GenSigStartValue" SG_ 1139 ActChrgStrtDay_No_Actl 1;
BA_ "ECGUsedRxSignal" SG_ 1139 ActChrgStrtDay_No_Actl 1;
BA_ "U_CD542_MY2021_Rx" SG_ 1139 ActChrgStrtDay_No_Actl 1;
BA_ "U_U55X_MY2022_Rx" SG_ 1139 ActChrgStrtDay_No_Actl 1;
BA_ "U_CX727_MY2021_Tx" SG_ 1139 ActChrgStrtDay_No_Actl 1;
BA_ "U_P702_MY2021_Tx" SG_ 1139 ActChrgStrtDay_No_Actl 1;
BA_ "U_CD542_MY2021_Tx" SG_ 1139 ActChrgStrtDay_No_Actl 1;
BA_ "GenSigStartValueInteger" SG_ 1139 ActChrgStrMnth_No_Actl 1;
BA_ "GenSigStartValue" SG_ 1139 ActChrgStrMnth_No_Actl 1;
BA_ "ECGUsedRxSignal" SG_ 1139 ActChrgStrMnth_No_Actl 1;
BA_ "U_CD542_MY2021_Rx" SG_ 1139 ActChrgStrMnth_No_Actl 1;
BA_ "U_U55X_MY2022_Rx" SG_ 1139 ActChrgStrMnth_No_Actl 1;
BA_ "U_CX727_MY2021_Tx" SG_ 1139 ActChrgStrMnth_No_Actl 1;
BA_ "U_P702_MY2021_Tx" SG_ 1139 ActChrgStrMnth_No_Actl 1;
BA_ "U_CD542_MY2021_Tx" SG_ 1139 ActChrgStrMnth_No_Actl 1;
BA_ "ECGUsedRxSignal" SG_ 1139 ActChrgStrtYr_No2_Actl 1;
BA_ "U_CD542_MY2021_Rx" SG_ 1139 ActChrgStrtYr_No2_Actl 1;
BA_ "U_U55X_MY2022_Rx" SG_ 1139 ActChrgStrtYr_No2_Actl 1;
BA_ "U_CX727_MY2021_Tx" SG_ 1139 ActChrgStrtYr_No2_Actl 1;
BA_ "U_CD542_MY2021_Tx" SG_ 1139 ActChrgStrtYr_No2_Actl 1;
BA_ "U_CX727_MY2021_Tx" SG_ 1138 BattChrgTrgtLMin_T_Est 1;
BA_ "U_P702_MY2021_Tx" SG_ 1138 BattChrgTrgtLMin_T_Est 1;
BA_ "U_CD542_MY2021_Tx" SG_ 1138 BattChrgTrgtLMin_T_Est 1;
BA_ "ECGUsedRxSignal" SG_ 1138 ActChrgEndYr_No_Actl 1;
BA_ "U_CD542_MY2021_Rx" SG_ 1138 ActChrgEndYr_No_Actl 1;
BA_ "U_U55X_MY2022_Rx" SG_ 1138 ActChrgEndYr_No_Actl 1;
BA_ "U_CX727_MY2021_Tx" SG_ 1138 ActChrgEndYr_No_Actl 1;
BA_ "U_P702_MY2021_Tx" SG_ 1138 ActChrgEndYr_No_Actl 1;
BA_ "U_CD542_MY2021_Tx" SG_ 1138 ActChrgEndYr_No_Actl 1;
BA_ "GenSigStartValueInteger" SG_ 1138 ActChrgEndMnth_No_Actl 1;
BA_ "GenSigStartValue" SG_ 1138 ActChrgEndMnth_No_Actl 1;
BA_ "ECGUsedRxSignal" SG_ 1138 ActChrgEndMnth_No_Actl 1;
BA_ "U_CD542_MY2021_Rx" SG_ 1138 ActChrgEndMnth_No_Actl 1;
BA_ "U_U55X_MY2022_Rx" SG_ 1138 ActChrgEndMnth_No_Actl 1;
BA_ "U_CX727_MY2021_Tx" SG_ 1138 ActChrgEndMnth_No_Actl 1;
BA_ "U_P702_MY2021_Tx" SG_ 1138 ActChrgEndMnth_No_Actl 1;
BA_ "U_CD542_MY2021_Tx" SG_ 1138 ActChrgEndMnth_No_Actl 1;
BA_ "ECGUsedRxSignal" SG_ 1138 ActChrgEndMin_No_Actl 1;
BA_ "U_CD542_MY2021_Rx" SG_ 1138 ActChrgEndMin_No_Actl 1;
BA_ "U_U55X_MY2022_Rx" SG_ 1138 ActChrgEndMin_No_Actl 1;
BA_ "U_CX727_MY2021_Tx" SG_ 1138 ActChrgEndMin_No_Actl 1;
BA_ "U_P702_MY2021_Tx" SG_ 1138 ActChrgEndMin_No_Actl 1;
BA_ "U_CD542_MY2021_Tx" SG_ 1138 ActChrgEndMin_No_Actl 1;
BA_ "ECGUsedRxSignal" SG_ 1138 ActChrgEndHr_No_Actl 1;
BA_ "U_CD542_MY2021_Rx" SG_ 1138 ActChrgEndHr_No_Actl 1;
BA_ "U_U55X_MY2022_Rx" SG_ 1138 ActChrgEndHr_No_Actl 1;
BA_ "U_CX727_MY2021_Tx" SG_ 1138 ActChrgEndHr_No_Actl 1;
BA_ "U_P702_MY2021_Tx" SG_ 1138 ActChrgEndHr_No_Actl 1;
BA_ "U_CD542_MY2021_Tx" SG_ 1138 ActChrgEndHr_No_Actl 1;
BA_ "GenSigStartValueInteger" SG_ 1138 ActChrgEndDay_No_Actl 1;
BA_ "GenSigStartValue" SG_ 1138 ActChrgEndDay_No_Actl 1;
BA_ "ECGUsedRxSignal" SG_ 1138 ActChrgEndDay_No_Actl 1;
BA_ "U_CD542_MY2021_Rx" SG_ 1138 ActChrgEndDay_No_Actl 1;
BA_ "U_U55X_MY2022_Rx" SG_ 1138 ActChrgEndDay_No_Actl 1;
BA_ "U_CX727_MY2021_Tx" SG_ 1138 ActChrgEndDay_No_Actl 1;
BA_ "U_P702_MY2021_Tx" SG_ 1138 ActChrgEndDay_No_Actl 1;
BA_ "U_CD542_MY2021_Tx" SG_ 1138 ActChrgEndDay_No_Actl 1;
BA_ "ECGUsedRxSignal" SG_ 1138 ActChrgEndYr_No2_Actl 1;
BA_ "U_CD542_MY2021_Rx" SG_ 1138 ActChrgEndYr_No2_Actl 1;
BA_ "U_U55X_MY2022_Rx" SG_ 1138 ActChrgEndYr_No2_Actl 1;
BA_ "U_CX727_MY2021_Tx" SG_ 1138 ActChrgEndYr_No2_Actl 1;
BA_ "U_CD542_MY2021_Tx" SG_ 1138 ActChrgEndYr_No2_Actl 1;
BA_ "GenSigSendType" SG_ 1016 ChrgGoTElement_B_Dsply 3;
BA_ "ECGUsedRxSignal" SG_ 1016 ChrgGoTElement_B_Dsply 1;
BA_ "U_CD542_MY2021_Rx" SG_ 1016 ChrgGoTElement_B_Dsply 1;
BA_ "U_U55X_MY2022_Rx" SG_ 1016 ChrgGoTElement_B_Dsply 1;
BA_ "U_CX727_MY2021_Tx" SG_ 1016 ChrgGoTElement_B_Dsply 1;
BA_ "U_CD542_MY2021_Tx" SG_ 1016 ChrgGoTElement_B_Dsply 1;
BA_ "GenSigSendType" SG_ 1016 ChrgLocIdCurnt_D_Uns 3;
BA_ "ECGUsedRxSignal" SG_ 1016 ChrgLocIdCurnt_D_Uns 1;
BA_ "U_CD542_MY2021_Rx" SG_ 1016 ChrgLocIdCurnt_D_Uns 1;
BA_ "U_U55X_MY2022_Rx" SG_ 1016 ChrgLocIdCurnt_D_Uns 1;
BA_ "U_CX727_MY2021_Tx" SG_ 1016 ChrgLocIdCurnt_D_Uns 1;
BA_ "U_P702_MY2021_Tx" SG_ 1016 ChrgLocIdCurnt_D_Uns 1;
BA_ "U_CD542_MY2021_Tx" SG_ 1016 ChrgLocIdCurnt_D_Uns 1;
BA_ "GenSigSendType" SG_ 1016 ChrgGoTTouchEnbl_B_Rq 3;
BA_ "U_CX727_MY2021_Tx" SG_ 1016 ChrgGoTTouchEnbl_B_Rq 1;
BA_ "U_P702_MY2021_Tx" SG_ 1016 ChrgGoTTouchEnbl_B_Rq 1;
BA_ "U_CD542_MY2021_Tx" SG_ 1016 ChrgGoTTouchEnbl_B_Rq 1;
BA_ "GenSigSendType" SG_ 1016 ChrgGoTTouch_B_Stat 3;
BA_ "ECGUsedRxSignal" SG_ 1016 ChrgGoTTouch_B_Stat 1;
BA_ "U_CD542_MY2021_Rx" SG_ 1016 ChrgGoTTouch_B_Stat 1;
BA_ "U_U55X_MY2022_Rx" SG_ 1016 ChrgGoTTouch_B_Stat 1;
BA_ "U_CX727_MY2021_Tx" SG_ 1016 ChrgGoTTouch_B_Stat 1;
BA_ "U_P702_MY2021_Tx" SG_ 1016 ChrgGoTTouch_B_Stat 1;
BA_ "U_CD542_MY2021_Tx" SG_ 1016 ChrgGoTTouch_B_Stat 1;
BA_ "ECGUsedRxSignal" SG_ 1016 ChrgGoTPrcond_D_Stat 1;
BA_ "U_CD542_MY2021_Rx" SG_ 1016 ChrgGoTPrcond_D_Stat 1;
BA_ "U_U55X_MY2022_Rx" SG_ 1016 ChrgGoTPrcond_D_Stat 1;
BA_ "U_CX727_MY2021_Tx" SG_ 1016 ChrgGoTPrcond_D_Stat 1;
BA_ "U_P702_MY2021_Tx" SG_ 1016 ChrgGoTPrcond_D_Stat 1;
BA_ "U_CD542_MY2021_Tx" SG_ 1016 ChrgGoTPrcond_D_Stat 1;
BA_ "GenSigSendType" SG_ 1016 ChrgGoTNext_D_Stat 3;
BA_ "ECGUsedRxSignal" SG_ 1016 ChrgGoTNext_D_Stat 1;
BA_ "U_CD542_MY2021_Rx" SG_ 1016 ChrgGoTNext_D_Stat 1;
BA_ "U_U55X_MY2022_Rx" SG_ 1016 ChrgGoTNext_D_Stat 1;
BA_ "U_CX727_MY2021_Tx" SG_ 1016 ChrgGoTNext_D_Stat 1;
BA_ "U_P702_MY2021_Tx" SG_ 1016 ChrgGoTNext_D_Stat 1;
BA_ "U_CD542_MY2021_Tx" SG_ 1016 ChrgGoTNext_D_Stat 1;
BA_ "ECGUsedRxSignal" SG_ 1016 ChrgGoTMnte_D_Stat 1;
BA_ "U_CD542_MY2021_Rx" SG_ 1016 ChrgGoTMnte_D_Stat 1;
BA_ "U_U55X_MY2022_Rx" SG_ 1016 ChrgGoTMnte_D_Stat 1;
BA_ "U_CX727_MY2021_Tx" SG_ 1016 ChrgGoTMnte_D_Stat 1;
BA_ "U_P702_MY2021_Tx" SG_ 1016 ChrgGoTMnte_D_Stat 1;
BA_ "U_CD542_MY2021_Tx" SG_ 1016 ChrgGoTMnte_D_Stat 1;
BA_ "GenSigStartValueInteger" SG_ 1016 ChrgGoTHr_T_Stat 30;
BA_ "GenSigStartValue" SG_ 1016 ChrgGoTHr_T_Stat 30;
BA_ "ECGUsedRxSignal" SG_ 1016 ChrgGoTHr_T_Stat 1;
BA_ "U_CD542_MY2021_Rx" SG_ 1016 ChrgGoTHr_T_Stat 1;
BA_ "U_U55X_MY2022_Rx" SG_ 1016 ChrgGoTHr_T_Stat 1;
BA_ "U_CX727_MY2021_Tx" SG_ 1016 ChrgGoTHr_T_Stat 1;
BA_ "U_P702_MY2021_Tx" SG_ 1016 ChrgGoTHr_T_Stat 1;
BA_ "U_CD542_MY2021_Tx" SG_ 1016 ChrgGoTHr_T_Stat 1;
BA_ "GenSigSendType" SG_ 1016 ChrgGoTExtHtrEnbl_B_Rq 3;
BA_ "U_CX727_MY2021_Tx" SG_ 1016 ChrgGoTExtHtrEnbl_B_Rq 1;
BA_ "U_P702_MY2021_Tx" SG_ 1016 ChrgGoTExtHtrEnbl_B_Rq 1;
BA_ "U_CD542_MY2021_Tx" SG_ 1016 ChrgGoTExtHtrEnbl_B_Rq 1;
BA_ "GenSigSendType" SG_ 1016 ChrgGoTExtHtr_B_Stat 3;
BA_ "ECGUsedRxSignal" SG_ 1016 ChrgGoTExtHtr_B_Stat 1;
BA_ "U_CD542_MY2021_Rx" SG_ 1016 ChrgGoTExtHtr_B_Stat 1;
BA_ "U_U55X_MY2022_Rx" SG_ 1016 ChrgGoTExtHtr_B_Stat 1;
BA_ "U_CX727_MY2021_Tx" SG_ 1016 ChrgGoTExtHtr_B_Stat 1;
BA_ "U_P702_MY2021_Tx" SG_ 1016 ChrgGoTExtHtr_B_Stat 1;
BA_ "U_CD542_MY2021_Tx" SG_ 1016 ChrgGoTExtHtr_B_Stat 1;
BA_ "GenSigSendType" SG_ 1016 ChrgGoTElement_D_Stat 3;
BA_ "ECGUsedRxSignal" SG_ 1016 ChrgGoTElement_D_Stat 1;
BA_ "U_CD542_MY2021_Rx" SG_ 1016 ChrgGoTElement_D_Stat 1;
BA_ "U_U55X_MY2022_Rx" SG_ 1016 ChrgGoTElement_D_Stat 1;
BA_ "U_CX727_MY2021_Tx" SG_ 1016 ChrgGoTElement_D_Stat 1;
BA_ "U_P702_MY2021_Tx" SG_ 1016 ChrgGoTElement_D_Stat 1;
BA_ "U_CD542_MY2021_Tx" SG_ 1016 ChrgGoTElement_D_Stat 1;
BA_ "GenSigSendType" SG_ 1016 ChrgGoTAllOn_B_Stat 3;
BA_ "ECGUsedRxSignal" SG_ 1016 ChrgGoTAllOn_B_Stat 1;
BA_ "U_CD542_MY2021_Rx" SG_ 1016 ChrgGoTAllOn_B_Stat 1;
BA_ "U_U55X_MY2022_Rx" SG_ 1016 ChrgGoTAllOn_B_Stat 1;
BA_ "U_CX727_MY2021_Tx" SG_ 1016 ChrgGoTAllOn_B_Stat 1;
BA_ "U_P702_MY2021_Tx" SG_ 1016 ChrgGoTAllOn_B_Stat 1;
BA_ "U_CD542_MY2021_Tx" SG_ 1016 ChrgGoTAllOn_B_Stat 1;
BA_ "ECGUsedRxSignal" SG_ 1013 ChrgToPcWkndSav_D_Stat 1;
BA_ "U_CD542_MY2021_Rx" SG_ 1013 ChrgToPcWkndSav_D_Stat 1;
BA_ "U_U55X_MY2022_Rx" SG_ 1013 ChrgToPcWkndSav_D_Stat 1;
BA_ "U_CX727_MY2021_Tx" SG_ 1013 ChrgToPcWkndSav_D_Stat 1;
BA_ "U_P702_MY2021_Tx" SG_ 1013 ChrgToPcWkndSav_D_Stat 1;
BA_ "U_CD542_MY2021_Tx" SG_ 1013 ChrgToPcWkndSav_D_Stat 1;
BA_ "ECGUsedRxSignal" SG_ 1013 ChrgToPcWkdySav_D_Stat 1;
BA_ "U_CD542_MY2021_Rx" SG_ 1013 ChrgToPcWkdySav_D_Stat 1;
BA_ "U_U55X_MY2022_Rx" SG_ 1013 ChrgToPcWkdySav_D_Stat 1;
BA_ "U_CX727_MY2021_Tx" SG_ 1013 ChrgToPcWkdySav_D_Stat 1;
BA_ "U_P702_MY2021_Tx" SG_ 1013 ChrgToPcWkdySav_D_Stat 1;
BA_ "U_CD542_MY2021_Tx" SG_ 1013 ChrgToPcWkdySav_D_Stat 1;
BA_ "GenSigSendType" SG_ 1013 ChrgProgIdSaved_D_Stat 3;
BA_ "ECGUsedRxSignal" SG_ 1013 ChrgProgIdSaved_D_Stat 1;
BA_ "U_CD542_MY2021_Rx" SG_ 1013 ChrgProgIdSaved_D_Stat 1;
BA_ "U_U55X_MY2022_Rx" SG_ 1013 ChrgProgIdSaved_D_Stat 1;
BA_ "U_CX727_MY2021_Tx" SG_ 1013 ChrgProgIdSaved_D_Stat 1;
BA_ "U_P702_MY2021_Tx" SG_ 1013 ChrgProgIdSaved_D_Stat 1;
BA_ "U_CD542_MY2021_Tx" SG_ 1013 ChrgProgIdSaved_D_Stat 1;
BA_ "ECGUsedRxSignal" SG_ 1013 ChrgNowEnbl_B_Saved 1;
BA_ "U_CD542_MY2021_Rx" SG_ 1013 ChrgNowEnbl_B_Saved 1;
BA_ "U_U55X_MY2022_Rx" SG_ 1013 ChrgNowEnbl_B_Saved 1;
BA_ "U_CX727_MY2021_Tx" SG_ 1013 ChrgNowEnbl_B_Saved 1;
BA_ "U_P702_MY2021_Tx" SG_ 1013 ChrgNowEnbl_B_Saved 1;
BA_ "U_CD542_MY2021_Tx" SG_ 1013 ChrgNowEnbl_B_Saved 1;
BA_ "GenSigSendType" SG_ 1013 ChrgLocIdUnsAck_B_Stat 3;
BA_ "ECGUsedRxSignal" SG_ 1013 ChrgLocIdUnsAck_B_Stat 1;
BA_ "U_CD542_MY2021_Rx" SG_ 1013 ChrgLocIdUnsAck_B_Stat 1;
BA_ "U_U55X_MY2022_Rx" SG_ 1013 ChrgLocIdUnsAck_B_Stat 1;
BA_ "U_CX727_MY2021_Tx" SG_ 1013 ChrgLocIdUnsAck_B_Stat 1;
BA_ "U_P702_MY2021_Tx" SG_ 1013 ChrgLocIdUnsAck_B_Stat 1;
BA_ "U_CD542_MY2021_Tx" SG_ 1013 ChrgLocIdUnsAck_B_Stat 1;
BA_ "GenSigSendType" SG_ 1013 ChrgLocIdCurnt_D_Sav 3;
BA_ "ECGUsedRxSignal" SG_ 1013 ChrgLocIdCurnt_D_Sav 1;
BA_ "U_CD542_MY2021_Rx" SG_ 1013 ChrgLocIdCurnt_D_Sav 1;
BA_ "U_U55X_MY2022_Rx" SG_ 1013 ChrgLocIdCurnt_D_Sav 1;
BA_ "U_CX727_MY2021_Tx" SG_ 1013 ChrgLocIdCurnt_D_Sav 1;
BA_ "U_P702_MY2021_Tx" SG_ 1013 ChrgLocIdCurnt_D_Sav 1;
BA_ "U_CD542_MY2021_Tx" SG_ 1013 ChrgLocIdCurnt_D_Sav 1;
BA_ "ECGUsedRxSignal" SG_ 1013 ChrgPrflWknd_No_Actl 1;
BA_ "U_CD542_MY2021_Rx" SG_ 1013 ChrgPrflWknd_No_Actl 1;
BA_ "U_U55X_MY2022_Rx" SG_ 1013 ChrgPrflWknd_No_Actl 1;
BA_ "U_CX727_MY2021_Tx" SG_ 1013 ChrgPrflWknd_No_Actl 1;
BA_ "U_P702_MY2021_Tx" SG_ 1013 ChrgPrflWknd_No_Actl 1;
BA_ "U_CD542_MY2021_Tx" SG_ 1013 ChrgPrflWknd_No_Actl 1;
BA_ "ECGUsedRxSignal" SG_ 1013 ChrgPrflWkdy_No_Actl 1;
BA_ "U_CD542_MY2021_Rx" SG_ 1013 ChrgPrflWkdy_No_Actl 1;
BA_ "U_U55X_MY2022_Rx" SG_ 1013 ChrgPrflWkdy_No_Actl 1;
BA_ "U_CX727_MY2021_Tx" SG_ 1013 ChrgPrflWkdy_No_Actl 1;
BA_ "U_P702_MY2021_Tx" SG_ 1013 ChrgPrflWkdy_No_Actl 1;
BA_ "U_CD542_MY2021_Tx" SG_ 1013 ChrgPrflWkdy_No_Actl 1;
BA_ "GenSigSendType" SG_ 1012 AirCondRec_B_RqVehEl 3;
BA_ "U_CDX706_MY2023_Tx" SG_ 1012 AirCondRec_B_RqVehEl 1;
BA_ "GenSigSendType" SG_ 1012 ChrgLocSaved_B_Dsply 3;
BA_ "ECGUsedRxSignal" SG_ 1012 ChrgLocSaved_B_Dsply 1;
BA_ "U_CD542_MY2021_Rx" SG_ 1012 ChrgLocSaved_B_Dsply 1;
BA_ "U_U55X_MY2022_Rx" SG_ 1012 ChrgLocSaved_B_Dsply 1;
BA_ "U_CX727_MY2021_Tx" SG_ 1012 ChrgLocSaved_B_Dsply 1;
BA_ "U_P702_MY2021_Tx" SG_ 1012 ChrgLocSaved_B_Dsply 1;
BA_ "U_CD542_MY2021_Tx" SG_ 1012 ChrgLocSaved_B_Dsply 1;
BA_ "ECGUsedRxSignal" SG_ 1012 ChrgLocLongPostv_B_Sav 1;
BA_ "U_CD542_MY2021_Rx" SG_ 1012 ChrgLocLongPostv_B_Sav 1;
BA_ "U_U55X_MY2022_Rx" SG_ 1012 ChrgLocLongPostv_B_Sav 1;
BA_ "U_CX727_MY2021_Tx" SG_ 1012 ChrgLocLongPostv_B_Sav 1;
BA_ "U_P702_MY2021_Tx" SG_ 1012 ChrgLocLongPostv_B_Sav 1;
BA_ "U_CD542_MY2021_Tx" SG_ 1012 ChrgLocLongPostv_B_Sav 1;
BA_ "GenSigStartValueInteger" SG_ 1012 ChrgLocLongFrct_An_Sav 1048575;
BA_ "GenSigStartValue" SG_ 1012 ChrgLocLongFrct_An_Sav 1048575;
BA_ "ECGUsedRxSignal" SG_ 1012 ChrgLocLongFrct_An_Sav 1;
BA_ "U_CD542_MY2021_Rx" SG_ 1012 ChrgLocLongFrct_An_Sav 1;
BA_ "U_U55X_MY2022_Rx" SG_ 1012 ChrgLocLongFrct_An_Sav 1;
BA_ "U_CX727_MY2021_Tx" SG_ 1012 ChrgLocLongFrct_An_Sav 1;
BA_ "U_P702_MY2021_Tx" SG_ 1012 ChrgLocLongFrct_An_Sav 1;
BA_ "U_CD542_MY2021_Tx" SG_ 1012 ChrgLocLongFrct_An_Sav 1;
BA_ "ECGUsedRxSignal" SG_ 1012 ChrgLocLongDeg_An_Sav 1;
BA_ "U_CD542_MY2021_Rx" SG_ 1012 ChrgLocLongDeg_An_Sav 1;
BA_ "U_U55X_MY2022_Rx" SG_ 1012 ChrgLocLongDeg_An_Sav 1;
BA_ "U_CX727_MY2021_Tx" SG_ 1012 ChrgLocLongDeg_An_Sav 1;
BA_ "U_P702_MY2021_Tx" SG_ 1012 ChrgLocLongDeg_An_Sav 1;
BA_ "U_CD542_MY2021_Tx" SG_ 1012 ChrgLocLongDeg_An_Sav 1;
BA_ "ECGUsedRxSignal" SG_ 1012 ChrgLocLattPostv_B_Sav 1;
BA_ "U_CD542_MY2021_Rx" SG_ 1012 ChrgLocLattPostv_B_Sav 1;
BA_ "U_U55X_MY2022_Rx" SG_ 1012 ChrgLocLattPostv_B_Sav 1;
BA_ "U_CX727_MY2021_Tx" SG_ 1012 ChrgLocLattPostv_B_Sav 1;
BA_ "U_P702_MY2021_Tx" SG_ 1012 ChrgLocLattPostv_B_Sav 1;
BA_ "U_CD542_MY2021_Tx" SG_ 1012 ChrgLocLattPostv_B_Sav 1;
BA_ "GenSigStartValueInteger" SG_ 1012 ChrgLocLattFrct_An_Sav 1048575;
BA_ "GenSigStartValue" SG_ 1012 ChrgLocLattFrct_An_Sav 1048575;
BA_ "ECGUsedRxSignal" SG_ 1012 ChrgLocLattFrct_An_Sav 1;
BA_ "U_CD542_MY2021_Rx" SG_ 1012 ChrgLocLattFrct_An_Sav 1;
BA_ "U_U55X_MY2022_Rx" SG_ 1012 ChrgLocLattFrct_An_Sav 1;
BA_ "U_CX727_MY2021_Tx" SG_ 1012 ChrgLocLattFrct_An_Sav 1;
BA_ "U_P702_MY2021_Tx" SG_ 1012 ChrgLocLattFrct_An_Sav 1;
BA_ "U_CD542_MY2021_Tx" SG_ 1012 ChrgLocLattFrct_An_Sav 1;
BA_ "ECGUsedRxSignal" SG_ 1012 ChrgLocLattDeg_An_Sav 1;
BA_ "U_CD542_MY2021_Rx" SG_ 1012 ChrgLocLattDeg_An_Sav 1;
BA_ "U_U55X_MY2022_Rx" SG_ 1012 ChrgLocLattDeg_An_Sav 1;
BA_ "U_CX727_MY2021_Tx" SG_ 1012 ChrgLocLattDeg_An_Sav 1;
BA_ "U_P702_MY2021_Tx" SG_ 1012 ChrgLocLattDeg_An_Sav 1;
BA_ "U_CD542_MY2021_Tx" SG_ 1012 ChrgLocLattDeg_An_Sav 1;
BA_ "GenSigSendType" SG_ 1012 ChrgLocId_D_Sav 3;
BA_ "ECGUsedRxSignal" SG_ 1012 ChrgLocId_D_Sav 1;
BA_ "U_CD542_MY2021_Rx" SG_ 1012 ChrgLocId_D_Sav 1;
BA_ "U_U55X_MY2022_Rx" SG_ 1012 ChrgLocId_D_Sav 1;
BA_ "U_CX727_MY2021_Tx" SG_ 1012 ChrgLocId_D_Sav 1;
BA_ "U_P702_MY2021_Tx" SG_ 1012 ChrgLocId_D_Sav 1;
BA_ "U_CD542_MY2021_Tx" SG_ 1012 ChrgLocId_D_Sav 1;
BA_ "GenSigSendType" SG_ 1012 ChrgNowCurnt_B_Dsply 3;
BA_ "ECGUsedRxSignal" SG_ 1012 ChrgNowCurnt_B_Dsply 1;
BA_ "U_CD542_MY2021_Rx" SG_ 1012 ChrgNowCurnt_B_Dsply 1;
BA_ "U_U55X_MY2022_Rx" SG_ 1012 ChrgNowCurnt_B_Dsply 1;
BA_ "U_CX727_MY2021_Tx" SG_ 1012 ChrgNowCurnt_B_Dsply 1;
BA_ "U_P702_MY2021_Tx" SG_ 1012 ChrgNowCurnt_B_Dsply 1;
BA_ "U_CD542_MY2021_Tx" SG_ 1012 ChrgNowCurnt_B_Dsply 1;
BA_ "GenSigSendType" SG_ 1011 VehShutDownMsgTxt_D_Rq 3;
BA_ "U_CDX706_MY2023_Tx" SG_ 1011 VehShutDownMsgTxt_D_Rq 1;
BA_ "ECGUsedRxSignal" SG_ 1011 ChrgLocLongPostv_B_Uns 1;
BA_ "U_CD542_MY2021_Rx" SG_ 1011 ChrgLocLongPostv_B_Uns 1;
BA_ "U_U55X_MY2022_Rx" SG_ 1011 ChrgLocLongPostv_B_Uns 1;
BA_ "U_CX727_MY2021_Tx" SG_ 1011 ChrgLocLongPostv_B_Uns 1;
BA_ "U_P702_MY2021_Tx" SG_ 1011 ChrgLocLongPostv_B_Uns 1;
BA_ "U_CD542_MY2021_Tx" SG_ 1011 ChrgLocLongPostv_B_Uns 1;
BA_ "GenSigStartValueInteger" SG_ 1011 ChrgLocLongFrct_An_Uns 1048575;
BA_ "GenSigStartValue" SG_ 1011 ChrgLocLongFrct_An_Uns 1048575;
BA_ "ECGUsedRxSignal" SG_ 1011 ChrgLocLongFrct_An_Uns 1;
BA_ "U_CD542_MY2021_Rx" SG_ 1011 ChrgLocLongFrct_An_Uns 1;
BA_ "U_U55X_MY2022_Rx" SG_ 1011 ChrgLocLongFrct_An_Uns 1;
BA_ "U_CX727_MY2021_Tx" SG_ 1011 ChrgLocLongFrct_An_Uns 1;
BA_ "U_P702_MY2021_Tx" SG_ 1011 ChrgLocLongFrct_An_Uns 1;
BA_ "U_CD542_MY2021_Tx" SG_ 1011 ChrgLocLongFrct_An_Uns 1;
BA_ "ECGUsedRxSignal" SG_ 1011 ChrgLocLongDeg_An_Uns 1;
BA_ "U_CD542_MY2021_Rx" SG_ 1011 ChrgLocLongDeg_An_Uns 1;
BA_ "U_U55X_MY2022_Rx" SG_ 1011 ChrgLocLongDeg_An_Uns 1;
BA_ "U_CX727_MY2021_Tx" SG_ 1011 ChrgLocLongDeg_An_Uns 1;
BA_ "U_P702_MY2021_Tx" SG_ 1011 ChrgLocLongDeg_An_Uns 1;
BA_ "U_CD542_MY2021_Tx" SG_ 1011 ChrgLocLongDeg_An_Uns 1;
BA_ "ECGUsedRxSignal" SG_ 1011 ChrgLocLattPostv_B_Uns 1;
BA_ "U_CD542_MY2021_Rx" SG_ 1011 ChrgLocLattPostv_B_Uns 1;
BA_ "U_U55X_MY2022_Rx" SG_ 1011 ChrgLocLattPostv_B_Uns 1;
BA_ "U_CX727_MY2021_Tx" SG_ 1011 ChrgLocLattPostv_B_Uns 1;
BA_ "U_P702_MY2021_Tx" SG_ 1011 ChrgLocLattPostv_B_Uns 1;
BA_ "U_CD542_MY2021_Tx" SG_ 1011 ChrgLocLattPostv_B_Uns 1;
BA_ "GenSigStartValueInteger" SG_ 1011 ChrgLocLattFrct_An_Uns 1048575;
BA_ "GenSigStartValue" SG_ 1011 ChrgLocLattFrct_An_Uns 1048575;
BA_ "ECGUsedRxSignal" SG_ 1011 ChrgLocLattFrct_An_Uns 1;
BA_ "U_CD542_MY2021_Rx" SG_ 1011 ChrgLocLattFrct_An_Uns 1;
BA_ "U_U55X_MY2022_Rx" SG_ 1011 ChrgLocLattFrct_An_Uns 1;
BA_ "U_CX727_MY2021_Tx" SG_ 1011 ChrgLocLattFrct_An_Uns 1;
BA_ "U_P702_MY2021_Tx" SG_ 1011 ChrgLocLattFrct_An_Uns 1;
BA_ "U_CD542_MY2021_Tx" SG_ 1011 ChrgLocLattFrct_An_Uns 1;
BA_ "ECGUsedRxSignal" SG_ 1011 ChrgLocLattDeg_An_Uns 1;
BA_ "U_CD542_MY2021_Rx" SG_ 1011 ChrgLocLattDeg_An_Uns 1;
BA_ "U_U55X_MY2022_Rx" SG_ 1011 ChrgLocLattDeg_An_Uns 1;
BA_ "U_CX727_MY2021_Tx" SG_ 1011 ChrgLocLattDeg_An_Uns 1;
BA_ "U_P702_MY2021_Tx" SG_ 1011 ChrgLocLattDeg_An_Uns 1;
BA_ "U_CD542_MY2021_Tx" SG_ 1011 ChrgLocLattDeg_An_Uns 1;
BA_ "GenSigSendType" SG_ 1011 ChrgLocId_D_Uns 3;
BA_ "ECGUsedRxSignal" SG_ 1011 ChrgLocId_D_Uns 1;
BA_ "U_CD542_MY2021_Rx" SG_ 1011 ChrgLocId_D_Uns 1;
BA_ "U_U55X_MY2022_Rx" SG_ 1011 ChrgLocId_D_Uns 1;
BA_ "U_CX727_MY2021_Tx" SG_ 1011 ChrgLocId_D_Uns 1;
BA_ "U_P702_MY2021_Tx" SG_ 1011 ChrgLocId_D_Uns 1;
BA_ "U_CD542_MY2021_Tx" SG_ 1011 ChrgLocId_D_Uns 1;
BA_ "GenSigStartValue" SG_ 1049 ExtLghtAnmtn_D_Rq 1;
BA_ "U_CDX706_MY2023_Rx" SG_ 1049 LnchCtl_N_Rq2 1;
BA_ "U_CDX706_MY2023_Rx" SG_ 1049 LnchCtl_D_Rq2 1;
BA_ "U_CDX706_MY2023_Rx" SG_ 1049 PersTurnSglView_D_RqMnu 1;
BA_ "GenSigStartValueInteger" SG_ 1049 FrontDiffLck_D_RqDrv3 2;
BA_ "GenSigStartValue" SG_ 1049 FrontDiffLck_D_RqDrv3 2;
BA_ "GenSigStartValueInteger" SG_ 1049 RearDiffLck_D_RqDrv3 2;
BA_ "GenSigStartValue" SG_ 1049 RearDiffLck_D_RqDrv3 2;
BA_ "U_CD764_MY2022_Rx" SG_ 1049 CamraFrnt_B_RqMnu 1;
BA_ "U_CDX706_MY2023_Rx" SG_ 1049 CamraFrnt_B_RqMnu 1;
BA_ "U_T6_MCA_MY2020_Rx" SG_ 1049 SelDrvMdeTxtRst_B_Rq2 1;
BA_ "U_CD542_MY2021_Rx" SG_ 1049 SelDrvMdeTxtRst_B_Rq2 1;
BA_ "U_CD764_MY2022_Rx" SG_ 1049 SelDrvMdeTxtRst_B_Rq2 1;
BA_ "U_CDX706_MY2023_Rx" SG_ 1049 SelDrvMdeTxtRst_B_Rq2 1;
BA_ "U_T6_MCA_MY2020_Rx" SG_ 1049 SelDrvMdePage_B_Stat 1;
BA_ "U_CD542_MY2021_Rx" SG_ 1049 SelDrvMdePage_B_Stat 1;
BA_ "U_CD764_MY2022_Rx" SG_ 1049 SelDrvMdePage_B_Stat 1;
BA_ "U_CDX706_MY2023_Rx" SG_ 1049 SelDrvMdePage_B_Stat 1;
BA_ "U_T6_MCA_MY2020_Rx" SG_ 1049 SelDrvMdeCnfm_D_Stat2 1;
BA_ "U_CD542_MY2021_Rx" SG_ 1049 SelDrvMdeCnfm_D_Stat2 1;
BA_ "U_CD764_MY2022_Rx" SG_ 1049 SelDrvMdeCnfm_D_Stat2 1;
BA_ "U_CDX706_MY2023_Rx" SG_ 1049 SelDrvMdeCnfm_D_Stat2 1;
BA_ "GenSigStartValue" SG_ 1049 SelDrvMde_D_RqDrv 31;
BA_ "U_T6_MCA_MY2020_Rx" SG_ 1049 SelDrvMde_D_RqDrv 1;
BA_ "U_CD542_MY2021_Rx" SG_ 1049 SelDrvMde_D_RqDrv 1;
BA_ "U_CD764_MY2022_Rx" SG_ 1049 SelDrvMde_D_RqDrv 1;
BA_ "U_CDX706_MY2023_Rx" SG_ 1049 SelDrvMde_D_RqDrv 1;
BA_ "GenSigSendType" SG_ 2611175457 PARSEDPhysIPMAtoGWM_ECG 3;
BA_ "U_T6_MCA_MY2020_Rx" SG_ 2611175457 PARSEDPhysIPMAtoGWM_ECG 1;
BA_ "ECGUsedRxSignal" SG_ 2611175457 PARSEDPhysIPMAtoGWM_ECG 1;
BA_ "U_CD542_MY2021_Rx" SG_ 2611175457 PARSEDPhysIPMAtoGWM_ECG 1;
BA_ "U_U55X_MY2022_Rx" SG_ 2611175457 PARSEDPhysIPMAtoGWM_ECG 1;
BA_ "U_CD764_MY2022_Rx" SG_ 2611175457 PARSEDPhysIPMAtoGWM_ECG 1;
BA_ "U_CDX706_MY2023_Rx" SG_ 2611175457 PARSEDPhysIPMAtoGWM_ECG 1;
BA_ "U_T6_MCA_MY2020_Tx" SG_ 2611175457 PARSEDPhysIPMAtoGWM_ECG 1;
BA_ "U_CD542_MY2021_Tx" SG_ 2611175457 PARSEDPhysIPMAtoGWM_ECG 1;
BA_ "U_U55X_MY2022_Tx" SG_ 2611175457 PARSEDPhysIPMAtoGWM_ECG 1;
BA_ "U_CD764_MY2022_Tx" SG_ 2611175457 PARSEDPhysIPMAtoGWM_ECG 1;
BA_ "U_CDX706_MY2023_Tx" SG_ 2611175457 PARSEDPhysIPMAtoGWM_ECG 1;
BA_ "GenSigSendType" SG_ 2609946840 OTAPhysGWM_ECGtoABS 3;
BA_ "U_T6_MCA_MY2020_Rx" SG_ 2609946840 OTAPhysGWM_ECGtoABS 1;
BA_ "U_CD542_MY2021_Rx" SG_ 2609946840 OTAPhysGWM_ECGtoABS 1;
BA_ "U_U55X_MY2022_Rx" SG_ 2609946840 OTAPhysGWM_ECGtoABS 1;
BA_ "U_CD764_MY2022_Rx" SG_ 2609946840 OTAPhysGWM_ECGtoABS 1;
BA_ "U_CDX706_MY2023_Rx" SG_ 2609946840 OTAPhysGWM_ECGtoABS 1;
BA_ "U_T6_MCA_MY2020_Tx" SG_ 2609946840 OTAPhysGWM_ECGtoABS 1;
BA_ "ECGUsedTxSignal" SG_ 2609946840 OTAPhysGWM_ECGtoABS 1;
BA_ "U_CD542_MY2021_Tx" SG_ 2609946840 OTAPhysGWM_ECGtoABS 1;
BA_ "U_U55X_MY2022_Tx" SG_ 2609946840 OTAPhysGWM_ECGtoABS 1;
BA_ "U_CD764_MY2022_Tx" SG_ 2609946840 OTAPhysGWM_ECGtoABS 1;
BA_ "U_CDX706_MY2023_Tx" SG_ 2609946840 OTAPhysGWM_ECGtoABS 1;
BA_ "GenSigSendType" SG_ 2610126888 OTAPhysABStoGWM_ECG 3;
BA_ "U_T6_MCA_MY2020_Rx" SG_ 2610126888 OTAPhysABStoGWM_ECG 1;
BA_ "ECGUsedRxSignal" SG_ 2610126888 OTAPhysABStoGWM_ECG 1;
BA_ "U_CD542_MY2021_Rx" SG_ 2610126888 OTAPhysABStoGWM_ECG 1;
BA_ "U_U55X_MY2022_Rx" SG_ 2610126888 OTAPhysABStoGWM_ECG 1;
BA_ "U_CD764_MY2022_Rx" SG_ 2610126888 OTAPhysABStoGWM_ECG 1;
BA_ "U_CDX706_MY2023_Rx" SG_ 2610126888 OTAPhysABStoGWM_ECG 1;
BA_ "U_T6_MCA_MY2020_Tx" SG_ 2610126888 OTAPhysABStoGWM_ECG 1;
BA_ "U_CD542_MY2021_Tx" SG_ 2610126888 OTAPhysABStoGWM_ECG 1;
BA_ "U_U55X_MY2022_Tx" SG_ 2610126888 OTAPhysABStoGWM_ECG 1;
BA_ "U_CD764_MY2022_Tx" SG_ 2610126888 OTAPhysABStoGWM_ECG 1;
BA_ "U_CDX706_MY2023_Tx" SG_ 2610126888 OTAPhysABStoGWM_ECG 1;
BA_ "GenSigSendType" SG_ 2611175440 PARSEDPhysPCMtoGWM_ECG 3;
BA_ "U_T6_MCA_MY2020_Rx" SG_ 2611175440 PARSEDPhysPCMtoGWM_ECG 1;
BA_ "ECGUsedRxSignal" SG_ 2611175440 PARSEDPhysPCMtoGWM_ECG 1;
BA_ "U_U55X_MY2022_Rx" SG_ 2611175440 PARSEDPhysPCMtoGWM_ECG 1;
BA_ "U_CD764_MY2022_Rx" SG_ 2611175440 PARSEDPhysPCMtoGWM_ECG 1;
BA_ "U_CDX706_MY2023_Rx" SG_ 2611175440 PARSEDPhysPCMtoGWM_ECG 1;
BA_ "U_P702_MY2021_Tx" SG_ 2611175440 PARSEDPhysPCMtoGWM_ECG 1;
BA_ "U_T6_MCA_MY2020_Tx" SG_ 2611175440 PARSEDPhysPCMtoGWM_ECG 1;
BA_ "U_CD542_MY2021_Tx" SG_ 2611175440 PARSEDPhysPCMtoGWM_ECG 1;
BA_ "U_U55X_MY2022_Tx" SG_ 2611175440 PARSEDPhysPCMtoGWM_ECG 1;
BA_ "U_CD764_MY2022_Tx" SG_ 2611175440 PARSEDPhysPCMtoGWM_ECG 1;
BA_ "U_CDX706_MY2023_Tx" SG_ 2611175440 PARSEDPhysPCMtoGWM_ECG 1;
BA_ "GenSigSendType" SG_ 2609922264 OTAPhysGWM_ECGtoPCM 3;
BA_ "U_P702_MY2021_Rx" SG_ 2609922264 OTAPhysGWM_ECGtoPCM 1;
BA_ "U_T6_MCA_MY2020_Rx" SG_ 2609922264 OTAPhysGWM_ECGtoPCM 1;
BA_ "U_CD542_MY2021_Rx" SG_ 2609922264 OTAPhysGWM_ECGtoPCM 1;
BA_ "U_U55X_MY2022_Rx" SG_ 2609922264 OTAPhysGWM_ECGtoPCM 1;
BA_ "U_CD764_MY2022_Rx" SG_ 2609922264 OTAPhysGWM_ECGtoPCM 1;
BA_ "U_CDX706_MY2023_Rx" SG_ 2609922264 OTAPhysGWM_ECGtoPCM 1;
BA_ "U_T6_MCA_MY2020_Tx" SG_ 2609922264 OTAPhysGWM_ECGtoPCM 1;
BA_ "ECGUsedTxSignal" SG_ 2609922264 OTAPhysGWM_ECGtoPCM 1;
BA_ "U_U55X_MY2022_Tx" SG_ 2609922264 OTAPhysGWM_ECGtoPCM 1;
BA_ "U_CD764_MY2022_Tx" SG_ 2609922264 OTAPhysGWM_ECGtoPCM 1;
BA_ "U_CDX706_MY2023_Tx" SG_ 2609922264 OTAPhysGWM_ECGtoPCM 1;
BA_ "GenSigSendType" SG_ 2610953432 OTAFuncGWM_ECG 3;
BA_ "U_CX727_MY2021_Rx" SG_ 2610953432 OTAFuncGWM_ECG 1;
BA_ "U_P702_MY2021_Rx" SG_ 2610953432 OTAFuncGWM_ECG 1;
BA_ "U_T6_MCA_MY2020_Rx" SG_ 2610953432 OTAFuncGWM_ECG 1;
BA_ "U_CD542_MY2021_Rx" SG_ 2610953432 OTAFuncGWM_ECG 1;
BA_ "U_U55X_MY2022_Rx" SG_ 2610953432 OTAFuncGWM_ECG 1;
BA_ "U_CD764_MY2022_Rx" SG_ 2610953432 OTAFuncGWM_ECG 1;
BA_ "U_CDX706_MY2023_Rx" SG_ 2610953432 OTAFuncGWM_ECG 1;
BA_ "U_T6_MCA_MY2020_Tx" SG_ 2610953432 OTAFuncGWM_ECG 1;
BA_ "ECGUsedTxSignal" SG_ 2610953432 OTAFuncGWM_ECG 1;
BA_ "U_CD542_MY2021_Tx" SG_ 2610953432 OTAFuncGWM_ECG 1;
BA_ "U_U55X_MY2022_Tx" SG_ 2610953432 OTAFuncGWM_ECG 1;
BA_ "U_CD764_MY2022_Tx" SG_ 2610953432 OTAFuncGWM_ECG 1;
BA_ "U_CDX706_MY2023_Tx" SG_ 2610953432 OTAFuncGWM_ECG 1;
BA_ "GenSigSendType" SG_ 2610126864 OTAPhysPCMtoGWM_ECG 3;
BA_ "U_T6_MCA_MY2020_Rx" SG_ 2610126864 OTAPhysPCMtoGWM_ECG 1;
BA_ "ECGUsedRxSignal" SG_ 2610126864 OTAPhysPCMtoGWM_ECG 1;
BA_ "U_U55X_MY2022_Rx" SG_ 2610126864 OTAPhysPCMtoGWM_ECG 1;
BA_ "U_CD764_MY2022_Rx" SG_ 2610126864 OTAPhysPCMtoGWM_ECG 1;
BA_ "U_CDX706_MY2023_Rx" SG_ 2610126864 OTAPhysPCMtoGWM_ECG 1;
BA_ "U_P702_MY2021_Tx" SG_ 2610126864 OTAPhysPCMtoGWM_ECG 1;
BA_ "U_T6_MCA_MY2020_Tx" SG_ 2610126864 OTAPhysPCMtoGWM_ECG 1;
BA_ "U_CD542_MY2021_Tx" SG_ 2610126864 OTAPhysPCMtoGWM_ECG 1;
BA_ "U_U55X_MY2022_Tx" SG_ 2610126864 OTAPhysPCMtoGWM_ECG 1;
BA_ "U_CD764_MY2022_Tx" SG_ 2610126864 OTAPhysPCMtoGWM_ECG 1;
BA_ "U_CDX706_MY2023_Tx" SG_ 2610126864 OTAPhysPCMtoGWM_ECG 1;
BA_ "GenSigSendType" SG_ 2612002008 PARSEDFuncGWM_ECG 3;
BA_ "U_P702_MY2021_Rx" SG_ 2612002008 PARSEDFuncGWM_ECG 1;
BA_ "U_T6_MCA_MY2020_Rx" SG_ 2612002008 PARSEDFuncGWM_ECG 1;
BA_ "U_CD542_MY2021_Rx" SG_ 2612002008 PARSEDFuncGWM_ECG 1;
BA_ "U_U55X_MY2022_Rx" SG_ 2612002008 PARSEDFuncGWM_ECG 1;
BA_ "U_CD764_MY2022_Rx" SG_ 2612002008 PARSEDFuncGWM_ECG 1;
BA_ "U_CDX706_MY2023_Rx" SG_ 2612002008 PARSEDFuncGWM_ECG 1;
BA_ "U_T6_MCA_MY2020_Tx" SG_ 2612002008 PARSEDFuncGWM_ECG 1;
BA_ "ECGUsedTxSignal" SG_ 2612002008 PARSEDFuncGWM_ECG 1;
BA_ "U_CD542_MY2021_Tx" SG_ 2612002008 PARSEDFuncGWM_ECG 1;
BA_ "U_U55X_MY2022_Tx" SG_ 2612002008 PARSEDFuncGWM_ECG 1;
BA_ "U_CD764_MY2022_Tx" SG_ 2612002008 PARSEDFuncGWM_ECG 1;
BA_ "U_CDX706_MY2023_Tx" SG_ 2612002008 PARSEDFuncGWM_ECG 1;
BA_ "GenSigSendType" SG_ 2610970840 PARSEDPhysGWM_ECGtoPCM 3;
BA_ "U_P702_MY2021_Rx" SG_ 2610970840 PARSEDPhysGWM_ECGtoPCM 1;
BA_ "U_T6_MCA_MY2020_Rx" SG_ 2610970840 PARSEDPhysGWM_ECGtoPCM 1;
BA_ "U_CD542_MY2021_Rx" SG_ 2610970840 PARSEDPhysGWM_ECGtoPCM 1;
BA_ "U_U55X_MY2022_Rx" SG_ 2610970840 PARSEDPhysGWM_ECGtoPCM 1;
BA_ "U_CD764_MY2022_Rx" SG_ 2610970840 PARSEDPhysGWM_ECGtoPCM 1;
BA_ "U_CDX706_MY2023_Rx" SG_ 2610970840 PARSEDPhysGWM_ECGtoPCM 1;
BA_ "U_T6_MCA_MY2020_Tx" SG_ 2610970840 PARSEDPhysGWM_ECGtoPCM 1;
BA_ "ECGUsedTxSignal" SG_ 2610970840 PARSEDPhysGWM_ECGtoPCM 1;
BA_ "U_U55X_MY2022_Tx" SG_ 2610970840 PARSEDPhysGWM_ECGtoPCM 1;
BA_ "U_CD764_MY2022_Tx" SG_ 2610970840 PARSEDPhysGWM_ECGtoPCM 1;
BA_ "U_CDX706_MY2023_Tx" SG_ 2610970840 PARSEDPhysGWM_ECGtoPCM 1;
BA_ "GenSigSendType" SG_ 2612224016 PARSEDPushPCMtoGWM_ECG 3;
BA_ "U_T6_MCA_MY2020_Rx" SG_ 2612224016 PARSEDPushPCMtoGWM_ECG 1;
BA_ "ECGUsedRxSignal" SG_ 2612224016 PARSEDPushPCMtoGWM_ECG 1;
BA_ "U_U55X_MY2022_Rx" SG_ 2612224016 PARSEDPushPCMtoGWM_ECG 1;
BA_ "U_CD764_MY2022_Rx" SG_ 2612224016 PARSEDPushPCMtoGWM_ECG 1;
BA_ "U_CDX706_MY2023_Rx" SG_ 2612224016 PARSEDPushPCMtoGWM_ECG 1;
BA_ "U_P702_MY2021_Tx" SG_ 2612224016 PARSEDPushPCMtoGWM_ECG 1;
BA_ "U_T6_MCA_MY2020_Tx" SG_ 2612224016 PARSEDPushPCMtoGWM_ECG 1;
BA_ "U_CD542_MY2021_Tx" SG_ 2612224016 PARSEDPushPCMtoGWM_ECG 1;
BA_ "U_U55X_MY2022_Tx" SG_ 2612224016 PARSEDPushPCMtoGWM_ECG 1;
BA_ "U_CD764_MY2022_Tx" SG_ 2612224016 PARSEDPushPCMtoGWM_ECG 1;
BA_ "U_CDX706_MY2023_Tx" SG_ 2612224016 PARSEDPushPCMtoGWM_ECG 1;
BA_ "GenSigSendType" SG_ 775 ScDayOfWeekId_D_RqCld 3;
BA_ "GenSigStartValue" SG_ 775 ScDayOfWeekId_D_RqCld 1;
BA_ "ECGUsedTxSignal" SG_ 775 ScDayOfWeekId_D_RqCld 1;
BA_ "U_CD542_MY2021_Tx" SG_ 775 ScDayOfWeekId_D_RqCld 1;
BA_ "U_U55X_MY2022_Tx" SG_ 775 ScDayOfWeekId_D_RqCld 1;
BA_ "U_CDX706_MY2023_Tx" SG_ 775 ScDayOfWeekId_D_RqCld 1;
BA_ "GenSigSendType" SG_ 775 ScLocSetId_No_RqCld 3;
BA_ "ECGUsedTxSignal" SG_ 775 ScLocSetId_No_RqCld 1;
BA_ "U_CD542_MY2021_Tx" SG_ 775 ScLocSetId_No_RqCld 1;
BA_ "U_U55X_MY2022_Tx" SG_ 775 ScLocSetId_No_RqCld 1;
BA_ "U_CDX706_MY2023_Tx" SG_ 775 ScLocSetId_No_RqCld 1;
BA_ "GenSigStartValue" SG_ 775 ScLocRdius_L_RqCld 1;
BA_ "ECGUsedTxSignal" SG_ 775 ScLocRdius_L_RqCld 1;
BA_ "U_CD542_MY2021_Tx" SG_ 775 ScLocRdius_L_RqCld 1;
BA_ "U_U55X_MY2022_Tx" SG_ 775 ScLocRdius_L_RqCld 1;
BA_ "U_CDX706_MY2023_Tx" SG_ 775 ScLocRdius_L_RqCld 1;
BA_ "GenSigStartValue" SG_ 775 ScChrgToPc_Pc_RqCld 100;
BA_ "ECGUsedTxSignal" SG_ 775 ScChrgToPc_Pc_RqCld 1;
BA_ "U_CD542_MY2021_Tx" SG_ 775 ScChrgToPc_Pc_RqCld 1;
BA_ "U_U55X_MY2022_Tx" SG_ 775 ScChrgToPc_Pc_RqCld 1;
BA_ "U_CDX706_MY2023_Tx" SG_ 775 ScChrgToPc_Pc_RqCld 1;
BA_ "ECGUsedTxSignal" SG_ 775 ScChrgPrfl_No_RqCld 1;
BA_ "U_CD542_MY2021_Tx" SG_ 775 ScChrgPrfl_No_RqCld 1;
BA_ "U_U55X_MY2022_Tx" SG_ 775 ScChrgPrfl_No_RqCld 1;
BA_ "U_CDX706_MY2023_Tx" SG_ 775 ScChrgPrfl_No_RqCld 1;
BA_ "GenSigStartValue" SG_ 775 ScChrgDurSet_D_RqCld 1;
BA_ "ECGUsedTxSignal" SG_ 775 ScChrgDurSet_D_RqCld 1;
BA_ "U_CD542_MY2021_Tx" SG_ 775 ScChrgDurSet_D_RqCld 1;
BA_ "U_U55X_MY2022_Tx" SG_ 775 ScChrgDurSet_D_RqCld 1;
BA_ "U_CDX706_MY2023_Tx" SG_ 775 ScChrgDurSet_D_RqCld 1;
BA_ "ECGUsedTxSignal" SG_ 775 ScChrgDur_T_RqCld 1;
BA_ "U_CD542_MY2021_Tx" SG_ 775 ScChrgDur_T_RqCld 1;
BA_ "U_U55X_MY2022_Tx" SG_ 775 ScChrgDur_T_RqCld 1;
BA_ "U_CDX706_MY2023_Tx" SG_ 775 ScChrgDur_T_RqCld 1;
BA_ "ECGUsedTxSignal" SG_ 774 ScLocLongPostv_B_RqCld 1;
BA_ "U_CD542_MY2021_Tx" SG_ 774 ScLocLongPostv_B_RqCld 1;
BA_ "U_U55X_MY2022_Tx" SG_ 774 ScLocLongPostv_B_RqCld 1;
BA_ "U_CDX706_MY2023_Tx" SG_ 774 ScLocLongPostv_B_RqCld 1;
BA_ "GenSigStartValue" SG_ 774 ScLocLongFrct_An_RqCld 1048575;
BA_ "ECGUsedTxSignal" SG_ 774 ScLocLongFrct_An_RqCld 1;
BA_ "U_CD542_MY2021_Tx" SG_ 774 ScLocLongFrct_An_RqCld 1;
BA_ "U_U55X_MY2022_Tx" SG_ 774 ScLocLongFrct_An_RqCld 1;
BA_ "U_CDX706_MY2023_Tx" SG_ 774 ScLocLongFrct_An_RqCld 1;
BA_ "ECGUsedTxSignal" SG_ 774 ScLocLongDeg_An_RqCld 1;
BA_ "U_CD542_MY2021_Tx" SG_ 774 ScLocLongDeg_An_RqCld 1;
BA_ "U_U55X_MY2022_Tx" SG_ 774 ScLocLongDeg_An_RqCld 1;
BA_ "U_CDX706_MY2023_Tx" SG_ 774 ScLocLongDeg_An_RqCld 1;
BA_ "ECGUsedTxSignal" SG_ 774 ScLocLattPostv_B_RqCld 1;
BA_ "U_CD542_MY2021_Tx" SG_ 774 ScLocLattPostv_B_RqCld 1;
BA_ "U_U55X_MY2022_Tx" SG_ 774 ScLocLattPostv_B_RqCld 1;
BA_ "U_CDX706_MY2023_Tx" SG_ 774 ScLocLattPostv_B_RqCld 1;
BA_ "GenSigStartValue" SG_ 774 ScLocLattFrct_An_RqCld 1048575;
BA_ "ECGUsedTxSignal" SG_ 774 ScLocLattFrct_An_RqCld 1;
BA_ "U_CD542_MY2021_Tx" SG_ 774 ScLocLattFrct_An_RqCld 1;
BA_ "U_U55X_MY2022_Tx" SG_ 774 ScLocLattFrct_An_RqCld 1;
BA_ "U_CDX706_MY2023_Tx" SG_ 774 ScLocLattFrct_An_RqCld 1;
BA_ "ECGUsedTxSignal" SG_ 774 ScLocLattDeg_An_RqCld 1;
BA_ "U_CD542_MY2021_Tx" SG_ 774 ScLocLattDeg_An_RqCld 1;
BA_ "U_U55X_MY2022_Tx" SG_ 774 ScLocLattDeg_An_RqCld 1;
BA_ "U_CDX706_MY2023_Tx" SG_ 774 ScLocLattDeg_An_RqCld 1;
BA_ "GenSigSendType" SG_ 774 ScLocId_No_RqCld 3;
BA_ "ECGUsedTxSignal" SG_ 774 ScLocId_No_RqCld 1;
BA_ "U_CD542_MY2021_Tx" SG_ 774 ScLocId_No_RqCld 1;
BA_ "U_U55X_MY2022_Tx" SG_ 774 ScLocId_No_RqCld 1;
BA_ "U_CDX706_MY2023_Tx" SG_ 774 ScLocId_No_RqCld 1;
BA_ "GenSigSendType" SG_ 774 ScLocDelete_B_RqCld 3;
BA_ "ECGUsedTxSignal" SG_ 774 ScLocDelete_B_RqCld 1;
BA_ "U_CD542_MY2021_Tx" SG_ 774 ScLocDelete_B_RqCld 1;
BA_ "U_U55X_MY2022_Tx" SG_ 774 ScLocDelete_B_RqCld 1;
BA_ "U_CDX706_MY2023_Tx" SG_ 774 ScLocDelete_B_RqCld 1;
BA_ "GenSigStartValueInteger" SG_ 943 VehVActlAdas_D_Qf 1;
BA_ "MetaData" SG_ 943 VehVActlAdas_D_Qf 1;
BA_ "GenSigStartValue" SG_ 943 VehVActlAdas_D_Qf 1;
BA_ "U_T6_MCA_MY2020_Rx" SG_ 943 VehVActlAdas_D_Qf 1;
BA_ "U_CD764_MY2022_Rx" SG_ 943 VehVActlAdas_D_Qf 1;
BA_ "U_CDX706_MY2023_Rx" SG_ 943 VehVActlAdas_D_Qf 1;
BA_ "U_T6_MCA_MY2020_Tx" SG_ 943 VehVActlAdas_D_Qf 1;
BA_ "U_CD542_MY2021_Tx" SG_ 943 VehVActlAdas_D_Qf 1;
BA_ "U_U55X_MY2022_Tx" SG_ 943 VehVActlAdas_D_Qf 1;
BA_ "U_CD764_MY2022_Tx" SG_ 943 VehVActlAdas_D_Qf 1;
BA_ "U_CDX706_MY2023_Tx" SG_ 943 VehVActlAdas_D_Qf 1;
BA_ "U_T6_MCA_MY2020_Rx" SG_ 943 Veh_V_RqLsc 1;
BA_ "U_CD764_MY2022_Rx" SG_ 943 Veh_V_RqLsc 1;
BA_ "U_CDX706_MY2023_Rx" SG_ 943 Veh_V_RqLsc 1;
BA_ "U_T6_MCA_MY2020_Tx" SG_ 943 Veh_V_RqLsc 1;
BA_ "U_CD542_MY2021_Tx" SG_ 943 Veh_V_RqLsc 1;
BA_ "U_U55X_MY2022_Tx" SG_ 943 Veh_V_RqLsc 1;
BA_ "U_CD764_MY2022_Tx" SG_ 943 Veh_V_RqLsc 1;
BA_ "U_CDX706_MY2023_Tx" SG_ 943 Veh_V_RqLsc 1;
BA_ "U_T6_MCA_MY2020_Rx" SG_ 943 Veh_V_ActlAdas 1;
BA_ "U_CD764_MY2022_Rx" SG_ 943 Veh_V_ActlAdas 1;
BA_ "U_CDX706_MY2023_Rx" SG_ 943 Veh_V_ActlAdas 1;
BA_ "U_T6_MCA_MY2020_Tx" SG_ 943 Veh_V_ActlAdas 1;
BA_ "U_CD542_MY2021_Tx" SG_ 943 Veh_V_ActlAdas 1;
BA_ "U_U55X_MY2022_Tx" SG_ 943 Veh_V_ActlAdas 1;
BA_ "U_CD764_MY2022_Tx" SG_ 943 Veh_V_ActlAdas 1;
BA_ "U_CDX706_MY2023_Tx" SG_ 943 Veh_V_ActlAdas 1;
BA_ "GenSigStartValue" SG_ 943 AdasLcDistToObj_L_Actl 4094;
BA_ "U_T6_MCA_MY2020_Rx" SG_ 943 AdasLcDistToObj_L_Actl 1;
BA_ "U_CD764_MY2022_Rx" SG_ 943 AdasLcDistToObj_L_Actl 1;
BA_ "U_CDX706_MY2023_Rx" SG_ 943 AdasLcDistToObj_L_Actl 1;
BA_ "U_T6_MCA_MY2020_Tx" SG_ 943 AdasLcDistToObj_L_Actl 1;
BA_ "U_CD542_MY2021_Tx" SG_ 943 AdasLcDistToObj_L_Actl 1;
BA_ "U_U55X_MY2022_Tx" SG_ 943 AdasLcDistToObj_L_Actl 1;
BA_ "U_CD764_MY2022_Tx" SG_ 943 AdasLcDistToObj_L_Actl 1;
BA_ "U_CDX706_MY2023_Tx" SG_ 943 AdasLcDistToObj_L_Actl 1;
BA_ "GenSigSendType" SG_ 1816 TesterPhysicalResCHCM 3;
BA_ "U_T6_MCA_MY2020_Tx" SG_ 1816 TesterPhysicalResCHCM 1;
BA_ "GenSigSendType" SG_ 1808 TesterPhysicalReqCHCM 3;
BA_ "U_T6_MCA_MY2020_Rx" SG_ 1808 TesterPhysicalReqCHCM 1;
BA_ "GenSigSendType" SG_ 930 BalrWndwRight_B_Stat 3;
BA_ "U_T6_MCA_MY2020_Tx" SG_ 930 BalrWndwRight_B_Stat 1;
BA_ "U_CD542_MY2021_Tx" SG_ 930 BalrWndwRight_B_Stat 1;
BA_ "U_U55X_MY2022_Tx" SG_ 930 BalrWndwRight_B_Stat 1;
BA_ "U_CD764_MY2022_Tx" SG_ 930 BalrWndwRight_B_Stat 1;
BA_ "GenSigSendType" SG_ 930 BalrSnsRight_D_Falt 3;
BA_ "U_T6_MCA_MY2020_Tx" SG_ 930 BalrSnsRight_D_Falt 1;
BA_ "U_CD542_MY2021_Tx" SG_ 930 BalrSnsRight_D_Falt 1;
BA_ "U_U55X_MY2022_Tx" SG_ 930 BalrSnsRight_D_Falt 1;
BA_ "U_CD764_MY2022_Tx" SG_ 930 BalrSnsRight_D_Falt 1;
BA_ "GenSigSendType" SG_ 930 WndwPsngrRear_D_RqBalrr 3;
BA_ "U_T6_MCA_MY2020_Tx" SG_ 930 WndwPsngrRear_D_RqBalrr 1;
BA_ "U_CD542_MY2021_Tx" SG_ 930 WndwPsngrRear_D_RqBalrr 1;
BA_ "U_U55X_MY2022_Tx" SG_ 930 WndwPsngrRear_D_RqBalrr 1;
BA_ "U_CD764_MY2022_Tx" SG_ 930 WndwPsngrRear_D_RqBalrr 1;
BA_ "GenSigSendType" SG_ 930 WndwPsngr_D_RqBalrr 3;
BA_ "U_T6_MCA_MY2020_Tx" SG_ 930 WndwPsngr_D_RqBalrr 1;
BA_ "U_CD542_MY2021_Tx" SG_ 930 WndwPsngr_D_RqBalrr 1;
BA_ "U_U55X_MY2022_Tx" SG_ 930 WndwPsngr_D_RqBalrr 1;
BA_ "U_CD764_MY2022_Tx" SG_ 930 WndwPsngr_D_RqBalrr 1;
BA_ "GenSigSendType" SG_ 930 WndwDrvRear_D_RqBalrr 3;
BA_ "U_T6_MCA_MY2020_Tx" SG_ 930 WndwDrvRear_D_RqBalrr 1;
BA_ "U_CD542_MY2021_Tx" SG_ 930 WndwDrvRear_D_RqBalrr 1;
BA_ "U_U55X_MY2022_Tx" SG_ 930 WndwDrvRear_D_RqBalrr 1;
BA_ "U_CD764_MY2022_Tx" SG_ 930 WndwDrvRear_D_RqBalrr 1;
BA_ "GenSigSendType" SG_ 930 WndwDrv_D_RqBalrr 3;
BA_ "U_T6_MCA_MY2020_Tx" SG_ 930 WndwDrv_D_RqBalrr 1;
BA_ "U_CD542_MY2021_Tx" SG_ 930 WndwDrv_D_RqBalrr 1;
BA_ "U_U55X_MY2022_Tx" SG_ 930 WndwDrv_D_RqBalrr 1;
BA_ "U_CD764_MY2022_Tx" SG_ 930 WndwDrv_D_RqBalrr 1;
BA_ "GenSigSendType" SG_ 930 BalrRight_D_Stat 3;
BA_ "GenSigStartValueInteger" SG_ 930 BalrRight_D_Stat 2;
BA_ "GenSigStartValue" SG_ 930 BalrRight_D_Stat 2;
BA_ "U_T6_MCA_MY2020_Tx" SG_ 930 BalrRight_D_Stat 1;
BA_ "U_CD542_MY2021_Tx" SG_ 930 BalrRight_D_Stat 1;
BA_ "U_U55X_MY2022_Tx" SG_ 930 BalrRight_D_Stat 1;
BA_ "U_CD764_MY2022_Tx" SG_ 930 BalrRight_D_Stat 1;
BA_ "GenSigSendType" SG_ 930 BalrMdeSelRight_B_Stat 3;
BA_ "U_T6_MCA_MY2020_Tx" SG_ 930 BalrMdeSelRight_B_Stat 1;
BA_ "U_CD542_MY2021_Tx" SG_ 930 BalrMdeSelRight_B_Stat 1;
BA_ "U_U55X_MY2022_Tx" SG_ 930 BalrMdeSelRight_B_Stat 1;
BA_ "U_CD764_MY2022_Tx" SG_ 930 BalrMdeSelRight_B_Stat 1;
BA_ "GenSigSendType" SG_ 930 BalrMdeRight_D_Stat 3;
BA_ "GenSigStartValueInteger" SG_ 930 BalrMdeRight_D_Stat 1;
BA_ "GenSigStartValue" SG_ 930 BalrMdeRight_D_Stat 1;
BA_ "U_T6_MCA_MY2020_Tx" SG_ 930 BalrMdeRight_D_Stat 1;
BA_ "U_CD542_MY2021_Tx" SG_ 930 BalrMdeRight_D_Stat 1;
BA_ "U_U55X_MY2022_Tx" SG_ 930 BalrMdeRight_D_Stat 1;
BA_ "U_CD764_MY2022_Tx" SG_ 930 BalrMdeRight_D_Stat 1;
BA_ "GenSigSendType" SG_ 930 BalrLckRight_B_Stat 3;
BA_ "U_T6_MCA_MY2020_Tx" SG_ 930 BalrLckRight_B_Stat 1;
BA_ "U_CD542_MY2021_Tx" SG_ 930 BalrLckRight_B_Stat 1;
BA_ "U_U55X_MY2022_Tx" SG_ 930 BalrLckRight_B_Stat 1;
BA_ "U_CD764_MY2022_Tx" SG_ 930 BalrLckRight_B_Stat 1;
BA_ "GenSigSendType" SG_ 930 BalrChimeRight_D_Rq 3;
BA_ "U_T6_MCA_MY2020_Tx" SG_ 930 BalrChimeRight_D_Rq 1;
BA_ "U_CD542_MY2021_Tx" SG_ 930 BalrChimeRight_D_Rq 1;
BA_ "U_U55X_MY2022_Tx" SG_ 930 BalrChimeRight_D_Rq 1;
BA_ "U_CD764_MY2022_Tx" SG_ 930 BalrChimeRight_D_Rq 1;
BA_ "GenSigSendType" SG_ 930 CamraRearOn_B_RqBalrr 3;
BA_ "U_T6_MCA_MY2020_Tx" SG_ 930 CamraRearOn_B_RqBalrr 1;
BA_ "U_CD542_MY2021_Tx" SG_ 930 CamraRearOn_B_RqBalrr 1;
BA_ "U_U55X_MY2022_Tx" SG_ 930 CamraRearOn_B_RqBalrr 1;
BA_ "U_CD764_MY2022_Tx" SG_ 930 CamraRearOn_B_RqBalrr 1;
BA_ "GenSigSendType" SG_ 930 DrLckCnt_No_ActlBalrr 3;
BA_ "U_T6_MCA_MY2020_Tx" SG_ 930 DrLckCnt_No_ActlBalrr 1;
BA_ "U_CD542_MY2021_Tx" SG_ 930 DrLckCnt_No_ActlBalrr 1;
BA_ "U_U55X_MY2022_Tx" SG_ 930 DrLckCnt_No_ActlBalrr 1;
BA_ "U_CD764_MY2022_Tx" SG_ 930 DrLckCnt_No_ActlBalrr 1;
BA_ "GenSigSendType" SG_ 930 DrLckActv_B_RqBalrr 3;
BA_ "U_T6_MCA_MY2020_Tx" SG_ 930 DrLckActv_B_RqBalrr 1;
BA_ "U_CD542_MY2021_Tx" SG_ 930 DrLckActv_B_RqBalrr 1;
BA_ "U_U55X_MY2022_Tx" SG_ 930 DrLckActv_B_RqBalrr 1;
BA_ "U_CD764_MY2022_Tx" SG_ 930 DrLckActv_B_RqBalrr 1;
BA_ "GenSigSendType" SG_ 929 BalrChimeLeft_D_Rq 3;
BA_ "U_T6_MCA_MY2020_Tx" SG_ 929 BalrChimeLeft_D_Rq 1;
BA_ "U_CD542_MY2021_Tx" SG_ 929 BalrChimeLeft_D_Rq 1;
BA_ "U_U55X_MY2022_Tx" SG_ 929 BalrChimeLeft_D_Rq 1;
BA_ "U_CD764_MY2022_Tx" SG_ 929 BalrChimeLeft_D_Rq 1;
BA_ "GenSigSendType" SG_ 929 BalrLeft_D_Stat 3;
BA_ "GenSigStartValueInteger" SG_ 929 BalrLeft_D_Stat 2;
BA_ "GenSigStartValue" SG_ 929 BalrLeft_D_Stat 2;
BA_ "U_T6_MCA_MY2020_Tx" SG_ 929 BalrLeft_D_Stat 1;
BA_ "U_CD542_MY2021_Tx" SG_ 929 BalrLeft_D_Stat 1;
BA_ "U_U55X_MY2022_Tx" SG_ 929 BalrLeft_D_Stat 1;
BA_ "U_CD764_MY2022_Tx" SG_ 929 BalrLeft_D_Stat 1;
BA_ "GenSigSendType" SG_ 929 WndwPsngrRear_D_RqBalrl 3;
BA_ "U_T6_MCA_MY2020_Tx" SG_ 929 WndwPsngrRear_D_RqBalrl 1;
BA_ "U_CD542_MY2021_Tx" SG_ 929 WndwPsngrRear_D_RqBalrl 1;
BA_ "U_U55X_MY2022_Tx" SG_ 929 WndwPsngrRear_D_RqBalrl 1;
BA_ "U_CD764_MY2022_Tx" SG_ 929 WndwPsngrRear_D_RqBalrl 1;
BA_ "GenSigSendType" SG_ 929 WndwPsngr_D_RqBalrl 3;
BA_ "U_T6_MCA_MY2020_Tx" SG_ 929 WndwPsngr_D_RqBalrl 1;
BA_ "U_CD542_MY2021_Tx" SG_ 929 WndwPsngr_D_RqBalrl 1;
BA_ "U_U55X_MY2022_Tx" SG_ 929 WndwPsngr_D_RqBalrl 1;
BA_ "U_CD764_MY2022_Tx" SG_ 929 WndwPsngr_D_RqBalrl 1;
BA_ "GenSigSendType" SG_ 929 WndwDrvRear_D_RqBalrl 3;
BA_ "U_T6_MCA_MY2020_Tx" SG_ 929 WndwDrvRear_D_RqBalrl 1;
BA_ "U_CD542_MY2021_Tx" SG_ 929 WndwDrvRear_D_RqBalrl 1;
BA_ "U_U55X_MY2022_Tx" SG_ 929 WndwDrvRear_D_RqBalrl 1;
BA_ "U_CD764_MY2022_Tx" SG_ 929 WndwDrvRear_D_RqBalrl 1;
BA_ "GenSigSendType" SG_ 929 WndwDrv_D_RqBalrl 3;
BA_ "U_T6_MCA_MY2020_Tx" SG_ 929 WndwDrv_D_RqBalrl 1;
BA_ "U_CD542_MY2021_Tx" SG_ 929 WndwDrv_D_RqBalrl 1;
BA_ "U_U55X_MY2022_Tx" SG_ 929 WndwDrv_D_RqBalrl 1;
BA_ "U_CD764_MY2022_Tx" SG_ 929 WndwDrv_D_RqBalrl 1;
BA_ "GenSigSendType" SG_ 929 BalrSnsLeft_D_Falt 3;
BA_ "U_T6_MCA_MY2020_Tx" SG_ 929 BalrSnsLeft_D_Falt 1;
BA_ "U_CD542_MY2021_Tx" SG_ 929 BalrSnsLeft_D_Falt 1;
BA_ "U_U55X_MY2022_Tx" SG_ 929 BalrSnsLeft_D_Falt 1;
BA_ "U_CD764_MY2022_Tx" SG_ 929 BalrSnsLeft_D_Falt 1;
BA_ "GenSigSendType" SG_ 929 BalrMdeSelLeft_B_Stat 3;
BA_ "U_T6_MCA_MY2020_Tx" SG_ 929 BalrMdeSelLeft_B_Stat 1;
BA_ "U_CD542_MY2021_Tx" SG_ 929 BalrMdeSelLeft_B_Stat 1;
BA_ "U_U55X_MY2022_Tx" SG_ 929 BalrMdeSelLeft_B_Stat 1;
BA_ "U_CD764_MY2022_Tx" SG_ 929 BalrMdeSelLeft_B_Stat 1;
BA_ "GenSigSendType" SG_ 929 BalrMdeLeft_D_Stat 3;
BA_ "GenSigStartValueInteger" SG_ 929 BalrMdeLeft_D_Stat 1;
BA_ "GenSigStartValue" SG_ 929 BalrMdeLeft_D_Stat 1;
BA_ "U_T6_MCA_MY2020_Tx" SG_ 929 BalrMdeLeft_D_Stat 1;
BA_ "U_CD542_MY2021_Tx" SG_ 929 BalrMdeLeft_D_Stat 1;
BA_ "U_U55X_MY2022_Tx" SG_ 929 BalrMdeLeft_D_Stat 1;
BA_ "U_CD764_MY2022_Tx" SG_ 929 BalrMdeLeft_D_Stat 1;
BA_ "GenSigSendType" SG_ 929 BalrLckLeft_B_Stat 3;
BA_ "U_T6_MCA_MY2020_Tx" SG_ 929 BalrLckLeft_B_Stat 1;
BA_ "U_CD542_MY2021_Tx" SG_ 929 BalrLckLeft_B_Stat 1;
BA_ "U_U55X_MY2022_Tx" SG_ 929 BalrLckLeft_B_Stat 1;
BA_ "U_CD764_MY2022_Tx" SG_ 929 BalrLckLeft_B_Stat 1;
BA_ "GenSigSendType" SG_ 929 CamraRearOn_B_RqBalrl 3;
BA_ "U_T6_MCA_MY2020_Tx" SG_ 929 CamraRearOn_B_RqBalrl 1;
BA_ "U_CD542_MY2021_Tx" SG_ 929 CamraRearOn_B_RqBalrl 1;
BA_ "U_U55X_MY2022_Tx" SG_ 929 CamraRearOn_B_RqBalrl 1;
BA_ "U_CD764_MY2022_Tx" SG_ 929 CamraRearOn_B_RqBalrl 1;
BA_ "GenSigSendType" SG_ 929 DrLckCnt_No_ActlBalrl 3;
BA_ "U_T6_MCA_MY2020_Tx" SG_ 929 DrLckCnt_No_ActlBalrl 1;
BA_ "U_CD542_MY2021_Tx" SG_ 929 DrLckCnt_No_ActlBalrl 1;
BA_ "U_U55X_MY2022_Tx" SG_ 929 DrLckCnt_No_ActlBalrl 1;
BA_ "U_CD764_MY2022_Tx" SG_ 929 DrLckCnt_No_ActlBalrl 1;
BA_ "GenSigSendType" SG_ 929 DrLckActv_B_RqBalrl 3;
BA_ "U_T6_MCA_MY2020_Tx" SG_ 929 DrLckActv_B_RqBalrl 1;
BA_ "U_CD542_MY2021_Tx" SG_ 929 DrLckActv_B_RqBalrl 1;
BA_ "U_U55X_MY2022_Tx" SG_ 929 DrLckActv_B_RqBalrl 1;
BA_ "U_CD764_MY2022_Tx" SG_ 929 DrLckActv_B_RqBalrl 1;
BA_ "GenSigSendType" SG_ 929 BalrWndwLeft_B_Stat 3;
BA_ "U_T6_MCA_MY2020_Tx" SG_ 929 BalrWndwLeft_B_Stat 1;
BA_ "U_U55X_MY2022_Tx" SG_ 929 BalrWndwLeft_B_Stat 1;
BA_ "U_CD764_MY2022_Tx" SG_ 929 BalrWndwLeft_B_Stat 1;
BA_ "GenSigSendType" SG_ 1783 TesterPhysicalReqLDCMB 3;
BA_ "U_P702_MY2021_Rx" SG_ 867 BattRgenLoBalnc_B_Rq 1;
BA_ "GenSigStartValue" SG_ 867 BattRgenLo_Te_Hi 45;
BA_ "U_P702_MY2021_Rx" SG_ 867 BattRgenLo_Te_Hi 1;
BA_ "GenSigStartValue" SG_ 867 BattRgenLo_Te_Actl 85;
BA_ "U_P702_MY2021_Rx" SG_ 867 BattRgenLo_Te_Actl 1;
BA_ "U_P702_MY2021_Rx" SG_ 867 BattRgenLo_R_Actl 1;
BA_ "GenSigStartValue" SG_ 867 BattRgenLo_AhRide_Actl 12800;
BA_ "U_P702_MY2021_Rx" SG_ 867 BattRgenLo_AhRide_Actl 1;
BA_ "GenSigStartValueInteger" SG_ 867 BattRgenLo_Ah_Actl 5;
BA_ "GenSigStartValue" SG_ 867 BattRgenLo_Ah_Actl 50;
BA_ "U_P702_MY2021_Rx" SG_ 867 BattRgenLo_Ah_Actl 1;
BA_ "GenSigStartValue" SG_ 866 BattRgenLoOpen_U_Actl 180;
BA_ "U_P702_MY2021_Rx" SG_ 866 BattRgenLoOpen_U_Actl 1;
BA_ "GenSigStartValue" SG_ 866 BattRgenLoDchrg_U_Mn 280;
BA_ "U_P702_MY2021_Rx" SG_ 866 BattRgenLoDchrg_U_Mn 1;
BA_ "U_P702_MY2021_Rx" SG_ 866 BattRgenLoDchrg_I_Mx 1;
BA_ "GenSigStartValue" SG_ 866 BattRgenLoChrg_U_Mx 96;
BA_ "U_P702_MY2021_Rx" SG_ 866 BattRgenLoChrg_U_Mx 1;
BA_ "U_P702_MY2021_Rx" SG_ 866 BattRgenLoChrg_I_Mx 1;
BA_ "GenSigStartValue" SG_ 865 BattRgenLo_U_Actl 768;
BA_ "U_P702_MY2021_Rx" SG_ 865 BattRgenLo_U_Actl 1;
BA_ "GenSigStartValue" SG_ 865 BattRgenLo_I_Actl 32768;
BA_ "U_P702_MY2021_Rx" SG_ 865 BattRgenLo_I_Actl 1;
BA_ "GenSigSendType" SG_ 2612194520 PARSEDPushFcGWM_ECGtoCMR 3;
BA_ "U_T6_MCA_MY2020_Rx" SG_ 2612194520 PARSEDPushFcGWM_ECGtoCMR 1;
BA_ "U_CD542_MY2021_Rx" SG_ 2612194520 PARSEDPushFcGWM_ECGtoCMR 1;
BA_ "U_U55X_MY2022_Rx" SG_ 2612194520 PARSEDPushFcGWM_ECGtoCMR 1;
BA_ "U_CD764_MY2022_Rx" SG_ 2612194520 PARSEDPushFcGWM_ECGtoCMR 1;
BA_ "U_CDX706_MY2023_Rx" SG_ 2612194520 PARSEDPushFcGWM_ECGtoCMR 1;
BA_ "U_T6_MCA_MY2020_Tx" SG_ 2612194520 PARSEDPushFcGWM_ECGtoCMR 1;
BA_ "ECGUsedTxSignal" SG_ 2612194520 PARSEDPushFcGWM_ECGtoCMR 1;
BA_ "U_CD542_MY2021_Tx" SG_ 2612194520 PARSEDPushFcGWM_ECGtoCMR 1;
BA_ "U_U55X_MY2022_Tx" SG_ 2612194520 PARSEDPushFcGWM_ECGtoCMR 1;
BA_ "U_CDX706_MY2023_Tx" SG_ 2612194520 PARSEDPushFcGWM_ECGtoCMR 1;
BA_ "GenSigSendType" SG_ 2610127035 OTAPhysCMRtoGWM_ECG 3;
BA_ "U_T6_MCA_MY2020_Rx" SG_ 2610127035 OTAPhysCMRtoGWM_ECG 1;
BA_ "ECGUsedRxSignal" SG_ 2610127035 OTAPhysCMRtoGWM_ECG 1;
BA_ "U_CD542_MY2021_Rx" SG_ 2610127035 OTAPhysCMRtoGWM_ECG 1;
BA_ "U_U55X_MY2022_Rx" SG_ 2610127035 OTAPhysCMRtoGWM_ECG 1;
BA_ "U_CDX706_MY2023_Rx" SG_ 2610127035 OTAPhysCMRtoGWM_ECG 1;
BA_ "U_T6_MCA_MY2020_Tx" SG_ 2610127035 OTAPhysCMRtoGWM_ECG 1;
BA_ "U_CD542_MY2021_Tx" SG_ 2610127035 OTAPhysCMRtoGWM_ECG 1;
BA_ "U_U55X_MY2022_Tx" SG_ 2610127035 OTAPhysCMRtoGWM_ECG 1;
BA_ "U_CD764_MY2022_Tx" SG_ 2610127035 OTAPhysCMRtoGWM_ECG 1;
BA_ "U_CDX706_MY2023_Tx" SG_ 2610127035 OTAPhysCMRtoGWM_ECG 1;
BA_ "GenSigSendType" SG_ 2610097368 OTAPhysGWM_ECGtoCMR 3;
BA_ "U_T6_MCA_MY2020_Rx" SG_ 2610097368 OTAPhysGWM_ECGtoCMR 1;
BA_ "U_CD542_MY2021_Rx" SG_ 2610097368 OTAPhysGWM_ECGtoCMR 1;
BA_ "U_U55X_MY2022_Rx" SG_ 2610097368 OTAPhysGWM_ECGtoCMR 1;
BA_ "U_CD764_MY2022_Rx" SG_ 2610097368 OTAPhysGWM_ECGtoCMR 1;
BA_ "U_CDX706_MY2023_Rx" SG_ 2610097368 OTAPhysGWM_ECGtoCMR 1;
BA_ "U_T6_MCA_MY2020_Tx" SG_ 2610097368 OTAPhysGWM_ECGtoCMR 1;
BA_ "ECGUsedTxSignal" SG_ 2610097368 OTAPhysGWM_ECGtoCMR 1;
BA_ "U_CD542_MY2021_Tx" SG_ 2610097368 OTAPhysGWM_ECGtoCMR 1;
BA_ "U_U55X_MY2022_Tx" SG_ 2610097368 OTAPhysGWM_ECGtoCMR 1;
BA_ "U_CDX706_MY2023_Tx" SG_ 2610097368 OTAPhysGWM_ECGtoCMR 1;
BA_ "U_U55X_MY2022_Rx" SG_ 402 ApaSlotAlrtSet_D_RqDrv 1;
BA_ "U_CDX706_MY2023_Rx" SG_ 402 ApaSlotAlrtSet_D_RqDrv 1;
BA_ "U_U55X_MY2022_Rx" SG_ 402 ApaFeat_D_RqDrv 1;
BA_ "U_CDX706_MY2023_Rx" SG_ 402 ApaFeat_D_RqDrv 1;
BA_ "U_U55X_MY2022_Rx" SG_ 402 ApaSlotTrgt_D_RqDrv 1;
BA_ "U_CDX706_MY2023_Rx" SG_ 402 ApaSlotTrgt_D_RqDrv 1;
BA_ "U_U55X_MY2022_Rx" SG_ 402 ApaFeatChange_B_RqDrv 1;
BA_ "U_CDX706_MY2023_Rx" SG_ 402 ApaFeatChange_B_RqDrv 1;
BA_ "U_T6_MCA_MY2020_Rx" SG_ 402 CamraFrntBttn_D_Stat3 1;
BA_ "U_CD542_MY2021_Rx" SG_ 402 CamraFrntBttn_D_Stat3 1;
BA_ "U_U55X_MY2022_Rx" SG_ 402 CamraFrntBttn_D_Stat3 1;
BA_ "U_CD764_MY2022_Rx" SG_ 402 CamraFrntBttn_D_Stat3 1;
BA_ "U_CDX706_MY2023_Rx" SG_ 402 CamraFrntBttn_D_Stat3 1;
BA_ "U_T6_MCA_MY2020_Rx" SG_ 402 PrkAidSwtch_D_RqMnu 1;
BA_ "U_CD542_MY2021_Rx" SG_ 402 PrkAidSwtch_D_RqMnu 1;
BA_ "U_U55X_MY2022_Rx" SG_ 402 PrkAidSwtch_D_RqMnu 1;
BA_ "U_CD764_MY2022_Rx" SG_ 402 PrkAidSwtch_D_RqMnu 1;
BA_ "U_CDX706_MY2023_Rx" SG_ 402 PrkAidSwtch_D_RqMnu 1;
BA_ "U_T6_MCA_MY2020_Rx" SG_ 402 ApaSwtch_D_RqMnu 1;
BA_ "U_CD542_MY2021_Rx" SG_ 402 ApaSwtch_D_RqMnu 1;
BA_ "U_U55X_MY2022_Rx" SG_ 402 ApaSwtch_D_RqMnu 1;
BA_ "U_CD764_MY2022_Rx" SG_ 402 ApaSwtch_D_RqMnu 1;
BA_ "U_CDX706_MY2023_Rx" SG_ 402 ApaSwtch_D_RqMnu 1;
BA_ "U_T6_MCA_MY2020_Rx" SG_ 402 ApaMdeStat_D_RqDrv 1;
BA_ "U_CD542_MY2021_Rx" SG_ 402 ApaMdeStat_D_RqDrv 1;
BA_ "U_U55X_MY2022_Rx" SG_ 402 ApaMdeStat_D_RqDrv 1;
BA_ "U_CD764_MY2022_Rx" SG_ 402 ApaMdeStat_D_RqDrv 1;
BA_ "U_CDX706_MY2023_Rx" SG_ 402 ApaMdeStat_D_RqDrv 1;
BA_ "GenSigSendType" SG_ 2611145944 PARSEDPhysGWM_ECGtoCMR 3;
BA_ "U_T6_MCA_MY2020_Rx" SG_ 2611145944 PARSEDPhysGWM_ECGtoCMR 1;
BA_ "U_CD542_MY2021_Rx" SG_ 2611145944 PARSEDPhysGWM_ECGtoCMR 1;
BA_ "U_U55X_MY2022_Rx" SG_ 2611145944 PARSEDPhysGWM_ECGtoCMR 1;
BA_ "U_CD764_MY2022_Rx" SG_ 2611145944 PARSEDPhysGWM_ECGtoCMR 1;
BA_ "U_CDX706_MY2023_Rx" SG_ 2611145944 PARSEDPhysGWM_ECGtoCMR 1;
BA_ "U_T6_MCA_MY2020_Tx" SG_ 2611145944 PARSEDPhysGWM_ECGtoCMR 1;
BA_ "ECGUsedTxSignal" SG_ 2611145944 PARSEDPhysGWM_ECGtoCMR 1;
BA_ "U_CD542_MY2021_Tx" SG_ 2611145944 PARSEDPhysGWM_ECGtoCMR 1;
BA_ "U_U55X_MY2022_Tx" SG_ 2611145944 PARSEDPhysGWM_ECGtoCMR 1;
BA_ "U_CDX706_MY2023_Tx" SG_ 2611145944 PARSEDPhysGWM_ECGtoCMR 1;
BA_ "GenSigSendType" SG_ 2611175611 PARSEDPhysCMRtoGWM_ECG 3;
BA_ "U_T6_MCA_MY2020_Rx" SG_ 2611175611 PARSEDPhysCMRtoGWM_ECG 1;
BA_ "ECGUsedRxSignal" SG_ 2611175611 PARSEDPhysCMRtoGWM_ECG 1;
BA_ "U_CD542_MY2021_Rx" SG_ 2611175611 PARSEDPhysCMRtoGWM_ECG 1;
BA_ "U_U55X_MY2022_Rx" SG_ 2611175611 PARSEDPhysCMRtoGWM_ECG 1;
BA_ "U_CDX706_MY2023_Rx" SG_ 2611175611 PARSEDPhysCMRtoGWM_ECG 1;
BA_ "U_T6_MCA_MY2020_Tx" SG_ 2611175611 PARSEDPhysCMRtoGWM_ECG 1;
BA_ "U_CD542_MY2021_Tx" SG_ 2611175611 PARSEDPhysCMRtoGWM_ECG 1;
BA_ "U_U55X_MY2022_Tx" SG_ 2611175611 PARSEDPhysCMRtoGWM_ECG 1;
BA_ "U_CD764_MY2022_Tx" SG_ 2611175611 PARSEDPhysCMRtoGWM_ECG 1;
BA_ "U_CDX706_MY2023_Tx" SG_ 2611175611 PARSEDPhysCMRtoGWM_ECG 1;
BA_ "GenSigStartValueInteger" SG_ 1456 VDM_GWOnBoardTester 255;
BA_ "ContentDependant" SG_ 1456 VDM_GWOnBoardTester 1;
BA_ "GenSigStartValue" SG_ 1456 VDM_GWOnBoardTester 255;
BA_ "U_T6_MCA_MY2020_Tx" SG_ 1456 VDM_GWOnBoardTester 1;
BA_ "U_U55X_MY2022_Tx" SG_ 1456 VDM_GWOnBoardTester 1;
BA_ "GenSigStartValueInteger" SG_ 1456 VDM_GWNMProxy 255;
BA_ "ContentDependant" SG_ 1456 VDM_GWNMProxy 1;
BA_ "GenSigStartValue" SG_ 1456 VDM_GWNMProxy 255;
BA_ "U_T6_MCA_MY2020_Tx" SG_ 1456 VDM_GWNMProxy 1;
BA_ "U_U55X_MY2022_Tx" SG_ 1456 VDM_GWNMProxy 1;
BA_ "GenSigStartValueInteger" SG_ 1456 VDM_AutoSarNMReserved4 255;
BA_ "ContentDependant" SG_ 1456 VDM_AutoSarNMReserved4 1;
BA_ "GenSigStartValue" SG_ 1456 VDM_AutoSarNMReserved4 255;
BA_ "U_T6_MCA_MY2020_Tx" SG_ 1456 VDM_AutoSarNMReserved4 1;
BA_ "U_U55X_MY2022_Tx" SG_ 1456 VDM_AutoSarNMReserved4 1;
BA_ "GenSigStartValueInteger" SG_ 1456 VDM_AutoSarNMReserved3 255;
BA_ "ContentDependant" SG_ 1456 VDM_AutoSarNMReserved3 1;
BA_ "GenSigStartValue" SG_ 1456 VDM_AutoSarNMReserved3 255;
BA_ "U_T6_MCA_MY2020_Tx" SG_ 1456 VDM_AutoSarNMReserved3 1;
BA_ "U_U55X_MY2022_Tx" SG_ 1456 VDM_AutoSarNMReserved3 1;
BA_ "GenSigStartValueInteger" SG_ 1456 VDM_AutoSarNMReserved2 255;
BA_ "ContentDependant" SG_ 1456 VDM_AutoSarNMReserved2 1;
BA_ "GenSigStartValue" SG_ 1456 VDM_AutoSarNMReserved2 255;
BA_ "U_T6_MCA_MY2020_Tx" SG_ 1456 VDM_AutoSarNMReserved2 1;
BA_ "U_U55X_MY2022_Tx" SG_ 1456 VDM_AutoSarNMReserved2 1;
BA_ "GenSigStartValueInteger" SG_ 1456 VDM_AutoSarNMReserved1 255;
BA_ "ContentDependant" SG_ 1456 VDM_AutoSarNMReserved1 1;
BA_ "GenSigStartValue" SG_ 1456 VDM_AutoSarNMReserved1 255;
BA_ "U_T6_MCA_MY2020_Tx" SG_ 1456 VDM_AutoSarNMReserved1 1;
BA_ "U_U55X_MY2022_Tx" SG_ 1456 VDM_AutoSarNMReserved1 1;
BA_ "GenSigStartValueInteger" SG_ 1456 VDM_AutoSarNMNodeId 150;
BA_ "ContentDependant" SG_ 1456 VDM_AutoSarNMNodeId 1;
BA_ "GenSigStartValue" SG_ 1456 VDM_AutoSarNMNodeId 176;
BA_ "U_T6_MCA_MY2020_Tx" SG_ 1456 VDM_AutoSarNMNodeId 1;
BA_ "U_U55X_MY2022_Tx" SG_ 1456 VDM_AutoSarNMNodeId 1;
BA_ "ContentDependant" SG_ 1456 VDM_AutoSarNMControl 1;
BA_ "U_T6_MCA_MY2020_Tx" SG_ 1456 VDM_AutoSarNMControl 1;
BA_ "U_U55X_MY2022_Tx" SG_ 1456 VDM_AutoSarNMControl 1;
BA_ "GenSigSendType" SG_ 1782 TesterPhysicalReqLDCMA 3;
BA_ "GenSigSendType" SG_ 1791 TesterPhysicalResLDCMB 3;
BA_ "GenSigSendType" SG_ 1790 TesterPhysicalResLDCMA 3;
BA_ "GenSigSendType" SG_ 513 ChrgStat_D3_Dsply 3;
BA_ "WakeupSignal" SG_ 513 ChrgStat_D3_Dsply 1;
BA_ "GenSigSendType" SG_ 513 BptAllw_Pw_Dsply 3;
BA_ "GenSigStartValue" SG_ 513 BptAllw_Pw_Dsply 1022;
BA_ "ECGUsedRxSignal" SG_ 513 BptAllw_Pw_Dsply 1;
BA_ "U_CDX706_MY2023_Rx" SG_ 513 BptAllw_Pw_Dsply 1;
BA_ "GenSigSendType" SG_ 513 BptRngeRsrvMet_B_Stat 3;
BA_ "ECGUsedRxSignal" SG_ 513 BptRngeRsrvMet_B_Stat 1;
BA_ "U_CDX706_MY2023_Rx" SG_ 513 BptRngeRsrvMet_B_Stat 1;
BA_ "GenSigSendType" SG_ 513 BptPwOut_B_Dsply 3;
BA_ "ECGUsedRxSignal" SG_ 513 BptPwOut_B_Dsply 1;
BA_ "U_CDX706_MY2023_Rx" SG_ 513 BptPwOut_B_Dsply 1;
BA_ "GenSigSendType" SG_ 513 BptStrtStop_D_Stat 3;
BA_ "ECGUsedRxSignal" SG_ 513 BptStrtStop_D_Stat 1;
BA_ "U_CDX706_MY2023_Rx" SG_ 513 BptStrtStop_D_Stat 1;
BA_ "GenSigSendType" SG_ 513 BptComm_D_RqHtrn 3;
BA_ "ECGUsedRxSignal" SG_ 513 BptComm_D_RqHtrn 1;
BA_ "U_CDX706_MY2023_Rx" SG_ 513 BptComm_D_RqHtrn 1;
BA_ "GenSigSendType" SG_ 513 BptSustn_B_Rq 3;
BA_ "ECGUsedRxSignal" SG_ 513 BptSustn_B_Rq 1;
BA_ "U_CDX706_MY2023_Rx" SG_ 513 BptSustn_B_Rq 1;
BA_ "GenSigSendType" SG_ 513 GridSrvc01_B_Stat 3;
BA_ "ECGUsedRxSignal" SG_ 513 GridSrvc01_B_Stat 1;
BA_ "U_CDX706_MY2023_Rx" SG_ 513 GridSrvc01_B_Stat 1;
BA_ "GenSigSendType" SG_ 513 Bpt_D_StatHtrn 3;
BA_ "ECGUsedRxSignal" SG_ 513 Bpt_D_StatHtrn 1;
BA_ "U_CDX706_MY2023_Rx" SG_ 513 Bpt_D_StatHtrn 1;
BA_ "GenSigSendType" SG_ 513 BptMde_D_Stat 3;
BA_ "ECGUsedRxSignal" SG_ 513 BptMde_D_Stat 1;
BA_ "U_CDX706_MY2023_Rx" SG_ 513 BptMde_D_Stat 1;
BA_ "GenSigSendType" SG_ 513 BattTracTeColr_D_Dsply 3;
BA_ "U_CDX706_MY2023_Tx" SG_ 513 BattTracTeColr_D_Dsply 1;
BA_ "GenSigSendType" SG_ 513 MtrTracTeColr_D_Dsply 3;
BA_ "U_CDX706_MY2023_Tx" SG_ 513 MtrTracTeColr_D_Dsply 1;
BA_ "GenSigSendType" SG_ 513 MtrTracTe_Pc_Dsply 3;
BA_ "U_CDX706_MY2023_Tx" SG_ 513 MtrTracTe_Pc_Dsply 1;
BA_ "GenSigSendType" SG_ 513 BattTracTe_Pc_Dsply 3;
BA_ "U_CDX706_MY2023_Tx" SG_ 513 BattTracTe_Pc_Dsply 1;
BA_ "GenSigStartValue" SG_ 553 DistToChrgrBynd_L_Actl 510;
BA_ "U_T6_MCA_MY2020_Rx" SG_ 553 ResetTrip2_B_Rq 1;
BA_ "U_CD764_MY2022_Rx" SG_ 553 ResetTrip2_B_Rq 1;
BA_ "U_CDX706_MY2023_Rx" SG_ 553 ResetTrip2_B_Rq 1;
BA_ "U_T6_MCA_MY2020_Rx" SG_ 553 ResetTrip1_B_Rq 1;
BA_ "U_CD764_MY2022_Rx" SG_ 553 ResetTrip1_B_Rq 1;
BA_ "U_CDX706_MY2023_Rx" SG_ 553 ResetTrip1_B_Rq 1;
BA_ "GenSigStartValueInteger" SG_ 897 VehElAvgTrip2_Eff_Dsply 126;
BA_ "GenSigStartValue" SG_ 897 VehElAvgTrip2_Eff_Dsply 126;
BA_ "U_CDX706_MY2023_Tx" SG_ 897 VehElAvgTrip2_Eff_Dsply 1;
BA_ "GenSigStartValueInteger" SG_ 897 Trip2SumDrvE_Pc_Dsply 1022;
BA_ "GenSigStartValue" SG_ 897 Trip2SumDrvE_Pc_Dsply 1022;
BA_ "U_CDX706_MY2023_Tx" SG_ 897 Trip2SumDrvE_Pc_Dsply 1;
BA_ "GenSigStartValueInteger" SG_ 897 Trip2ExtFctrE_Pc_Dsply 1022;
BA_ "GenSigStartValue" SG_ 897 Trip2ExtFctrE_Pc_Dsply 1022;
BA_ "U_CDX706_MY2023_Tx" SG_ 897 Trip2ExtFctrE_Pc_Dsply 1;
BA_ "GenSigStartValueInteger" SG_ 897 Trip2ClimE_Pc_Dsply 1022;
BA_ "GenSigStartValue" SG_ 897 Trip2ClimE_Pc_Dsply 1022;
BA_ "U_CDX706_MY2023_Tx" SG_ 897 Trip2ClimE_Pc_Dsply 1;
BA_ "GenSigStartValueInteger" SG_ 897 Trip2BattULoE_Pc_Dsply 1022;
BA_ "GenSigStartValue" SG_ 897 Trip2BattULoE_Pc_Dsply 1022;
BA_ "U_CDX706_MY2023_Tx" SG_ 897 Trip2BattULoE_Pc_Dsply 1;
BA_ "U_T6_MCA_MY2020_Tx" SG_ 1688 UUDTAWDResponse1 1;
BA_ "GenSigSendType" SG_ 878 LowFuelDsplyType_B_Rq 3;
BA_ "GenSigSendType" SG_ 878 PwBedPnlEnblScnd_B_Rq 3;
BA_ "GenSigSendType" SG_ 878 DcacSysScnd_B_Falt 3;
BA_ "GenSigSendType" SG_ 878 DcacOnScnd_B_Rq 3;
BA_ "GenSigSendType" SG_ 878 DcacGfciTestScnd_B_Rq 3;
BA_ "GenSigSendType" SG_ 878 EngExhMdeHrStrt_D_Stat 3;
BA_ "U_T6_MCA_MY2020_Tx" SG_ 878 EngExhMdeHrStrt_D_Stat 1;
BA_ "GenSigSendType" SG_ 878 EngExhMdeHrEnd_D_Stat 3;
BA_ "U_T6_MCA_MY2020_Tx" SG_ 878 EngExhMdeHrEnd_D_Stat 1;
BA_ "GenSigSendType" SG_ 878 EngExhMdeHrEnbl_D_Stat 3;
BA_ "U_T6_MCA_MY2020_Tx" SG_ 878 EngExhMdeHrEnbl_D_Stat 1;
BA_ "GenSigSendType" SG_ 878 DcacGfciTest_B_Rq 3;
BA_ "U_CDX706_MY2023_Tx" SG_ 878 DcacGfciTest_B_Rq 1;
BA_ "ECGUsedRxSignal" SG_ 878 DcacOut_Pw_DsplyMx 1;
BA_ "U_CD542_MY2021_Rx" SG_ 878 DcacOut_Pw_DsplyMx 1;
BA_ "U_CDX706_MY2023_Tx" SG_ 878 DcacOut_Pw_DsplyMx 1;
BA_ "ECGUsedRxSignal" SG_ 878 DcacOut1_Pw_Dsply 1;
BA_ "U_CD542_MY2021_Rx" SG_ 878 DcacOut1_Pw_Dsply 1;
BA_ "U_CDX706_MY2023_Tx" SG_ 878 DcacOut1_Pw_Dsply 1;
BA_ "ECGUsedRxSignal" SG_ 878 DcacOut2_Pw_Dsply 1;
BA_ "U_CD542_MY2021_Rx" SG_ 878 DcacOut2_Pw_Dsply 1;
BA_ "U_CDX706_MY2023_Tx" SG_ 878 DcacOut2_Pw_Dsply 1;
BA_ "GenSigSendType" SG_ 878 DcacHw_D_Confg 3;
BA_ "GenSigStartValueInteger" SG_ 878 DcacHw_D_Confg 1;
BA_ "ECGUsedRxSignal" SG_ 878 DcacHw_D_Confg 1;
BA_ "U_CD542_MY2021_Rx" SG_ 878 DcacHw_D_Confg 1;
BA_ "U_CDX706_MY2023_Tx" SG_ 878 DcacHw_D_Confg 1;
BA_ "GenSigSendType" SG_ 878 DcacFaltMsgTxt_D_Rq 3;
BA_ "GenSigStartValueInteger" SG_ 878 DcacFaltMsgTxt_D_Rq 1;
BA_ "ECGUsedRxSignal" SG_ 878 DcacFaltMsgTxt_D_Rq 1;
BA_ "U_CD542_MY2021_Rx" SG_ 878 DcacFaltMsgTxt_D_Rq 1;
BA_ "U_CDX706_MY2023_Tx" SG_ 878 DcacFaltMsgTxt_D_Rq 1;
BA_ "GenSigSendType" SG_ 878 DcacLoFuelMsgTxt_D_Rq 3;
BA_ "ECGUsedRxSignal" SG_ 878 DcacLoFuelMsgTxt_D_Rq 1;
BA_ "U_CD542_MY2021_Rx" SG_ 878 DcacLoFuelMsgTxt_D_Rq 1;
BA_ "U_CDX706_MY2023_Tx" SG_ 878 DcacLoFuelMsgTxt_D_Rq 1;
BA_ "GenSigSendType" SG_ 878 DcacEngOnMsgTxt_D_Rq 3;
BA_ "ECGUsedRxSignal" SG_ 878 DcacEngOnMsgTxt_D_Rq 1;
BA_ "U_CD542_MY2021_Rx" SG_ 878 DcacEngOnMsgTxt_D_Rq 1;
BA_ "U_CDX706_MY2023_Tx" SG_ 878 DcacEngOnMsgTxt_D_Rq 1;
BA_ "GenSigSendType" SG_ 878 DcacElPw_D_Stat 3;
BA_ "GenSigStartValueInteger" SG_ 878 DcacElPw_D_Stat 1;
BA_ "GenSigStartValue" SG_ 878 DcacElPw_D_Stat 1;
BA_ "ECGUsedRxSignal" SG_ 878 DcacElPw_D_Stat 1;
BA_ "U_CD542_MY2021_Rx" SG_ 878 DcacElPw_D_Stat 1;
BA_ "U_CDX706_MY2023_Tx" SG_ 878 DcacElPw_D_Stat 1;
BA_ "GenSigSendType" SG_ 878 PwBedPnlEnbl_B_Rq 3;
BA_ "U_CDX706_MY2023_Tx" SG_ 878 PwBedPnlEnbl_B_Rq 1;
BA_ "GenSigSendType" SG_ 878 DcacOn_B_Rq 3;
BA_ "U_P702_MY2021_Tx" SG_ 878 DcacOn_B_Rq 1;
BA_ "U_CDX706_MY2023_Tx" SG_ 878 DcacOn_B_Rq 1;
BA_ "GenSigSendType" SG_ 878 DcacSys_B_Falt 3;
BA_ "U_P702_MY2021_Tx" SG_ 878 DcacSys_B_Falt 1;
BA_ "U_CDX706_MY2023_Tx" SG_ 878 DcacSys_B_Falt 1;
BA_ "GenSigSendType" SG_ 878 DcacLedCtl_D_Rq 3;
BA_ "U_P702_MY2021_Tx" SG_ 878 DcacLedCtl_D_Rq 1;
BA_ "U_CDX706_MY2023_Tx" SG_ 878 DcacLedCtl_D_Rq 1;
BA_ "GenSigStartValue" SG_ 924 DcacTrnkFrnt_I_Actl 65534;
BA_ "GenSigStartValue" SG_ 924 DcacOut_Pw_Mx 2046;
BA_ "U_P702_MY2021_Rx" SG_ 924 DcacOut_Pw_Mx 1;
BA_ "U_CDX706_MY2023_Rx" SG_ 924 DcacOut_Pw_Mx 1;
BA_ "GenSigStartValue" SG_ 924 DcacOut2_Pw_Actl 8190;
BA_ "U_P702_MY2021_Rx" SG_ 924 DcacOut2_Pw_Actl 1;
BA_ "U_CDX706_MY2023_Rx" SG_ 924 DcacOut2_Pw_Actl 1;
BA_ "GenSigStartValue" SG_ 924 DcacOut1_Pw_Actl 8190;
BA_ "U_P702_MY2021_Rx" SG_ 924 DcacOut1_Pw_Actl 1;
BA_ "U_CDX706_MY2023_Rx" SG_ 924 DcacOut1_Pw_Actl 1;
BA_ "GenSigStartValue" SG_ 924 DcacIn_Pw_Mx 2046;
BA_ "U_P702_MY2021_Rx" SG_ 924 DcacIn_Pw_Mx 1;
BA_ "U_CDX706_MY2023_Rx" SG_ 924 DcacIn_Pw_Mx 1;
BA_ "GenSigStartValue" SG_ 923 DcacIn_U3_Actl 4094;
BA_ "GenSigStartValue" SG_ 923 DcacIn_U2_Actl 4094;
BA_ "U_CDX706_MY2023_Rx" SG_ 923 DcacIn_U2_Actl 1;
BA_ "GenSigStartValueInteger" SG_ 923 DcacIn_U_Actl 4094;
BA_ "GenSigStartValue" SG_ 923 DcacIn_U_Actl 4094;
BA_ "U_P702_MY2021_Rx" SG_ 923 DcacIn_U_Actl 1;
BA_ "U_CDX706_MY2023_Rx" SG_ 923 DcacIn_U_Actl 1;
BA_ "GenSigStartValue" SG_ 923 DcacIn_I_Actl 2046;
BA_ "U_P702_MY2021_Rx" SG_ 923 DcacIn_I_Actl 1;
BA_ "U_CDX706_MY2023_Rx" SG_ 923 DcacIn_I_Actl 1;
BA_ "GenSigStartValue" SG_ 923 Dcac_Te_Actl 254;
BA_ "U_P702_MY2021_Rx" SG_ 923 Dcac_Te_Actl 1;
BA_ "U_CDX706_MY2023_Rx" SG_ 923 Dcac_Te_Actl 1;
BA_ "GenSigSendType" SG_ 1998 TesterPhysicalResSODR 3;
BA_ "U_T6_MCA_MY2020_Tx" SG_ 1998 TesterPhysicalResSODR 1;
BA_ "U_CD542_MY2021_Tx" SG_ 1998 TesterPhysicalResSODR 1;
BA_ "U_U55X_MY2022_Tx" SG_ 1998 TesterPhysicalResSODR 1;
BA_ "U_CD764_MY2022_Tx" SG_ 1998 TesterPhysicalResSODR 1;
BA_ "U_CDX706_MY2023_Tx" SG_ 1998 TesterPhysicalResSODR 1;
BA_ "GenSigSendType" SG_ 1990 TesterPhysicalReqSODR 3;
BA_ "U_T6_MCA_MY2020_Rx" SG_ 1990 TesterPhysicalReqSODR 1;
BA_ "U_CD542_MY2021_Rx" SG_ 1990 TesterPhysicalReqSODR 1;
BA_ "U_U55X_MY2022_Rx" SG_ 1990 TesterPhysicalReqSODR 1;
BA_ "U_CD764_MY2022_Rx" SG_ 1990 TesterPhysicalReqSODR 1;
BA_ "U_CDX706_MY2023_Rx" SG_ 1990 TesterPhysicalReqSODR 1;
BA_ "GenSigSendType" SG_ 1996 TesterPhysicalResSODL 3;
BA_ "U_T6_MCA_MY2020_Tx" SG_ 1996 TesterPhysicalResSODL 1;
BA_ "U_CD542_MY2021_Tx" SG_ 1996 TesterPhysicalResSODL 1;
BA_ "U_U55X_MY2022_Tx" SG_ 1996 TesterPhysicalResSODL 1;
BA_ "U_CD764_MY2022_Tx" SG_ 1996 TesterPhysicalResSODL 1;
BA_ "U_CDX706_MY2023_Tx" SG_ 1996 TesterPhysicalResSODL 1;
BA_ "GenSigSendType" SG_ 1988 TesterPhysicalReqSODL 3;
BA_ "U_T6_MCA_MY2020_Rx" SG_ 1988 TesterPhysicalReqSODL 1;
BA_ "U_CD542_MY2021_Rx" SG_ 1988 TesterPhysicalReqSODL 1;
BA_ "U_U55X_MY2022_Rx" SG_ 1988 TesterPhysicalReqSODL 1;
BA_ "U_CD764_MY2022_Rx" SG_ 1988 TesterPhysicalReqSODL 1;
BA_ "U_CDX706_MY2023_Rx" SG_ 1988 TesterPhysicalReqSODL 1;
BA_ "GenSigStartValue" SG_ 896 BptDly_T_Actl 62;
BA_ "GenSigStartValueInteger" SG_ 896 VehElAvgTrip1_Eff_Dsply 126;
BA_ "GenSigStartValue" SG_ 896 VehElAvgTrip1_Eff_Dsply 126;
BA_ "U_CDX706_MY2023_Tx" SG_ 896 VehElAvgTrip1_Eff_Dsply 1;
BA_ "GenSigStartValueInteger" SG_ 896 Trip1SumDrvE_Pc_Dsply 1022;
BA_ "GenSigStartValue" SG_ 896 Trip1SumDrvE_Pc_Dsply 1022;
BA_ "U_CDX706_MY2023_Tx" SG_ 896 Trip1SumDrvE_Pc_Dsply 1;
BA_ "GenSigStartValueInteger" SG_ 896 Trip1ExtFctrE_Pc_Dsply 1022;
BA_ "GenSigStartValue" SG_ 896 Trip1ExtFctrE_Pc_Dsply 1022;
BA_ "U_CDX706_MY2023_Tx" SG_ 896 Trip1ExtFctrE_Pc_Dsply 1;
BA_ "GenSigStartValueInteger" SG_ 896 Trip1ClimE_Pc_Dsply 1022;
BA_ "GenSigStartValue" SG_ 896 Trip1ClimE_Pc_Dsply 1022;
BA_ "U_CDX706_MY2023_Tx" SG_ 896 Trip1ClimE_Pc_Dsply 1;
BA_ "GenSigStartValueInteger" SG_ 896 Trip1BattULoE_Pc_Dsply 1022;
BA_ "GenSigStartValue" SG_ 896 Trip1BattULoE_Pc_Dsply 1022;
BA_ "U_CDX706_MY2023_Tx" SG_ 896 Trip1BattULoE_Pc_Dsply 1;
BA_ "U_CDX706_MY2023_Rx" SG_ 922 DcacOverTe_B_Falt 1;
BA_ "U_CDX706_MY2023_Rx" SG_ 922 DcacRdy_D2_Stat 1;
BA_ "U_CDX706_MY2023_Rx" SG_ 922 DcacOvrld_B_Falt 1;
BA_ "U_CDX706_MY2023_Rx" SG_ 922 DcacIpRcBrkrOpn_B_Falt 1;
BA_ "U_CDX706_MY2023_Rx" SG_ 922 DcacGfci_B_Falt 1;
BA_ "U_CDX706_MY2023_Rx" SG_ 922 DcacErr_B_Stat 1;
BA_ "U_CDX706_MY2023_Rx" SG_ 922 DcacBp2BrkrOpn_B_Falt 1;
BA_ "U_CDX706_MY2023_Rx" SG_ 922 DcacBp1BrkrOpn_B_Falt 1;
BA_ "U_CDX706_MY2023_Rx" SG_ 922 DcacAcUDetct_B_Falt 1;
BA_ "U_P702_MY2021_Rx" SG_ 922 DcacRdy_D_Stat 1;
BA_ "U_CDX706_MY2023_Rx" SG_ 922 DcacRdy_D_Stat 1;
BA_ "GenSigStartValueInteger" SG_ 922 DcacPlugPrsnt_B_Stat 1;
BA_ "U_P702_MY2021_Rx" SG_ 922 DcacPlugPrsnt_B_Stat 1;
BA_ "U_CDX706_MY2023_Rx" SG_ 922 DcacPlugPrsnt_B_Stat 1;
BA_ "U_CX727_MY2021_Rx" SG_ 922 DcacClntFlw_D_Rq 1;
BA_ "U_P702_MY2021_Rx" SG_ 922 DcacClntFlw_D_Rq 1;
VAL_ 1119 CoolFanDcdc_D_Rq 3 "High" 2 "Medium" 1 "Low" 0 "Off" ;
VAL_ 1119 DcdcClntFlw_D_Rq 3 "High" 2 "Medium" 1 "Low" 0 "Off" ;
VAL_ 1119 PwrSrcULo_Te_Actl 1023 "Faulty" 1022 "NoDataExists" ;
VAL_ 1119 PtLatchActv_B_RqDcdc 1 "On" 0 "Off" ;
VAL_ 912 GearPrkMtr_D_Stat 7 "NotUsed_1" 6 "FetLifeLimitReached" 5 "FetOpenCircuit" 4 "FetOutputShortToPower" 3 "FetOutputShortToGround" 2 "FetNotControlled" 1 "OnPowerToLoad" 0 "OffNoPowerToLoad" ;
VAL_ 912 GearPrkLck_D_Stat 7 "NotUsed_1" 6 "FetLifeLimitReached" 5 "FetOpenCircuit" 4 "FetOutputShortToPower" 3 "FetOutputShortToGround" 2 "FetNotControlled" 1 "OnPowerToLoad" 0 "OffNoPowerToLoad" ;
VAL_ 912 HeatCoreSovRear_D_Stat 7 "FetLowSideOpenOrShort" 6 "FetLifeLimitReached" 5 "FetOpenCircuit" 4 "FetOutputShortToPower" 3 "FetOutputShortToGround" 2 "FetNotControlled" 1 "OnPowerToLoad" 0 "OffNoPowerToLoad" ;
VAL_ 912 CabnEvapSovRear_D_Stat 7 "NotUsed_1" 6 "FetLifeLimitReached" 5 "FetOpenCircuit" 4 "FetOutputShortToPower" 3 "FetOutputShortToGround" 2 "FetNotControlled" 1 "OnPowerToLoad" 0 "OffNoPowerToLoad" ;
VAL_ 912 CabnEvapSovFront_D_Stat 7 "NotUsed_1" 6 "FetLifeLimitReached" 5 "FetOpenCircuit" 4 "FetOutputShortToPower" 3 "FetOutputShortToGround" 2 "FetNotControlled" 1 "OnPowerToLoad" 0 "OffNoPowerToLoad" ;
VAL_ 912 BattTracSov_D_Stat 7 "NotUsed_1" 6 "FetLifeLimitReached" 5 "FetOpenCircuit" 4 "FetOutputShortToPower" 3 "FetOutputShortToGround" 2 "FetNotControlled" 1 "OnPowerToLoad" 0 "OffNoPowerToLoad" ;
VAL_ 912 BattChlrSov_D_Stat 7 "NotUsed_1" 6 "FetLifeLimitReached" 5 "FetOpenCircuit" 4 "FetOutputShortToPower" 3 "FetOutputShortToGround" 2 "FetNotControlled" 1 "OnPowerToLoad" 0 "OffNoPowerToLoad" ;
VAL_ 912 BattTracClntVlv_D_Stat 7 "FetLowSideOpenOrShort" 6 "FetLifeLimitReached" 5 "FetOpenCircuit" 4 "FetOutputShortToPower" 3 "FetOutputShortToGround" 2 "FetNotControlled" 1 "OnPowerToLoad" 0 "OffNoPowerToLoad" ;
VAL_ 912 AdasRelay_B_Stat 1 "On" 0 "Off" ;
VAL_ 66 immoControlCmd_T2 0 "IDLE" 1 "MOTIVE_START_RQST" 2 "NONMOTIVE_START_RQST" 3 "RQST_TARGET2_IDBLOCK1" 4 "RQST_TARGET2_IDBLOCK2" 5 "LIMITEDMOTIVE_START_RQST" 6 "ECHO_TARGET2_IDBLOCK2" 7 "SHUTDOWN" ;
VAL_ 651 TelematicsSrvc_D_St 7 "NotUsed" 6 "NotifyNotActivatedYet" 5 "NotActivatedYet" 4 "NotifyExpired" 3 "Expired" 2 "ExpiringSoon" 1 "Active" 0 "Null" ;
VAL_ 651 EmgcyCallMute_D_Stat 7 "NotUsed4" 6 "NotUsed3" 5 "NotUsed2" 4 "NotUsed1" 3 "ManualEmergencyCallMute" 2 "AutomaticEmergencyCallMute" 1 "EmergencyCallUnmute" 0 "Null" ;
VAL_ 1097 EvseChrg2_U_Mx 4095 "Faulty" 4094 "NoDataExists" ;
VAL_ 1097 EvseChrg2_U_Mn 4095 "Faulty" 4094 "NoDataExists" ;
VAL_ 1097 EvseChrg2_I_Mx 32767 "Faulty" 32766 "NoDataExists" ;
VAL_ 1097 EvseChrg2_I_Mn 32767 "Faulty" 32766 "NoDataExists" ;
VAL_ 607 EvseDcChrgIso_D_Stat 7 "Faulty" 6 "NoDataExists" 5 "NotUsed_3" 4 "NotUsed_2" 3 "NotUsed_1" 2 "Valid" 1 "Warning" 0 "Invalid" ;
VAL_ 607 BattTracIsoDis_B_Rq 1 "Yes" 0 "No" ;
VAL_ 607 DcChrgRdy_D_Stat 15 "Faulty" 14 "NotUsed_4" 13 "NotUsed_3" 12 "NotUsed_2" 11 "CableCheck" 10 "EvseFault" 9 "EvseNotCompatible" 8 "EvsePaused" 7 "GbtPrecharge" 6 "ChargeComplete" 5 "Charging" 4 "Precharge" 3 "WeldCheck" 2 "ChargeReady" 1 "Initialization" 0 "NotReady" ;
VAL_ 607 DcChrgSrvcRqd_B_Rq 1 "On" 0 "Off" ;
VAL_ 607 DcChrgWarnLamp_B_Rq 1 "On" 0 "Off" ;
VAL_ 607 DgtlCommGtwyMde_D_Stat 11 "NotUsed_3" 10 "DgtlCommFailed" 9 "DgtlCommEstablished" 8 "Inactive" 7 "RestartRequest" 6 "AcPnc_Eim" 5 "AcPnc" 4 "AcEim" 3 "DcPnc_Eim" 2 "DcPnc" 1 "DcEim" 0 "NotDetected" 15 "NotUsed_7" 14 "NotUsed_6" 13 "NotUsed_5" 12 "NotUsed_4" ;
VAL_ 607 EvseChrgIso_D_Stat 3 "Faulty" 2 "Warning" 1 "Valid" 0 "Invalid" ;
VAL_ 607 EvseChrg2_Pw_Mx 32767 "Faulty" 32766 "NoDataExists" ;
VAL_ 607 DgtlCommPnc_D_Stat 7 "Faulty" 6 "NotUsed_3" 5 "NotUsed_2" 4 "NotUsed_1" 3 "Enable" 2 "Disable" 1 "NoContractsInstalled" 0 "Null" ;
VAL_ 607 DgtlCommGtwy_D_Falt 127 "NotUsed_63" 65 "NotUsed_1" 64 "EvseGbtCommTimeout" 63 "EvseGbtCrgVoltMismatch" 62 "EvseGbtChrgCurrntMismatch" 61 "EvseGbtOtherFalt" 60 "EvseGbtEmergShutdown" 59 "EvseGbtEnergyTransFalt" 58 "EvseGbtIntOverTemp" 57 "EvseGbtConnectorFalt" 56 "EvseGbtOverTemp" 55 "EvseResCpsRootCaCertRev" 54 "EvseResSubCA2CertRev" 53 "EvseResSubCA1CertRev" 52 "EvseResCpsProvCertRev" 51 "EvseResRootCaCertRev" 50 "EvseResMoSubCa2CertRev" 49 "EvseResMoSubCa1CertRev" 48 "EvseResMoProvCertRev" 47 "EvseResOemSubCa2CertRev" 46 "EvseResOemSubCa1CertRev" 45 "EvseResOemProvCertRev" 44 "EvseResMoUnknown" 43 "EvseResContractNotAccept" 42 "EvseResNoSuppAppProt" 41 "EvseResCertNotAllowed" 40 "EvseResContractErr" 39 "EvseResNoChrgSvcSelect" 38 "EvseResMeterSignNotVld" 37 "EvseResPwrDelNotApplied" 36 "EvseResTrfSelectInvld" 35 "EvseResChrgProfileInvld" 34 "EvseResWrongChrgParam" 33 "EvseResWrongEnrgyTransMde" 32 "EvseResChlgInvld" 31 "EvseResContractCancel" 30 "EvseResCertChainErr" 29 "EvseResNoCertAvail" 28 "EvseResCertRvk" 27 "EvseResCertExp" 26 "EvseResPymtSelectInvld" 25 "EvseResSvcldInvld" 24 "EvseResUnknownSession" 23 "EvseResSignErr" 22 "EvseResSeqErr" 21 "EvseResFailed" 20 "EvsePreChrgTimeout" 19 "EvseCableCheckTimeout" 18 "EvseCommSetupTimeout" 17 "EvseMsgTimeout" 16 "EvseTlsUnknownCA" 15 "EvseTlsCertExpired" 14 "EvseTlsBadCert" 13 "EvseTlsHandshakeFail" 12 "EvseTlsDecryptFail" 11 "EvseTlsBadRecordMac" 10 "EvseTlsUnexpectedMsg" 9 "EvseTlsFail" 8 "EvseTcpCnnctFail" 7 "EvseUpdErr" 6 "EvseSlaacErr" 5 "EvseStopNotification" 4 "EvseMalfunction" 3 "EvseEmergShutdown" 2 "EvseStatUtilityIntrpt" 1 "EvseStatShutdown" 0 "NoFault" ;
VAL_ 1082 SelDrvMdeStabBar_D_Stat 3 "Faulty" 2 "TemporarilyNotAvailable" 1 "Available" 0 "NotAvailable" ;
VAL_ 1082 StabBarFaltMsgTxt_D_Rq 3 "Message3" 2 "Message2" 1 "Message1" 0 "NoMessage" ;
VAL_ 1082 StabBarCnnctLamp_D_Rq 3 "Fast_Flash" 2 "Slow_Flash" 1 "On" 0 "Off" ;
VAL_ 1082 StabBarCnnct_D_Stat 15 "Faulty" 14 "NotUsed_7" 13 "NotUsed_6" 12 "NotUsed_5" 11 "NotUsed_4" 10 "NotUsed_3" 9 "NotUsed_2" 8 "NotUsed_1" 7 "SbdFailure2" 6 "SbdFailure1" 5 "Shutdown" 4 "NormalClosing" 3 "NormalOpen" 2 "NormalOpening" 1 "NormalClosed" 0 "Initialize" ;
VAL_ 1082 StabBarCnncMsgTxt_D_Rq 15 "Message15" 14 "Message14" 13 "Message13" 12 "Message12" 11 "Message11" 10 "Message10" 9 "Message9" 8 "Message8" 7 "Message7" 6 "Message6" 5 "Message5" 4 "Message4" 3 "Message3" 2 "Message2" 1 "Message1" 0 "NoMessage" ;
VAL_ 529 OnbChrgToPcWknd_D_Actl 7 "Percent_50" 6 "Percent_60" 5 "Percent_70" 4 "Percent_80" 3 "Percent_85" 2 "Percent_90" 1 "Percent_95" 0 "Percent_100" ;
VAL_ 529 OnbChrgToPcWkdy_D_Actl 7 "Percent_50" 6 "Percent_60" 5 "Percent_70" 4 "Percent_80" 3 "Percent_85" 2 "Percent_90" 1 "Percent_95" 0 "Percent_100" ;
VAL_ 529 OnbChrgSetNow_D_Rq 3 "NotUsed" 2 "On" 1 "Off" 0 "Null" ;
VAL_ 529 OnbChrgSetDelete_B_Rq 1 "Request" 0 "NoRequest" ;
VAL_ 529 OnbChrgPrflUpdate_B_Rq 1 "Request" 0 "NoRequest" ;
VAL_ 529 OnbChrgLocIdUns_B_Rq 1 "Request" 0 "NoRequest" ;
VAL_ 1143 ConsTipUnitPt_D_Dsply 3 "NotUsed" 2 "FuelEconomy" 1 "Distance" 0 "Percentage" ;
VAL_ 1143 ConsTipTot_Pc_Dsply 1023 "Faulty" 1022 "NoDataExists" ;
VAL_ 1143 ChrgCompltMsgTxt_D_Rq 3 "NotUsed_1" 2 "ChargeToFull" 1 "ChargeToFastChargeLimit" 0 "DefaultLabel" ;
VAL_ 1142 ConsTipV_No_Dsply 1023 "Faulty" 1022 "NoDataExists" ;
VAL_ 1142 ConsTipMsg3_D_Dsply 15 "NotUsed10" 14 "NotUsed9" 13 "NotUsed8" 12 "NotUsed7" 11 "NotUsed6" 10 "NotUsed5" 9 "NotUsed4" 8 "NotUsed3" 7 "NotUsed2" 6 "NotUsed1" 5 "ReduceIdleTime" 4 "ClimateUsage" 3 "VehicleSpeed" 2 "Deceleration" 1 "Acceleration" 0 "NoDisplay" ;
VAL_ 1142 ConsTipMsg2_D_Dsply 15 "NotUsed10" 14 "NotUsed9" 13 "NotUsed8" 12 "NotUsed7" 11 "NotUsed6" 10 "NotUsed5" 9 "NotUsed4" 8 "NotUsed3" 7 "NotUsed2" 6 "NotUsed1" 5 "ReduceIdleTime" 4 "ClimateUsage" 3 "VehicleSpeed" 2 "Deceleration" 1 "Acceleration" 0 "NoDisplay" ;
VAL_ 1142 ConsTipMsg1_D_Dsply 15 "NotUsed10" 14 "NotUsed9" 13 "NotUsed8" 12 "NotUsed7" 11 "NotUsed6" 10 "NotUsed5" 9 "NotUsed4" 8 "NotUsed3" 7 "NotUsed2" 6 "NotUsed1" 5 "ReduceIdleTime" 4 "ClimateUsage" 3 "VehicleSpeed" 2 "Deceleration" 1 "Acceleration" 0 "NoDisplay" ;
VAL_ 1142 ConsTipDecel_No_Dsply 1023 "Faulty" 1022 "NoDataExists" ;
VAL_ 1142 ConsTipA_No_Dsply 1023 "Faulty" 1022 "NoDataExists" ;
VAL_ 1141 AirAmbTePlgIn_D_Dsply 3 "NotUsed" 2 "Hot_Outside_Plg_In_Msg" 1 "Cold_Outside_Plg_In_Msg" 0 "No_Plg_In_Msg" ;
VAL_ 1141 OfbChrgSetSync_D_Stat 3 "Fail" 2 "Success" 1 "InProgress" 0 "NoSyncInProgress" ;
VAL_ 1141 PtRmtRprt_D_Rq 15 "NotUsed_4" 14 "NotUsed_3" 13 "NotUsed_2" 12 "PlugInToMaintain12vBattery" 11 "SettingUpdated" 10 "FastChargeComplete" 9 "ChargeNotOccurring" 8 "OneTimeSocReached" 7 "BatteryTemperatureReminder" 6 "ReducedPerformance" 5 "LimitedPerformance" 4 "ChargeFault" 3 "ChargeComplete" 2 "VehiclePreconditioned" 1 "TripDistanceAchieved" 0 "NoReportRequest" ;
VAL_ 1141 NxtUsg_D_Rq 0 "Invalid" 1 "Not_Requested" 2 "Requested" 3 "NotUsed" ;
VAL_ 1141 NtfctnConflict1_D_Rq 7 "NotUsed_4" 6 "NotUsed_3" 5 "NotUsed_2" 4 "NotUsed_1" 3 "ChargeWindow" 2 "DepartureTime" 1 "NoConflictExists" 0 "Null" ;
VAL_ 1141 ChrgLocGPS_D_Rq 0 "Inactive" 1 "Not_Requested" 2 "Requested" 3 "NotUsed" ;
VAL_ 1140 RgenLongTerm_L_Dsply 16777215 "Faulty" 16777214 "NoDataExists" ;
VAL_ 1140 PreCondStat_D_Dsply 7 "Reserved3" 6 "Reserved2" 5 "Reserved1" 4 "Faulted" 3 "Complete" 2 "In_Progress" 1 "Scheduled" 0 "Not_Scheduled" ;
VAL_ 1140 RgenEvntLvl_Pc_Dsply 1023 "Fault" 1022 "NoDataExists" ;
VAL_ 1140 BrkEvntComplt_B_Dsply 1 "On" 0 "Off" ;
VAL_ 1140 ExtChrgrFalt_B_Dsply 1 "Yes" 0 "No" ;
VAL_ 1140 BattTracPw_Pc_Avail 255 "Faulty" 254 "NoDataExists" ;
VAL_ 1139 BattChrgTrgtLMax_T_Est 2047 "Faulty" 2046 "NoDataExists" ;
VAL_ 1139 ActChrgStrtYr_No_Actl 31 "Invalid" ;
VAL_ 1139 ActChrgStrtMin_No_Actl 63 "Invalid" 62 "Unknown" ;
VAL_ 1139 ActChrgStrtHr_No_Actl 31 "Invalid" 30 "Unknown" ;
VAL_ 1139 ActChrgStrtDay_No_Actl 31 "Invalid" ;
VAL_ 1139 ActChrgStrMnth_No_Actl 15 "Invalid" ;
VAL_ 1138 BattChrgTrgtLMin_T_Est 2047 "Faulty" 2046 "NoDataExists" ;
VAL_ 1138 ActChrgEndYr_No_Actl 31 "Invalid" ;
VAL_ 1138 ActChrgEndMnth_No_Actl 15 "Invalid" ;
VAL_ 1138 ActChrgEndMin_No_Actl 63 "Invalid" 62 "Unknown" ;
VAL_ 1138 ActChrgEndHr_No_Actl 31 "Invalid" 30 "Unknown" ;
VAL_ 1138 ActChrgEndDay_No_Actl 31 "Invalid" ;
VAL_ 1016 ChrgGoTElement_B_Dsply 1 "Yes" 0 "No" ;
VAL_ 1016 ChrgGoTTouchEnbl_B_Rq 1 "Request" 0 "NoRequest" ;
VAL_ 1016 ChrgGoTTouch_B_Stat 1 "On" 0 "Off" ;
VAL_ 1016 ChrgGoTPrcond_D_Stat 3 "High" 2 "Medium" 1 "Low" 0 "Off" ;
VAL_ 1016 ChrgGoTMnte_D_Stat 15 "NotUsed_4" 14 "NotUsed_3" 13 "NotUsed_2" 12 "NotUsed_1" 11 "Minute_55" 10 "Minute_50" 9 "Minute_45" 8 "Minute_40" 7 "Minute_35" 6 "Minute_30" 5 "Minute_25" 4 "Minute_20" 3 "Minute_15" 2 "Minute_10" 1 "Minute_5" 0 "Minute_0" ;
VAL_ 1016 ChrgGoTHr_T_Stat 31 "Faulty" 30 "NoDataExists" ;
VAL_ 1016 ChrgGoTExtHtrEnbl_B_Rq 1 "Request" 0 "NoRequest" ;
VAL_ 1016 ChrgGoTExtHtr_B_Stat 1 "On" 0 "Off" ;
VAL_ 1016 ChrgGoTAllOn_B_Stat 1 "On" 0 "Off" ;
VAL_ 1013 ChrgToPcWkndSav_D_Stat 7 "Percent_50" 6 "Percent_60" 5 "Percent_70" 4 "Percent_80" 3 "Percent_85" 2 "Percent_90" 1 "Percent_95" 0 "Percent_100" ;
VAL_ 1013 ChrgToPcWkdySav_D_Stat 7 "Percent_50" 6 "Percent_60" 5 "Percent_70" 4 "Percent_80" 3 "Percent_85" 2 "Percent_90" 1 "Percent_95" 0 "Percent_100" ;
VAL_ 1013 ChrgNowEnbl_B_Saved 1 "On" 0 "Off" ;
VAL_ 1013 ChrgLocIdUnsAck_B_Stat 1 "Yes" 0 "No" ;
VAL_ 1012 AirCondRec_B_RqVehEl 1 "Yes" 0 "No" ;
VAL_ 1012 ChrgLocSaved_B_Dsply 1 "Yes" 0 "No" ;
VAL_ 1012 ChrgLocLongPostv_B_Sav 1 "Yes" 0 "No" ;
VAL_ 1012 ChrgLocLattPostv_B_Sav 1 "Yes" 0 "No" ;
VAL_ 1012 ChrgNowCurnt_B_Dsply 1 "On" 0 "Off" ;
VAL_ 1011 VehShutDownMsgTxt_D_Rq 3 "NotUsed" 2 "ProhibitedRestart" 1 "ShutdownWarning" 0 "NoMessage" ;
VAL_ 1011 ChrgLocLongPostv_B_Uns 1 "Yes" 0 "No" ;
VAL_ 1011 ChrgLocLattPostv_B_Uns 1 "Yes" 0 "No" ;
VAL_ 1049 DcacZone3PwBttn_B_Stat 1 "Pressed" 0 "Not_Pressed" ;
VAL_ 1049 DcacZone2PwBttn_B_Stat 1 "Pressed" 0 "Not_Pressed" ;
VAL_ 1049 DcacPwResetBtn2_B_Stat 1 "Pressed" 0 "Not_Pressed" ;
VAL_ 1049 DcacPwOffButtn2_B_Stat 1 "Pressed" 0 "Not_Pressed" ;
VAL_ 1049 DcacPwHiButtn2_B_Stat 1 "Pressed" 0 "Not_Pressed" ;
VAL_ 1049 DcacGfciTestBtn2_B_Stat 1 "Pressed" 0 "Not_Pressed" ;
VAL_ 1049 DcacAllZoneBttn_B_Stat 1 "Pressed" 0 "Not_Pressed" ;
VAL_ 1049 DcacChime_D_Rq 3 "NotUsed" 2 "SoftChime" 1 "InformationChime" 0 "NoChime" ;
VAL_ 1049 Fba_D_Rq 3 "NotUsed" 2 "On" 1 "Off" 0 "Null" ;
VAL_ 1049 ExtLghtAnmtn_D_Rq 15 "Faulty" 14 "NotUsed_8" 13 "NotUsed_7" 12 "NotUsed_6" 11 "NotUsed_5" 10 "NotUsed_4" 9 "NotUsed_3" 8 "NotUsed_2" 7 "NotUsed_1" 6 "Type6" 5 "Type5" 4 "Type4" 3 "Type3" 2 "Type2" 1 "Type1" 0 "Null" ;
VAL_ 1049 Chrgr_Pw_EstMx 511 "Faulty" 510 "NoDataExists" ;
VAL_ 1049 LnchCtl_D_Rq2 3 "NotUsed2" 2 "NotUsed1" 1 "LC_On" 0 "LC_Off" ;
VAL_ 1049 PersTurnSglView_D_RqMnu 3 "NotUsed" 2 "Enable" 1 "Disable" 0 "Null" ;
VAL_ 1049 FrontDiffLck_D_RqDrv3 3 "Faulty" 2 "NoRequest" 1 "On" 0 "Off" ;
VAL_ 1049 RearDiffLck_D_RqDrv3 3 "Faulty" 2 "NoRequest" 1 "On" 0 "Off" ;
VAL_ 1049 TrailCtlSwtch_B_Stat4 1 "Pressed" 0 "Not_Pressed" ;
VAL_ 1049 CamraFrnt_B_RqMnu 1 "On" 0 "Off" ;
VAL_ 1049 StabBarCnncButtn_D_Sta3 3 "Faulty" 2 "NotUsed" 1 "Pressed" 0 "Not_Pressed" ;
VAL_ 1049 TurnAsstSwtch_D_Stat 3 "Faulty" 2 "NotUsed" 1 "Pressed" 0 "Not_Pressed" ;
VAL_ 1049 SelDrvMdeTxtRst_B_Rq2 1 "Yes" 0 "No" ;
VAL_ 1049 SelDrvMdePage_B_Stat 1 "Active" 0 "Inactive" ;
VAL_ 1049 SelDrvMdeCnfm_D_Stat2 3 "NotUsed" 2 "Accepted" 1 "NotAccepted" 0 "Null" ;
VAL_ 1049 SelDrvMde_D_RqDrv 31 "Faulty" 30 "SelDrvMde31" 29 "SelDrvMde30" 28 "SelDrvMde29" 27 "SelDrvMde28" 26 "SelDrvMde27" 25 "SelDrvMde26" 24 "SelDrvMde25" 23 "SelDrvMde24" 22 "SelDrvMde23" 21 "SelDrvMde22" 20 "SelDrvMde21" 19 "SelDrvMde20" 18 "SelDrvMde19" 17 "SelDrvMde18" 16 "SelDrvMde17" 15 "SelDrvMde16" 14 "SelDrvMde15" 13 "SelDrvMde14" 12 "SelDrvMde13" 11 "SelDrvMde12" 10 "SelDrvMde11" 9 "SelDrvMde10" 8 "SelDrvMde09" 7 "SelDrvMde08" 6 "SelDrvMde07" 5 "SelDrvMde06" 4 "SelDrvMde05" 3 "SelDrvMde04" 2 "SelDrvMde03" 1 "SelDrvMde02" 0 "SelDrvMde01" ;
VAL_ 72 immoTarget2Status 7 "Unused4" 6 "Unused3" 5 "Unused2" 4 "ENABLED_LIMITEDMOTIVE_STAR" 3 "DISABLED_RESET   " 2 "ENABLED_NONMOTIVE_START" 1 "ENABLED_MOTIVE_START" 0 "DISABLED" ;
VAL_ 72 immoTarget2Cmd 7 "Unused4" 6 "Unused3" 5 "Unused2" 4 "Unused1" 3 "TARGET1_IDBLOCK2" 2 "TARGET1_IDBLOCK1" 1 "CHALLENGE" 0 "IDLE" ;
VAL_ 775 ScDayOfWeekId_D_RqCld 7 "Sunday" 6 "Saturday" 5 "Friday" 4 "Thursday" 3 "Wednesday" 2 "Tuesday" 1 "Monday" 0 "NotUsed" ;
VAL_ 775 ScChrgDurSet_D_RqCld 3 "NotUsed" 2 "On" 1 "Off" 0 "Null" ;
VAL_ 775 ScChrgDur_T_RqCld 2047 "Faulty" 2046 "NoDataExists" ;
VAL_ 774 ScLocLongPostv_B_RqCld 1 "Yes" 0 "No" ;
VAL_ 774 ScLocLattPostv_B_RqCld 1 "Yes" 0 "No" ;
VAL_ 774 ScLocDelete_B_RqCld 1 "Request" 0 "NoRequest" ;
VAL_ 943 VehVActlAdas_D_Qf 3 "OK" 2 "Not_Within_Specifications" 1 "No_Data_Exists" 0 "Faulty" ;
VAL_ 943 AdasLcDistToObj_L_Actl 4095 "Faulty" 4094 "NoDataExists" ;
VAL_ 930 BalrWndwRight_B_Stat 1 "Enable" 0 "Disable" ;
VAL_ 930 BalrSnsRight_D_Falt 3 "Invalid" 2 "SystemFailure" 1 "Blocked" 0 "Clear" ;
VAL_ 930 WndwPsngrRear_D_RqBalrr 3 "NotUsed" 2 "Stop" 1 "AutoUp" 0 "NoRequest" ;
VAL_ 930 WndwPsngr_D_RqBalrr 3 "NotUsed" 2 "Stop" 1 "AutoUp" 0 "NoRequest" ;
VAL_ 930 WndwDrvRear_D_RqBalrr 3 "NotUsed" 2 "Stop" 1 "AutoUp" 0 "NoRequest" ;
VAL_ 930 WndwDrv_D_RqBalrr 3 "NotUsed" 2 "Stop" 1 "AutoUp" 0 "NoRequest" ;
VAL_ 930 BalrRight_D_Stat 3 "Inhibited" 2 "Disabled" 1 "On" 0 "Off" ;
VAL_ 930 BalrMdeSelRight_B_Stat 1 "Enable" 0 "Disable" ;
VAL_ 930 BalrMdeRight_D_Stat 3 "NotUsed" 2 "High" 1 "Medium" 0 "Low" ;
VAL_ 930 BalrLckRight_B_Stat 1 "Enable" 0 "Disable" ;
VAL_ 930 BalrChimeRight_D_Rq 3 "NotUsed" 2 "Soft" 1 "Normal" 0 "Off" ;
VAL_ 930 CamraRearOn_B_RqBalrr 1 "Active" 0 "Inactive" ;
VAL_ 930 DrLckActv_B_RqBalrr 1 "Active" 0 "Null" ;
VAL_ 929 BalrChimeLeft_D_Rq 3 "NotUsed" 2 "Soft" 1 "Normal" 0 "Off" ;
VAL_ 929 BalrLeft_D_Stat 3 "Inhibited" 2 "Disabled" 1 "On" 0 "Off" ;
VAL_ 929 WndwPsngrRear_D_RqBalrl 3 "NotUsed" 2 "Stop" 1 "AutoUp" 0 "NoRequest" ;
VAL_ 929 WndwPsngr_D_RqBalrl 3 "NotUsed" 2 "Stop" 1 "AutoUp" 0 "NoRequest" ;
VAL_ 929 WndwDrvRear_D_RqBalrl 3 "NotUsed" 2 "Stop" 1 "AutoUp" 0 "NoRequest" ;
VAL_ 929 WndwDrv_D_RqBalrl 3 "NotUsed" 2 "Stop" 1 "AutoUp" 0 "NoRequest" ;
VAL_ 929 BalrSnsLeft_D_Falt 3 "Invalid" 2 "SystemFailure" 1 "Blocked" 0 "Clear" ;
VAL_ 929 BalrMdeSelLeft_B_Stat 1 "Enable" 0 "Disable" ;
VAL_ 929 BalrMdeLeft_D_Stat 3 "NotUsed" 2 "High" 1 "Medium" 0 "Low" ;
VAL_ 929 BalrLckLeft_B_Stat 1 "Enable" 0 "Disable" ;
VAL_ 929 CamraRearOn_B_RqBalrl 1 "Active" 0 "Inactive" ;
VAL_ 929 DrLckActv_B_RqBalrl 1 "Active" 0 "Null" ;
VAL_ 929 BalrWndwLeft_B_Stat 1 "Enable" 0 "Disable" ;
VAL_ 867 BattRgenLoBalnc_B_Rq 1 "Yes" 0 "No" ;
VAL_ 867 BattRgenLo_Te_Actl 255 "Fault" ;
VAL_ 865 BattRgenLo_U_Actl 2047 "Faulty" ;
VAL_ 865 BattRgenLo_I_Actl 65535 "Faulty" ;
VAL_ 402 ApaSlotAlrtSet_D_RqDrv 3 "TemporarySuppression" 2 "Disable" 1 "Enable" 0 "None" ;
VAL_ 402 ApaFeat_D_RqDrv 7 "Faulty" 6 "Off" 5 "RePA" 4 "ParkIn" 3 "POA" 2 "PPA" 1 "SAPP" 0 "Inactive" ;
VAL_ 402 ApaSlotTrgt_D_RqDrv 15 "NotUsed_7" 14 "NotUsed_6" 13 "NotUsed_5" 12 "NotUsed_4" 11 "NotUsed_3" 10 "NotUsed_2" 9 "NotUsed_1" 8 "Front" 7 "Rear" 6 "Right3" 5 "Right2" 4 "Right1" 3 "Left3" 2 "Left2" 1 "Left1" 0 "None" ;
VAL_ 402 ApaFeatChange_B_RqDrv 1 "True" 0 "False" ;
VAL_ 402 CamraFrntBttn_D_Stat3 1 "Pressed" 0 "Not_Pressed" ;
VAL_ 402 PrkAidSwtch_D_RqMnu 1 "Pressed" 0 "Not_Pressed" ;
VAL_ 402 ApaSwtch_D_RqMnu 3 "NotUsed2" 2 "NotUsed1" 1 "Pressed" 0 "Not_Pressed" ;
VAL_ 402 ApaMdeStat_D_RqDrv 7 "Faulty" 6 "Off" 5 "NotUsed2" 4 "NotUsed1" 3 "POA" 2 "PPA" 1 "SAPP" 0 "Inactive" ;
VAL_ 402 CamraViewSplit_B_Rq 1 "On" 0 "Off" ;
VAL_ 402 CamraZoomMan_D_Rq 7 "Unknown" 6 "Invalid" 5 "Zoom_Level_V" 4 "Zoom_Level_IV" 3 "Zoom_Level_III" 2 "Zoom_Level_II" 1 "Zoom_Level_I" 0 "Off" ;
VAL_ 402 CamraOvrlStat_D_Rq 1 "On" 0 "Off" ;
VAL_ 402 CamraOvrlDyn_D_Rq 1 "On" 0 "Off" ;
VAL_ 402 CamAutoTowbarZoom 1 "On" 0 "Off" ;
VAL_ 402 DistanceBarSetting 1 "On" 0 "Off" ;
VAL_ 513 ChrgStat_D3_Dsply 31 "NotUsed_13" 30 "NotUsed_12" 29 "NotUsed_11" 28 "NotUsed_10" 27 "NotUsed_9" 26 "NotUsed_8" 25 "NotUsed_7" 24 "NotUsed_6" 23 "NotUsed_5" 22 "NotUsed_4" 21 "NotUsed_3" 20 "NotUsed_2" 19 "NotUsed_1" 18 "Discharging" 17 "GridChargeStopCommanded" 16 "GridChargeStartCommanded" 15 "ChargeStopCommanded" 14 "ChargeStartCommanded" 13 "ChargeTargetReached" 12 "DriveConditioning" 11 "CabinPreconditioning" 10 "ChargingSystemMaintain" 9 "ChargingInductive" 8 "ChargingDCFastCharge" 7 "ChargingAC" 6 "ChargeScheduled" 5 "EvsePaused" 4 "EvseNotDetected" 3 "EvseNotCompatible" 2 "FaultOutsideCar" 1 "FaultInsideCar" 0 "NotReady" ;
VAL_ 513 BptAllw_Pw_Dsply 1023 "Fault" 1022 "NoDataExists" ;
VAL_ 513 BptRngeRsrvMet_B_Stat 1 "Yes" 0 "No" ;
VAL_ 513 BptPwOut_B_Dsply 1 "Yes" 0 "No" ;
VAL_ 513 BptStrtStop_D_Stat 3 "NotUsed_1" 2 "Start" 1 "Stop" 0 "NoRequest" ;
VAL_ 513 BptComm_D_RqHtrn 9 "EnergyTransferFault" 8 "EnergyTransferEnd" 7 "VehicleEnergyTransferActv" 6 "VehicleEnergyTransferReady" 5 "VehiclePreChargeReady" 4 "VehicleEnergyTransferWait" 3 "ConfirmConnection" 2 "VehicleReadyToToggle" 1 "AttemptDgtlCommunication" 0 "NoDigitalCommunication" 15 "NotUsed_6" 14 "NotUsed_5" 13 "NotUsed_4" 12 "NotUsed_3" 11 "NotUsed_2" 10 "NotUsed_1" ;
VAL_ 513 BptSustn_B_Rq 1 "Active" 0 "Inactive" ;
VAL_ 513 GridSrvc01_B_Stat 1 "On" 0 "Off" ;
VAL_ 513 Bpt_D_StatHtrn 15 "Faulty" 14 "NotUsed_8" 13 "NotUsed_7" 12 "NotUsed_6" 11 "NotUsed_5" 10 "NotUsed_4" 9 "NotUsed_3" 8 "NotUsed_2" 7 "NotUsed_1" 6 "VehicleFault" 5 "EvseFault" 4 "BptActive" 3 "Precharge" 2 "BptReady" 1 "Initialization" 0 "NotReady" ;
VAL_ 513 BptMde_D_Stat 7 "NotUsed_4" 6 "NotUsed_3" 5 "NotUsed_2" 4 "NotUsed_1" 3 "Automatic" 2 "Manual" 1 "Off" 0 "Null" ;
VAL_ 513 BattTracTeColr_D_Dsply 3 "NotUsed" 2 "ColorForSeverlyLimited" 1 "ColorForLimited" 0 "ColorForNormal" ;
VAL_ 513 MtrTracTeColr_D_Dsply 3 "NotUsed" 2 "ColorForSeverlyLimited" 1 "ColorForLimited" 0 "ColorForNormal" ;
VAL_ 553 DistToChrgrBynd_L_Actl 511 "Faulty" 510 "NoDataExists" ;
VAL_ 553 CCOI_PolicyClient_St 15 "NotUsed_4" 14 "NotUsed_3" 13 "NotUsed_2" 12 "NotUsed_1" 11 "DataStorageError" 10 "StateMachineInconsistent" 9 "UnrecoverableSyncError" 8 "OnBoardSyncFailed" 7 "OnBoardImplemented" 6 "OnBoardSynchronized" 5 "OnBoardSynchronizing" 4 "OnBoardSyncNeeded" 3 "OffBoardUpdatePending" 2 "OnBoardUpdatePending" 1 "Waiting" 0 "Null" ;
VAL_ 553 ResetAvgFe_B_Rq 1 "Reset" 0 "Null" ;
VAL_ 553 ResetTrip2_B_Rq 1 "Reset" 0 "Null" ;
VAL_ 553 SndImmrsnLvl_D_Rq 255 "NotUsed_127" 254 "NotUsed_126" 253 "NotUsed_125" 252 "NotUsed_124" 251 "NotUsed_123" 250 "NotUsed_122" 249 "NotUsed_121" 248 "NotUsed_120" 247 "NotUsed_119" 246 "NotUsed_118" 245 "NotUsed_117" 244 "NotUsed_116" 243 "NotUsed_115" 242 "NotUsed_114" 241 "NotUsed_113" 240 "NotUsed_112" 239 "NotUsed_111" 238 "NotUsed_110" 237 "NotUsed_109" 236 "NotUsed_108" 235 "NotUsed_107" 234 "NotUsed_106" 233 "NotUsed_105" 232 "NotUsed_104" 231 "NotUsed_103" 230 "NotUsed_102" 229 "NotUsed_101" 228 "NotUsed_100" 227 "NotUsed_99" 226 "NotUsed_98" 225 "NotUsed_97" 224 "NotUsed_96" 223 "NotUsed_95" 222 "NotUsed_94" 221 "NotUsed_93" 220 "NotUsed_92" 219 "NotUsed_91" 218 "NotUsed_90" 217 "NotUsed_89" 216 "NotUsed_88" 215 "NotUsed_87" 214 "NotUsed_86" 213 "NotUsed_85" 212 "NotUsed_84" 211 "NotUsed_83" 210 "NotUsed_82" 209 "NotUsed_81" 208 "NotUsed_80" 207 "NotUsed_79" 206 "NotUsed_78" 205 "NotUsed_77" 204 "NotUsed_76" 203 "NotUsed_75" 202 "NotUsed_74" 201 "NotUsed_73" 200 "NotUsed_72" 199 "NotUsed_71" 198 "NotUsed_70" 197 "NotUsed_69" 196 "NotUsed_68" 195 "NotUsed_67" 194 "NotUsed_66" 193 "NotUsed_65" 192 "NotUsed_64" 191 "NotUsed_63" 190 "NotUsed_62" 189 "NotUsed_61" 188 "NotUsed_60" 187 "NotUsed_59" 186 "NotUsed_58" 185 "NotUsed_57" 184 "NotUsed_56" 183 "NotUsed_55" 182 "NotUsed_54" 181 "NotUsed_53" 180 "NotUsed_52" 179 "NotUsed_51" 178 "NotUsed_50" 177 "NotUsed_49" 176 "NotUsed_48" 175 "NotUsed_47" 174 "NotUsed_46" 173 "NotUsed_45" 172 "NotUsed_44" 171 "NotUsed_43" 170 "NotUsed_42" 169 "NotUsed_41" 168 "NotUsed_40" 167 "NotUsed_39" 166 "NotUsed_38" 165 "NotUsed_37" 164 "NotUsed_36" 163 "NotUsed_35" 162 "NotUsed_34" 161 "NotUsed_33" 160 "NotUsed_32" 159 "NotUsed_31" 158 "NotUsed_30" 157 "NotUsed_29" 156 "NotUsed_28" 155 "NotUsed_27" 154 "NotUsed_26" 153 "NotUsed_25" 152 "NotUsed_24" 151 "NotUsed_23" 150 "NotUsed_22" 149 "NotUsed_21" 148 "NotUsed_20" 147 "NotUsed_19" 146 "NotUsed_18" 145 "NotUsed_17" 144 "NotUsed_16" 143 "NotUsed_15" 142 "NotUsed_14" 141 "NotUsed_13" 140 "NotUsed_12" 139 "NotUsed_11" 138 "NotUsed_10" 137 "NotUsed_9" 136 "NotUsed_8" 135 "NotUsed_7" 134 "NotUsed_6" 133 "NotUsed_5" 132 "NotUsed_4" 131 "NotUsed_3" 130 "NotUsed_2" 129 "NotUsed_1" 128 "Level127" 127 "Level126" 126 "Level125" 125 "Level124" 124 "Level123" 123 "Level122" 122 "Level121" 121 "Level120" 120 "Level119" 119 "Level118" 118 "Level117" 117 "Level116" 116 "Level115" 115 "Level114" 114 "Level113" 113 "Level112" 112 "Level111" 111 "Level110" 110 "Level109" 109 "Level108" 108 "Level107" 107 "Level106" 106 "Level105" 105 "Level104" 104 "Level103" 103 "Level102" 102 "Level101" 101 "Level100" 100 "Level99" 99 "Level98" 98 "Level97" 97 "Level96" 96 "Level95" 95 "Level94" 94 "Level93" 93 "Level92" 92 "Level91" 91 "Level90" 90 "Level89" 89 "Level88" 88 "Level87" 87 "Level86" 86 "Level85" 85 "Level84" 84 "Level83" 83 "Level82" 82 "Level81" 81 "Level80" 80 "Level79" 79 "Level78" 78 "Level77" 77 "Level76" 76 "Level75" 75 "Level74" 74 "Level73" 73 "Level72" 72 "Level71" 71 "Level70" 70 "Level69" 69 "Level68" 68 "Level67" 67 "Level66" 66 "Level65" 65 "Level64" 64 "Level63" 63 "Level62" 62 "Level61" 61 "Level60" 60 "Level59" 59 "Level58" 58 "Level57" 57 "Level56" 56 "Level55" 55 "Level54" 54 "Level53" 53 "Level52" 52 "Level51" 51 "Level50" 50 "Level49" 49 "Level48" 48 "Level47" 47 "Level46" 46 "Level45" 45 "Level44" 44 "Level43" 43 "Level42" 42 "Level41" 41 "Level40" 40 "Level39" 39 "Level38" 38 "Level37" 37 "Level36" 36 "Level35" 35 "Level34" 34 "Level33" 33 "Level32" 32 "Level31" 31 "Level30" 30 "Level29" 29 "Level28" 28 "Level27" 27 "Level26" 26 "Level25" 25 "Level24" 24 "Level23" 23 "Level22" 22 "Level21" 21 "Level20" 20 "Level19" 19 "Level18" 18 "Level17" 17 "Level16" 16 "Level15" 15 "Level14" 14 "Level13" 13 "Level12" 12 "Level11" 11 "Level10" 10 "Level9" 9 "Level8" 8 "Level7" 7 "Level6" 6 "Level5" 5 "Level4" 4 "Level3" 3 "Level2" 2 "Level1" 1 "Level0" 0 "Inactive" ;
VAL_ 553 InfoSysMasterPw_D_Stat 7 "NotUsed_6" 6 "NotUsed_5" 5 "NotUsed_4" 4 "NotUsed_3" 0 "Inactive" 1 "On" 2 "NotUsed_1" 3 "NotUsed_2" ;
VAL_ 553 ResetTrip1_B_Rq 1 "Reset" 0 "Null" ;
VAL_ 553 Disp_LangSel2_St 33 "Ukrainian" 32 "Indian_English" 31 "Thai" 30 "Slovak" 29 "Arabic" 28 "Taiwanese" 27 "Mandarin_Chinese" 26 "Korean" 25 "AU_English" 24 "Japanese" 23 "Braz_Portuguese" 22 "EU_Portuguese" 21 "Finish" 20 "Norwegian" 19 "Danish" 18 "Swedish" 17 "Hungarian" 16 "Greek" 15 "Czech" 14 "Polish" 13 "Flemish" 12 "Dutch" 11 "Russian" 10 "Turkish" 9 "Mex_Spanish" 8 "EU_Spanish" 7 "Cana_French" 6 "EU_French" 5 "Italian" 4 "German" 3 "NA_English" 2 "UK_English" 1 "Unknown" 0 "Invalid" ;
VAL_ 553 Disp_LangSel_St 31 "Thai" 30 "Slovak" 29 "Arabic" 28 "Taiwanese" 27 "Mandarin_Chinese" 26 "Korean" 25 "AU_English" 24 "Japanese" 23 "Braz_Portuguese" 22 "EU_Portuguese" 21 "Finish" 20 "Norwegian" 19 "Danish" 18 "Swedish" 17 "Hungarian" 16 "Greek" 15 "Czech" 14 "Polish" 13 "Flemish" 12 "Dutch" 11 "Russian" 10 "Turkish" 9 "Mex_Spanish" 8 "EU_Spanish" 7 "Cana_French" 6 "EU_French" 5 "Italian" 4 "German" 3 "NA_English" 2 "UK_English" 1 "Unknown" 0 "Invalid" ;
VAL_ 553 Diagnostic_Operation_Rq 7 "SignalStrength" 6 "SDARSESNNumber" 5 "SpeakerWalkAround" 4 "CalibrationPartNumber" 15 "Reserved" 3 "HardwarePartNumber" 2 "SoftwarePartNumber" 1 "GetAllBackgroundDiagRq" 0 "Inactive" ;
VAL_ 553 Bezel_Diag_Module_Rq 15 "Reserved" 3 "EFP" 2 "DSP_AMP" 1 "AHU" 0 "Inactive" ;
VAL_ 553 Audio_Demo_CMND 2 "On" 1 "Off" 0 "Inactive" ;
VAL_ 553 Audio_Visualizer 2 "On" 1 "Off" 0 "Inactive" ;
VAL_ 553 Surround_Sound_Upmix 2 "Surround" 1 "Stereo" 0 "Inactive" ;
VAL_ 553 Bezel_Diag_State_Rq 1 "Active" 0 "Inactive" ;
VAL_ 553 SurndSndUpmix2_D_Rq 4 "Audience" 3 "On_Stage" 2 "Surround" 1 "Stereo" 0 "Inactive" ;
VAL_ 897 VehElAvgTrip2_Eff_Dsply 127 "Faulty" 126 "NoDataExists" ;
VAL_ 897 Trip2SumDrvE_Pc_Dsply 1023 "Faulty" 1022 "NoDataExists" ;
VAL_ 897 Trip2ExtFctrE_Pc_Dsply 1023 "Faulty" 1022 "NoDataExists" ;
VAL_ 897 Trip2ClimE_Pc_Dsply 1023 "Faulty" 1022 "NoDataExists" ;
VAL_ 897 Trip2BattULoE_Pc_Dsply 1023 "Faulty" 1022 "NoDataExists" ;
VAL_ 878 LowFuelDsplyType_B_Rq 1 "Volume" 0 "Miles" ;
VAL_ 878 PwBedPnlEnblScnd_B_Rq 1 "Enable" 0 "Disable" ;
VAL_ 878 DcacSysScnd_B_Falt 1 "Yes" 0 "No" ;
VAL_ 878 DcacOnScnd_B_Rq 1 "Enable" 0 "Disable" ;
VAL_ 878 DcacGfciTestScnd_B_Rq 1 "Pressed" 0 "Not_Pressed" ;
VAL_ 878 EngExhMdeHrStrt_D_Stat 31 "NotUsed_7" 30 "NotUsed_6" 29 "NotUsed_5" 28 "NotUsed_4" 27 "NotUsed_3" 26 "NotUsed_2" 25 "NotUsed_1" 24 "Hour23_11pm" 23 "Hour22_10pm" 22 "Hour21_9pm" 21 "Hour20_8pm" 20 "Hour19_7pm" 19 "Hour18_6pm" 18 "Hour17_5pm" 17 "Hour16_4pm" 16 "Hour15_3pm" 15 "Hour14_2pm" 14 "Hour13_1pm" 13 "Hour12_12pm" 12 "Hour11_11am" 11 "Hour10_10am" 10 "Hour9_9am" 9 "Hour8_8am" 8 "Hour7_7am" 7 "Hour6_6am" 6 "Hour5_5am" 5 "Hour4_4am" 4 "Hour3_3am" 3 "Hour2_2am" 2 "Hour1_1am" 1 "Hour0_12am" 0 "Null" ;
VAL_ 878 EngExhMdeHrEnd_D_Stat 31 "NotUsed_7" 30 "NotUsed_6" 29 "NotUsed_5" 28 "NotUsed_4" 27 "NotUsed_3" 26 "NotUsed_2" 25 "NotUsed_1" 24 "Hour23_11pm" 23 "Hour22_10pm" 22 "Hour21_9pm" 21 "Hour20_8pm" 20 "Hour19_7pm" 19 "Hour18_6pm" 18 "Hour17_5pm" 17 "Hour16_4pm" 16 "Hour15_3pm" 15 "Hour14_2pm" 14 "Hour13_1pm" 13 "Hour12_12pm" 12 "Hour11_11am" 11 "Hour10_10am" 10 "Hour9_9am" 9 "Hour8_8am" 8 "Hour7_7am" 7 "Hour6_6am" 6 "Hour5_5am" 5 "Hour4_4am" 4 "Hour3_3am" 3 "Hour2_2am" 2 "Hour1_1am" 1 "Hour0_12am" 0 "Null" ;
VAL_ 878 EngExhMdeHrEnbl_D_Stat 3 "NotUsed" 2 "Enabled" 1 "Disabled" 0 "Null" ;
VAL_ 878 DcacGfciTest_B_Rq 1 "Pressed" 0 "Not_Pressed" ;
VAL_ 878 DcacOut_Pw_DsplyMx 1023 "Faulty" ;
VAL_ 878 DcacOut1_Pw_Dsply 63 "Faulty" ;
VAL_ 878 DcacOut2_Pw_Dsply 63 "Faulty" ;
VAL_ 878 DcacHw_D_Confg 15 "NotUsed_11" 14 "NotUsed_10" 13 "NotUsed_9" 12 "NotUsed_8" 11 "NotUsed_7" 10 "NotUsed_6" 9 "NotUsed_5" 8 "NotUsed_4" 7 "NotUsed_3" 6 "NotUsed_2" 5 "Dual_2400WAnd7200W" 4 "Power_2300W" 3 "Power_7200W" 2 "Power_2400W" 1 "Power_2000W" 0 "NoDcacHardware" ;
VAL_ 878 DcacFaltMsgTxt_D_Rq 15 "HvacOn" 14 "OvercurrentLP" 13 "EngineRun" 12 "Service" 11 "NotAvailable" 10 "PlugWarn" 9 "PlugWarnDrive" 8 "BreakerC" 7 "BreakerB" 6 "BreakerA" 5 "FuelLow" 4 "AcOnOutput" 3 "Temperature" 2 "Gfci" 1 "Overcurrent" 0 "Ok" ;
VAL_ 878 DcacLoFuelMsgTxt_D_Rq 31 "Minute_31" 30 "Minute_30" 29 "Minute_29" 28 "Minute_28" 27 "Minute_27" 26 "Minute_26" 25 "Minute_25" 24 "Minute_24" 23 "Minute_23" 22 "Minute_22" 21 "Minute_21" 20 "Minute_20" 19 "Minute_19" 18 "Minute_18" 17 "Minute_17" 16 "Minute_16" 15 "Minute_15" 14 "Minute_14" 13 "Minute_13" 12 "Minute_12" 11 "Minute_11" 10 "Minute_10" 9 "Minute_9" 8 "Minute_8" 7 "Minute_7" 6 "Minute_6" 5 "Minute_5" 4 "Minute_4" 3 "Minute_3" 2 "Minute_2" 1 "Minute_1" 0 "Ok" ;
VAL_ 878 DcacEngOnMsgTxt_D_Rq 3 "NotUsed" 2 "DisplayQuestion" 1 "DisplayWarning" 0 "Ok" ;
VAL_ 878 DcacElPw_D_Stat 3 "NotUsed" 2 "High" 1 "Low" 0 "Off" ;
VAL_ 878 PwBedPnlEnbl_B_Rq 1 "Enable" 0 "Disable" ;
VAL_ 878 DcacOn_B_Rq 1 "Enable" 0 "Disable" ;
VAL_ 878 DcacSys_B_Falt 1 "Yes" 0 "No" ;
VAL_ 878 DcacLedCtl_D_Rq 3 "Fast_Flash" 2 "Slow_Flash" 1 "On" 0 "Off" ;
VAL_ 924 DcacTrnkFrnt_I_Actl 65535 "Faulty" 65534 "NoDataExists" ;
VAL_ 924 DcacOut_Pw_Mx 2047 "Faulty" 2046 "NoDataExists" ;
VAL_ 924 DcacOut2_Pw_Actl 8191 "Faulty" 8190 "NoDataExists" ;
VAL_ 924 DcacOut1_Pw_Actl 8191 "Faulty" 8190 "NoDataExists" ;
VAL_ 924 DcacIn_Pw_Mx 2047 "Faulty" 2046 "NoDataExists" ;
VAL_ 923 DcacIn_U3_Actl 4095 "Faulty" 4094 "NoDataExists" ;
VAL_ 923 DcacIn_U2_Actl 4095 "Faulty" 4094 "NoDataExists" ;
VAL_ 923 DcacIn_U_Actl 4095 "Fault" 4094 "NoDataExists" ;
VAL_ 923 DcacIn_I_Actl 2047 "Faulty" 2046 "NoDataExists" ;
VAL_ 923 Dcac_Te_Actl 255 "Faulty" 254 "NoDataExists" ;
VAL_ 896 BptDly_T_Actl 63 "Faulty" 62 "NoDataExists" ;
VAL_ 896 VehElAvgTrip1_Eff_Dsply 127 "Faulty" 126 "NoDataExists" ;
VAL_ 896 Trip1SumDrvE_Pc_Dsply 1023 "Faulty" 1022 "NoDataExists" ;
VAL_ 896 Trip1ExtFctrE_Pc_Dsply 1023 "Faulty" 1022 "NoDataExists" ;
VAL_ 896 Trip1ClimE_Pc_Dsply 1023 "Faulty" 1022 "NoDataExists" ;
VAL_ 896 Trip1BattULoE_Pc_Dsply 1023 "Faulty" 1022 "NoDataExists" ;
VAL_ 922 PlgOutlet8Prsnt_B_Stat 1 "Yes" 0 "No" ;
VAL_ 922 PlgOutlet7Prsnt_B_Stat 1 "Yes" 0 "No" ;
VAL_ 922 PlgOutlet6Prsnt_B_Stat 1 "Yes" 0 "No" ;
VAL_ 922 TrnkPlgFrontPrsnt_B_St 1 "Yes" 0 "No" ;
VAL_ 922 CabnPlgPrsnt_B_Stat 1 "Yes" 0 "No" ;
VAL_ 922 DcacOverTe_B_Falt 1 "Faulted" 0 "NotFaulted" ;
VAL_ 922 DcacRdy_D2_Stat 3 "Faulted" 2 "RecoverableFault" 1 "Active" 0 "Idle" ;
VAL_ 922 DcacOvrld_B_Falt 1 "Faulted" 0 "NotFaulted" ;
VAL_ 922 DcacIpRcBrkrOpn_B_Falt 1 "Faulted" 0 "NotFaulted" ;
VAL_ 922 DcacGfci_B_Falt 1 "Faulted" 0 "NotFaulted" ;
VAL_ 922 DcacErr_B_Stat 1 "Faulted" 0 "NotFaulted" ;
VAL_ 922 DcacBp2BrkrOpn_B_Falt 1 "Faulted" 0 "NotFaulted" ;
VAL_ 922 DcacBp1BrkrOpn_B_Falt 1 "Faulted" 0 "NotFaulted" ;
VAL_ 922 DcacAcUDetct_B_Falt 1 "Faulted" 0 "NotFaulted" ;
VAL_ 922 DcacRdy_D_Stat 7 "NotUsed_2" 6 "NotUsed_1" 5 "Faulted" 4 "ProtectionTempearture" 3 "ProtectionOverload" 2 "ProtectionGfci" 1 "Active" 0 "Idle" ;
VAL_ 922 DcacPlugPrsnt_B_Stat 1 "Yes" 0 "No" ;
VAL_ 922 DcacClntFlw_D_Rq 3 "High" 2 "Medium" 1 "Low" 0 "Off" ;
VAL_ 922 CoolFanDcac_D_Rq 3 "High" 2 "Medium" 1 "Low" 0 "Off" ;
